VERSION ""

NS_ :

BS_:

BU_: HCM_FD IPMA_ADAS PSCM_FD ABS_ESC TCCM_FD TCM_DSL_FD PCM_HEV_FD PCM_FD ECM_Diesel GENERIC_GWMWakeup GWM_ECG _delete TSTR

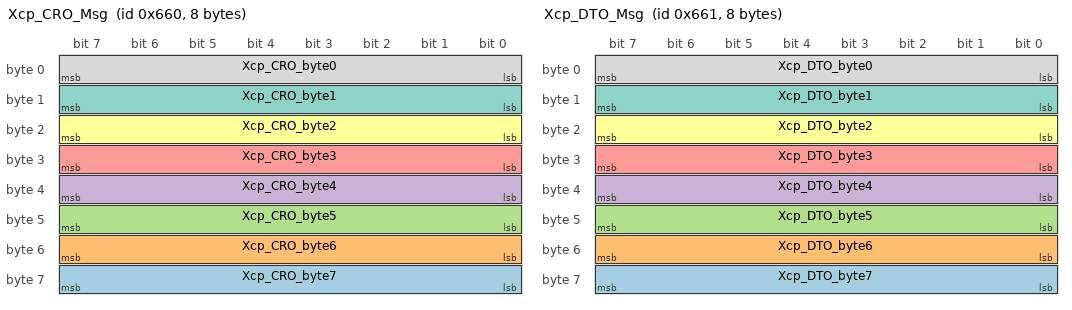
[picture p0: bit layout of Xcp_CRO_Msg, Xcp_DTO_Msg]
BO_ 1632 Xcp_CRO_Msg: 8 Vector__XXX
 SG_ Xcp_CRO_byte7 : 63|8@0- (1,0) [0|255] ""  PSCM_FD
 SG_ Xcp_CRO_byte6 : 55|8@0- (1,0) [0|255] ""  PSCM_FD
 SG_ Xcp_CRO_byte5 : 47|8@0- (1,0) [0|255] ""  PSCM_FD
 SG_ Xcp_CRO_byte4 : 39|8@0- (1,0) [0|255] ""  PSCM_FD
 SG_ Xcp_CRO_byte3 : 31|8@0- (1,0) [0|255] ""  PSCM_FD
 SG_ Xcp_CRO_byte2 : 23|8@0- (1,0) [0|255] ""  PSCM_FD
 SG_ Xcp_CRO_byte1 : 15|8@0- (1,0) [0|255] ""  PSCM_FD
 SG_ Xcp_CRO_byte0 : 7|8@0- (1,0) [0|255] ""  PSCM_FD

BO_ 1633 Xcp_DTO_Msg: 8 PSCM_FD
 SG_ Xcp_DTO_byte7 : 63|8@0- (1,0) [0|255] "" Vector__XXX
 SG_ Xcp_DTO_byte6 : 55|8@0- (1,0) [0|255] "" Vector__XXX
 SG_ Xcp_DTO_byte5 : 47|8@0- (1,0) [0|255] "" Vector__XXX
 SG_ Xcp_DTO_byte4 : 39|8@0- (1,0) [0|255] "" Vector__XXX
 SG_ Xcp_DTO_byte3 : 31|8@0- (1,0) [0|255] "" Vector__XXX
 SG_ Xcp_DTO_byte2 : 23|8@0- (1,0) [0|255] "" Vector__XXX
 SG_ Xcp_DTO_byte1 : 15|8@0- (1,0) [0|255] "" Vector__XXX
 SG_ Xcp_DTO_byte0 : 7|8@0- (1,0) [0|255] "" Vector__XXX

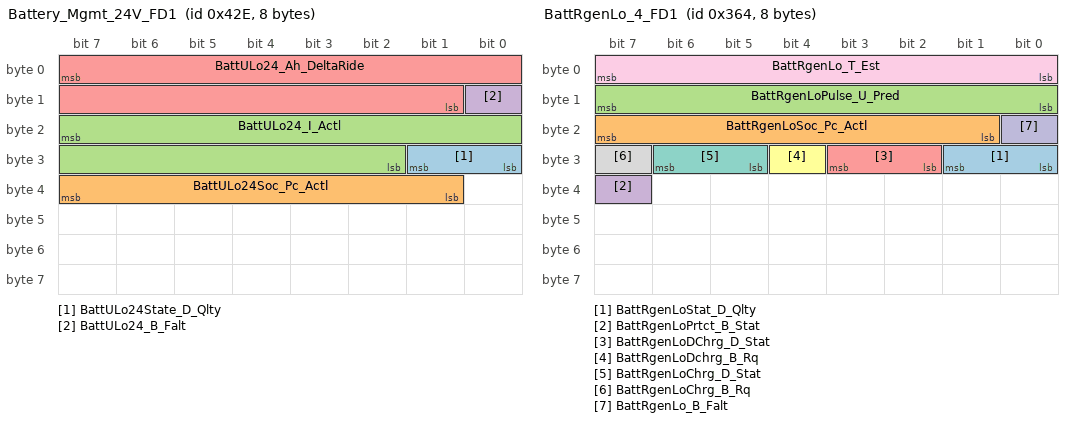
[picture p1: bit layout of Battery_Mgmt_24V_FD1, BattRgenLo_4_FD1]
BO_ 1070 Battery_Mgmt_24V_FD1: 8 GWM_ECG
 SG_ BattULo24State_D_Qlty : 25|2@0+ (1,0) [0|3] "SE"  PCM_FD
 SG_ BattULo24Soc_Pc_Actl : 39|7@0+ (1,0) [0|127] "percent"  PCM_FD
 SG_ BattULo24_I_Actl : 23|14@0+ (0.0625,-512) [-512|511.875] "ampere"  PCM_FD
 SG_ BattULo24_B_Falt : 8|1@0+ (1,0) [0|1] "SED"  PCM_FD
 SG_ BattULo24_Ah_DeltaRide : 7|15@0+ (0.0078125,-100) [-100|155.9921875] "amperehour"  PCM_FD

BO_ 868 BattRgenLo_4_FD1: 8 GWM_ECG
 SG_ BattRgenLoStat_D_Qlty : 25|2@0+ (1,0) [0|3] "SED" Vector__XXX
 SG_ BattRgenLoSoc_Pc_Actl : 23|7@0+ (1,0) [0|100] "percent" Vector__XXX
 SG_ BattRgenLoPulse_U_Pred : 15|8@0+ (0.0625,0) [0|15.9375] "volt" Vector__XXX
 SG_ BattRgenLoPrtct_B_Stat : 39|1@0+ (1,0) [0|1] "SED" Vector__XXX
 SG_ BattRgenLoDChrg_D_Stat : 27|2@0+ (1,0) [0|3] "SED" Vector__XXX
 SG_ BattRgenLoDchrg_B_Rq : 28|1@0+ (1,0) [0|1] "SED" Vector__XXX
 SG_ BattRgenLoChrg_D_Stat : 30|2@0+ (1,0) [0|3] "SED" Vector__XXX
 SG_ BattRgenLoChrg_B_Rq : 31|1@0+ (1,0) [0|1] "SED" Vector__XXX
 SG_ BattRgenLo_T_Est : 7|8@0+ (8,0) [0|2040] "second" Vector__XXX
 SG_ BattRgenLo_B_Falt : 16|1@0+ (1,0) [0|1] "SED" Vector__XXX

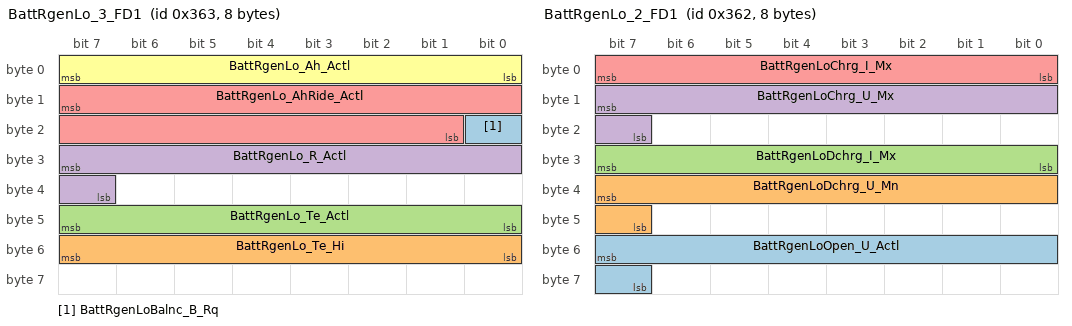
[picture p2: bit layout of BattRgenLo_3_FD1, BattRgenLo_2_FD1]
BO_ 867 BattRgenLo_3_FD1: 8 GWM_ECG
 SG_ BattRgenLoBalnc_B_Rq : 16|1@0+ (1,0) [0|1] "SED" Vector__XXX
 SG_ BattRgenLo_Te_Hi : 55|8@0+ (1,-20) [-20|235] "degC" Vector__XXX
 SG_ BattRgenLo_Te_Actl : 47|8@0+ (1,-60) [-60|194] "degC" Vector__XXX
 SG_ BattRgenLo_R_Actl : 31|9@0+ (0.0625,0) [0|31.9375] "milliohm" Vector__XXX
 SG_ BattRgenLo_AhRide_Actl : 15|15@0+ (0.0078125,-100) [-100|155.9921875] "amperehour" Vector__XXX
 SG_ BattRgenLo_Ah_Actl : 7|8@0+ (0.1,0) [0|25.5] "amperehour" Vector__XXX

BO_ 866 BattRgenLo_2_FD1: 8 GWM_ECG
 SG_ BattRgenLoOpen_U_Actl : 55|9@0+ (0.025,8.5) [8.5|21.275] "volt" Vector__XXX
 SG_ BattRgenLoDchrg_U_Mn : 39|9@0+ (0.025,4) [4|16.775] "volt" Vector__XXX
 SG_ BattRgenLoDchrg_I_Mx : 31|8@0+ (2,0) [0|510] "ampere" Vector__XXX
 SG_ BattRgenLoChrg_U_Mx : 15|9@0+ (0.025,10.6) [10.6|23.375] "volt" Vector__XXX
 SG_ BattRgenLoChrg_I_Mx : 7|8@0+ (2,0) [0|510] "ampere" Vector__XXX

BO_ 865 BattRgenLo_1_FD1: 8 GWM_ECG
 SG_ BattRgenLo_U_Actl : 23|11@0+ (0.015625,0) [0|31.96875] "volt" Vector__XXX
 SG_ BattRgenLo_I_Actl : 7|16@0+ (0.015625,-512) [-512|511.96875] "ampere" Vector__XXX

BO_ 878 DCACA_Data4: 8 PCM_HEV_FD
 SG_ DcacOn_B_Rq : 4|1@0+ (1,0) [0|1] "SED"  GWM_ECG
 SG_ DcacSys_B_Falt : 5|1@0+ (1,0) [0|1] "SED"  GWM_ECG
 SG_ DcacLedCtl_D_Rq : 7|2@0+ (1,0) [0|3] "SED"  GWM_ECG

BO_ 924 DCACA_Data3_FD1: 8 GWM_ECG
 SG_ DcacOut_Pw_Mx : 34|11@0+ (5,0) [0|10225] "watts"  PCM_HEV_FD,PCM_FD
 SG_ DcacOut2_Pw_Actl : 31|13@0+ (1,0) [0|8189] "watts"  PCM_HEV_FD,PCM_FD
 SG_ DcacOut1_Pw_Actl : 12|13@0+ (1,0) [0|8189] "watts"  PCM_HEV_FD,PCM_FD
 SG_ DcacIn_Pw_Mx : 7|11@0+ (5,0) [0|10225] "watts"  PCM_HEV_FD,PCM_FD

BO_ 923 DCACA_Data2_FD1: 8 GWM_ECG
 SG_ DcacIn_U_Actl : 19|12@0+ (0.1,0) [0|409.3] "volt"  PCM_HEV_FD,PCM_FD
 SG_ DcacIn_I_Actl : 15|11@0+ (5,0) [0|10225] "watts"  PCM_HEV_FD,PCM_FD
 SG_ Dcac_Te_Actl : 7|8@0+ (1,-60) [-60|193] "degC"  PCM_HEV_FD,PCM_FD

BO_ 922 DCACA_Data1_FD1: 8 GWM_ECG
 SG_ DcacRdy_D_Stat : 2|3@0+ (1,0) [0|7] "SED"  PCM_HEV_FD,PCM_FD
 SG_ DcacPlugPrsnt_B_Stat : 3|1@0+ (1,0) [0|1] "SED"  PCM_HEV_FD,PCM_FD
 SG_ DcacClntFlw_D_Rq : 5|2@0+ (1,0) [0|3] "SED" Vector__XXX
 SG_ CoolFanDcac_D_Rq : 7|2@0+ (1,0) [0|3] "SED" Vector__XXX

BO_ 2030 TesterPhysicalResSOBDMCFD1: 64 ECM_Diesel
 SG_ TesterPhysicalResSOBDMC : 7|64@0+ (1,0) [0|1.84467E+019] "unitless"  TSTR

BO_ 1137 Cluster_HEV_Data10_FD1: 8 PCM_HEV_FD
 SG_ RngPerChrgAvg_L_Dsply : 7|12@0+ (0.1,0) [0|409.3] "km"  GWM_ECG

BO_ 1090 MtrTrac_Data2_FD1: 8 PCM_HEV_FD
 SG_ VehElRnge_L_Dsply : 28|12@0+ (0.1,0) [0|409.3] "kilometer"  GWM_ECG

BO_ 872 Cluster_HEV_Data5_FD1: 8 PCM_HEV_FD
 SG_ PlgActvArb_B_Dsply : 51|1@0+ (1,0) [0|1] "SED"  GWM_ECG
 SG_ HybMdeStat_D_Dsply : 39|3@0+ (1,0) [0|7] "SED"  GWM_ECG

BO_ 870 Cluster_HEV_Data3_FD1: 8 PCM_HEV_FD
 SG_ RngPerChrgInst_L_Dsply : 45|12@0+ (0.1,0) [0|409.3] "km"  GWM_ECG

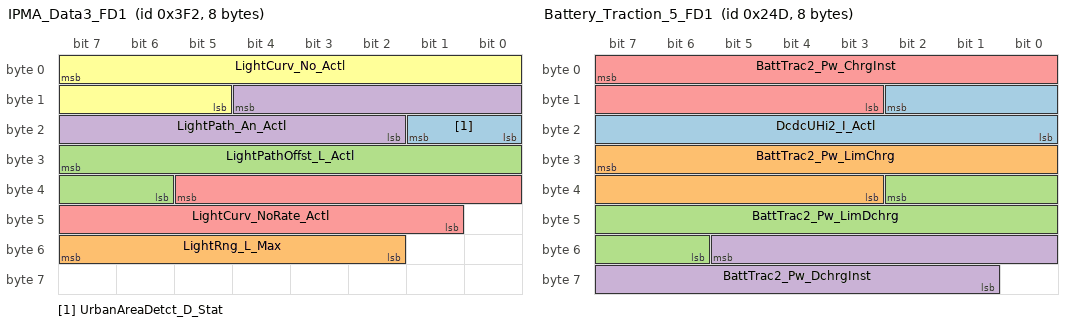
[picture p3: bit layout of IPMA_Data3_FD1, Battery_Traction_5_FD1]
BO_ 1010 IPMA_Data3_FD1: 8 IPMA_ADAS
 SG_ UrbanAreaDetct_D_Stat : 17|2@0+ (1,0) [0|3] "SED"  HCM_FD
 SG_ LightRng_L_Max : 55|6@0+ (2,0) [0|126] "meter"  HCM_FD
 SG_ LightPathOffst_L_Actl : 31|10@0+ (0.01,-5.12) [-5.12|5.11] "meter"  HCM_FD
 SG_ LightPath_An_Actl : 12|11@0+ (0.0005,-0.5) [-0.5|0.5235] "radians"  HCM_FD
 SG_ LightCurv_NoRate_Actl : 37|13@0+ (2.5E-007,-0.001024) [-0.001024|0.00102375] "1/meter"  HCM_FD
 SG_ LightCurv_No_Actl : 7|11@0+ (2E-005,-0.02) [-0.02|0.02094] "1/meter"  HCM_FD

BO_ 589 Battery_Traction_5_FD1: 8 GWM_ECG
 SG_ DcdcUHi2_I_Actl : 10|11@0+ (0.1,0) [0|204.6] "ampere" Vector__XXX
 SG_ BattTrac2_Pw_LimChrg : 31|13@0+ (50,0) [0|409550] "watts"  PCM_HEV_FD
 SG_ BattTrac2_Pw_LimDchrg : 34|13@0+ (50,0) [0|409550] "watts"  PCM_HEV_FD
 SG_ BattTrac2_Pw_DchrgInst : 53|13@0+ (50,0) [0|409550] "watts"  PCM_HEV_FD
 SG_ BattTrac2_Pw_ChrgInst : 7|13@0+ (50,0) [0|409550] "watts"  PCM_HEV_FD

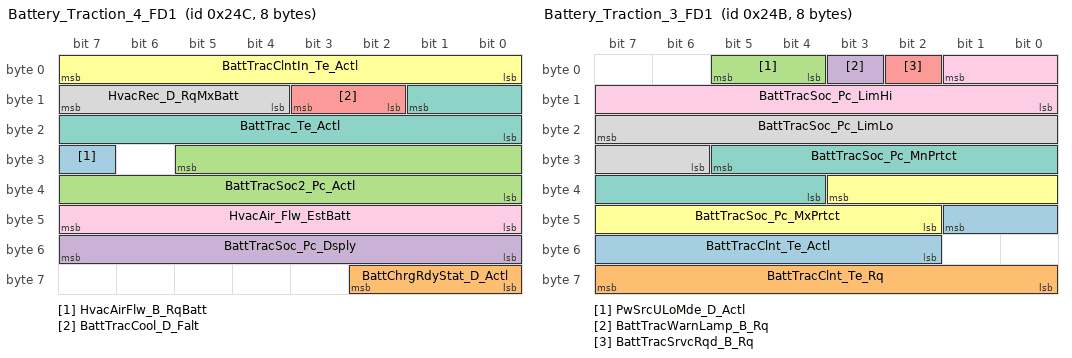
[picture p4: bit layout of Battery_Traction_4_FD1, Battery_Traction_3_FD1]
BO_ 588 Battery_Traction_4_FD1: 8 GWM_ECG
 SG_ HvacAirFlw_B_RqBatt : 31|1@0+ (1,0) [0|1] "SED" Vector__XXX
 SG_ BattChrgRdyStat_D_Actl : 58|3@0+ (1,0) [0|7] "SED" Vector__XXX
 SG_ BattTracSoc2_Pc_Actl : 29|14@0+ (0.01,0) [0|163.81] "%"  PCM_HEV_FD
 SG_ BattTracSoc_Pc_Dsply : 55|8@0+ (0.5,0) [0|126.5] "Percent" Vector__XXX
 SG_ BattTracCool_D_Falt : 11|2@0+ (1,0) [0|3] "SED" Vector__XXX
 SG_ BattTracClntIn_Te_Actl : 7|8@0+ (1,-50) [-50|204] "degC" Vector__XXX
 SG_ BattTrac_Te_Actl : 9|10@0+ (0.5,-50) [-50|460.5] "degC"  PCM_HEV_FD
 SG_ HvacRec_D_RqMxBatt : 15|4@0+ (1,0) [0|15] "SED" Vector__XXX
 SG_ HvacAir_Flw_EstBatt : 47|8@0+ (0.5,0) [0|127] "liter/second" Vector__XXX

BO_ 587 Battery_Traction_3_FD1: 8 GWM_ECG
 SG_ BattTracClnt_Te_Actl : 41|8@0+ (0.5,-60) [-60|67.5] "degC" Vector__XXX
 SG_ BattTracClnt_Te_Rq : 63|8@0+ (0.5,-60) [-60|67.5] "degC" Vector__XXX
 SG_ PwSrcULoMde_D_Actl : 5|2@0+ (1,0) [0|3] "SED" Vector__XXX
 SG_ BattTracWarnLamp_B_Rq : 3|1@0+ (1,0) [0|1] "SED" Vector__XXX
 SG_ BattTracSrvcRqd_B_Rq : 2|1@0+ (1,0) [0|1] "SED" Vector__XXX
 SG_ BattTracSoc_Pc_MxPrtct : 35|10@0+ (0.1,0) [0|100] "%"  PCM_HEV_FD
 SG_ BattTracSoc_Pc_MnPrtct : 29|10@0+ (0.1,0) [0|100] "%"  PCM_HEV_FD
 SG_ BattTracSoc_Pc_LimLo : 23|10@0+ (0.1,0) [0|100] "%"  PCM_HEV_FD
 SG_ BattTracSoc_Pc_LimHi : 1|10@0+ (0.1,0) [0|100] "%"  PCM_HEV_FD

BO_ 1116 TrailerAid_Data3_FD1: 8 GWM_ECG
 SG_ TrlrAidSetup_D2_Rq : 4|4@0+ (1,0) [0|15] "SED"  IPMA_ADAS,PSCM_FD
 SG_ TrlrAidEnbl_D2_Rq : 7|3@0+ (1,0) [0|7] "SED"  PSCM_FD,IPMA_ADAS

BO_ 1844 TesterPhysicalReqHCM_FD1: 64 TSTR
 SG_ TesterPhysicalReqHCM : 7|64@0+ (1,0) [0|1.84467E+019] "unitless"  HCM_FD

BO_ 954 Body_Info_10_FD1: 8 GWM_ECG
 SG_ GenericSwtch3_No_Actl : 15|3@0+ (1,0) [0|7] "unitless"  HCM_FD
 SG_ GenericSwtch2_No_Actl : 4|3@0+ (1,0) [0|7] "unitless"  HCM_FD
 SG_ GenericSwtch1_No_Actl : 7|3@0+ (1,0) [0|7] "unitless"  HCM_FD

BO_ 1852 TesterPhysicalResHCM_FD1: 64 HCM_FD
 SG_ TesterPhysicalResHCM : 7|64@0+ (1,0) [0|1.84467E+019] "unitless"  TSTR

BO_ 989 Personality_HCM_FD1_Data: 8 HCM_FD
 SG_ FeatNoHcm_No_Actl : 23|16@0+ (1,0) [0|65535] "Number"  GWM_ECG
 SG_ FeatConfigHcmActl : 7|16@0+ (1,0) [0|65535] "Undefined"  GWM_ECG

BO_ 1006 Personality_IPMB_Data_FD1: 8 IPMA_ADAS
 SG_ PersIndexIpmb_D_Actl : 39|3@0+ (1,0) [0|7] "SED"  GWM_ECG
 SG_ FeatNoIpmbActl : 23|16@0+ (1,0) [0|65535] "Number"  GWM_ECG
 SG_ FeatConfigIpmbActl : 7|16@0+ (1,0) [0|65535] "Undefined"  GWM_ECG

BO_ 992 Personality_Data_FD1: 8 GWM_ECG
 SG_ MsgCntrPersIndex_D_Rq : 39|3@0+ (1,0) [0|7] "SED"  IPMA_ADAS,HCM_FD
 SG_ MsgCntrFeatConfigRq : 23|16@0+ (1,0) [0|65535] "unitless"  HCM_FD,IPMA_ADAS
 SG_ MsgCntrFeatNoRq : 7|16@0+ (1,0) [0|65535] "Number"  IPMA_ADAS,HCM_FD
 SG_ MsgCntrDsplyOp_D_Rq : 36|3@0+ (1,0) [0|7] "SED"  HCM_FD,IPMA_ADAS

BO_ 820 Adaptive_Headlamp_Stat_FD1: 8 HCM_FD
 SG_ AhbStatGfhbFdbk_D_Actl : 53|2@0+ (1,0) [0|3] "SED"  IPMA_ADAS
 SG_ HeadLghtDrvSide_B_Stat : 33|1@0+ (1,0) [0|1] "SED"  IPMA_ADAS
 SG_ HeadLghtHiOn_B_StatHcm : 0|1@0+ (1,0) [0|1] "SED"  GWM_ECG
 SG_ Adaptive_Hdlmp_Fault : 7|1@0+ (1,0) [0|1] "SED"  GWM_ECG,IPMA_ADAS

BO_ 1630 TesterPhysicalReqPSCM_FD1: 64 TSTR
 SG_ TesterPhysicalReqPSCM : 7|64@0+ (1,0) [0|1.84467E+019] "unitless"  PSCM_FD

BO_ 1713 ABS_Rapid_Data_Resp_2_FD1: 8 ABS_ESC
 SG_ UUDTABSResponse2 : 7|64@0+ (1,0) [0|1.844674407371E+019] "unitless"  GWM_ECG,TSTR

BO_ 1712 ABS_Rapid_Data_Resp_1_FD1: 8 ABS_ESC
 SG_ UUDTABSResponse1 : 7|64@0+ (1,0) [0|1.844674407371E+019] "unitless"  GWM_ECG,TSTR

BO_ 2025 TesterPhysicalResTCM_FD1: 64 TCM_DSL_FD
 SG_ TesterPhysicalResTCM : 7|64@0+ (1,0) [0|1.84467E+019] "unitless"  TSTR

BO_ 2024 TesterPhysicalResPCM_FD1: 64 PCM_HEV_FD
 SG_ TesterPhysicalResPCM : 7|64@0+ (1,0) [0|1.84467E+019] "unitless"  TSTR

BO_ 2017 TesterPhysicalReqTCM_FD1: 64 TSTR
 SG_ TesterPhysicalReqTCM : 7|64@0+ (1,0) [0|1.84467E+019] "unitless"  TCM_DSL_FD

BO_ 2016 TesterPhysicalReqPCM_FD1: 64 TSTR
 SG_ TesterPhysicalReqPCM : 7|64@0+ (1,0) [0|1.84467E+019] "unitless"  ECM_Diesel,PCM_FD,PCM_HEV_FD

BO_ 1759 TesterFunctionalReq_FD1: 64 TSTR
 SG_ TesterFunctionalReq : 7|64@0+ (1,0) [0|1.84467E+019] ""  HCM_FD,IPMA_ADAS,ECM_Diesel,PCM_FD,PCM_HEV_FD,TCCM_FD,TCM_DSL_FD,GWM_ECG,PSCM_FD,ABS_ESC

BO_ 1897 TesterPhysicalResTCCM_FD1: 64 TCCM_FD
 SG_ TesterPhysicalResTCCM : 7|64@0+ (1,0) [0|1.84467E+019] "unitless"  TSTR

BO_ 1814 TesterPhysicalReqGWM_FD1: 64 TSTR
 SG_ TesterPhysicalReqGWM_H1 : 7|64@0+ (1,0) [0|1.84467E+019] "unitless"  GWM_ECG

BO_ 1701 TCM_Rapid_Data_Resp_2_FD1: 8 TCM_DSL_FD
 SG_ UUDTTCMResponse2 : 7|64@0+ (1,0) [0|1.844674407371E+019] "unitless"  GWM_ECG,TSTR

BO_ 1700 TCM_Rapid_Data_Resp_1_FD1: 8 TCM_DSL_FD
 SG_ UUDTTCMResponse1 : 7|64@0+ (1,0) [0|1.844674407371E+019] "unitless"  GWM_ECG,TSTR

BO_ 1697 PCM_Rapid_Data_Resp_2_FD1: 8 PCM_HEV_FD
 SG_ UUDTPCMResponse2 : 7|64@0+ (1,0) [0|1.844674407371E+019] "unitless"  TSTR

BO_ 1696 PCM_Rapid_Data_Resp_1_FD1: 8 PCM_HEV_FD
 SG_ UUDTPCMResponse1 : 7|64@0+ (1,0) [0|1.844674407371E+019] "unitless"  TSTR

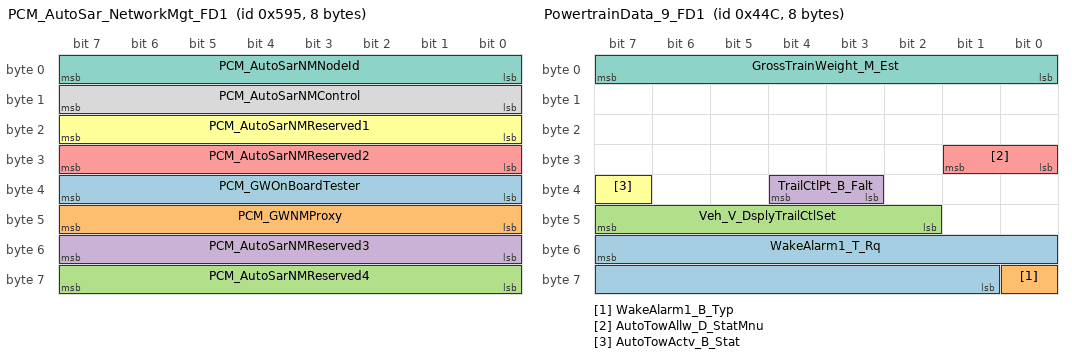
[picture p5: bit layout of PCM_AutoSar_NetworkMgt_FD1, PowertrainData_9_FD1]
BO_ 1429 PCM_AutoSar_NetworkMgt_FD1: 8 PCM_HEV_FD
 SG_ PCM_GWOnBoardTester : 39|8@0+ (1,0) [0|255] "unitless"  TCM_DSL_FD
 SG_ PCM_GWNMProxy : 47|8@0+ (1,0) [0|255] "unitless"  TCM_DSL_FD
 SG_ PCM_AutoSarNMReserved4 : 63|8@0+ (1,0) [0|255] "unitless"  TCM_DSL_FD
 SG_ PCM_AutoSarNMReserved3 : 55|8@0+ (1,0) [0|255] "unitless"  TCM_DSL_FD
 SG_ PCM_AutoSarNMReserved2 : 31|8@0+ (1,0) [0|255] "unitless"  TCM_DSL_FD
 SG_ PCM_AutoSarNMReserved1 : 23|8@0+ (1,0) [0|255] "unitless"  TCM_DSL_FD
 SG_ PCM_AutoSarNMNodeId : 7|8@0+ (1,0) [0|255] "unitless"  TCM_DSL_FD
 SG_ PCM_AutoSarNMControl : 15|8@0+ (1,0) [0|255] "unitless"  TCM_DSL_FD

BO_ 1100 PowertrainData_9_FD1: 8 PCM_HEV_FD
 SG_ WakeAlarm1_T_Rq : 55|15@0+ (1,0) [0|32767] "minute"  GWM_ECG
 SG_ WakeAlarm1_B_Typ : 56|1@0+ (1,0) [0|1] "SED"  GWM_ECG
 SG_ Veh_V_DsplyTrailCtlSet : 47|6@0+ (0.5,0) [0|31] "unitless"  GWM_ECG
 SG_ TrailCtlPt_B_Falt : 36|2@0+ (1,0) [0|3] "SED"  ABS_ESC,GWM_ECG
 SG_ AutoTowAllw_D_StatMnu : 25|2@0+ (1,0) [0|3] "SED"  GWM_ECG
 SG_ AutoTowActv_B_Stat : 39|1@0+ (1,0) [0|1] "SED"  IPMA_ADAS,GWM_ECG
 SG_ GrossTrainWeight_M_Est : 7|8@0+ (100,0) [0|25300] "kilogram"  IPMA_ADAS,TCCM_FD,TCM_DSL_FD,GWM_ECG

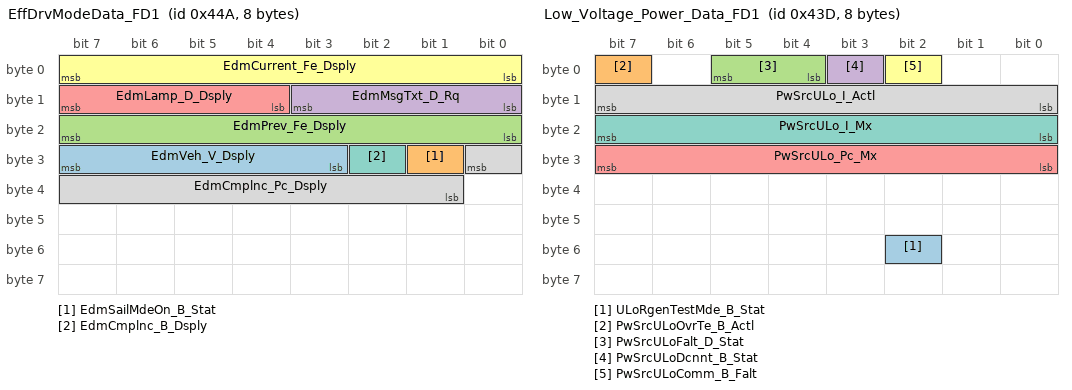
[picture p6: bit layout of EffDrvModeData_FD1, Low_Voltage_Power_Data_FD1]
BO_ 1098 EffDrvModeData_FD1: 8 ECM_Diesel
 SG_ EdmVeh_V_Dsply : 31|5@0+ (5,0) [0|155] "km/h"  GWM_ECG
 SG_ EdmSailMdeOn_B_Stat : 25|1@0+ (1,0) [0|1] "SED"  GWM_ECG
 SG_ EdmPrev_Fe_Dsply : 23|8@0+ (0.1,0) [0|25.5] "litre/100km"  GWM_ECG
 SG_ EdmMsgTxt_D_Rq : 11|4@0+ (1,0) [0|15] "SED"  GWM_ECG
 SG_ EdmLamp_D_Dsply : 15|4@0+ (1,0) [0|15] "SED"  GWM_ECG
 SG_ EdmCurrent_Fe_Dsply : 7|8@0+ (0.1,0) [0|25.5] "litre/100km"  GWM_ECG
 SG_ EdmCmplnc_B_Dsply : 26|1@0+ (1,0) [0|1] "SED"  GWM_ECG
 SG_ EdmCmplnc_Pc_Dsply : 24|8@0+ (0.392157,0) [0|100.000035] "percent"  GWM_ECG

BO_ 1086 PowertrainData_3_FD1: 8 PCM_HEV_FD
 SG_ EngMnfld_P_Actl : 47|13@0+ (0.1,-206.8) [-206.8|612.3] "kilopascal"  GWM_ECG
 SG_ FuelPumpPwr_B_Rq : 20|1@0+ (1,0) [0|1] "SED"  GWM_ECG
 SG_ BattULoChrg_U_Cmd : 15|8@0+ (0.025,10.6) [10.6|16.975] "volt"  GWM_ECG
 SG_ ElLoadCtl_D_Rq : 23|3@0+ (1,0) [0|7] "SED"  GWM_ECG

BO_ 1085 Low_Voltage_Power_Data_FD1: 8 PCM_FD
 SG_ ULoRgenTestMde_B_Stat : 50|1@0+ (1,0) [0|1] "SED"  GWM_ECG
 SG_ PwSrcULoOvrTe_B_Actl : 7|1@0+ (1,0) [0|1] "SED"  GWM_ECG
 SG_ PwSrcULoFalt_D_Stat : 5|2@0+ (1,0) [0|3] "SED"  GWM_ECG
 SG_ PwSrcULoDcnnt_B_Stat : 3|1@0+ (1,0) [0|1] "SED"  GWM_ECG
 SG_ PwSrcULo_Pc_Mx : 31|8@0+ (0.4,0) [0|101.6] "%"  GWM_ECG
 SG_ PwSrcULoComm_B_Falt : 2|1@0+ (1,0) [0|1] "SED"  GWM_ECG
 SG_ PwSrcULo_I_Mx : 23|8@0+ (1,0) [0|254] "ampere"  PCM_HEV_FD,GWM_ECG
 SG_ PwSrcULo_I_Actl : 15|8@0+ (1,0) [0|254] "ampere"  PCM_HEV_FD,GWM_ECG

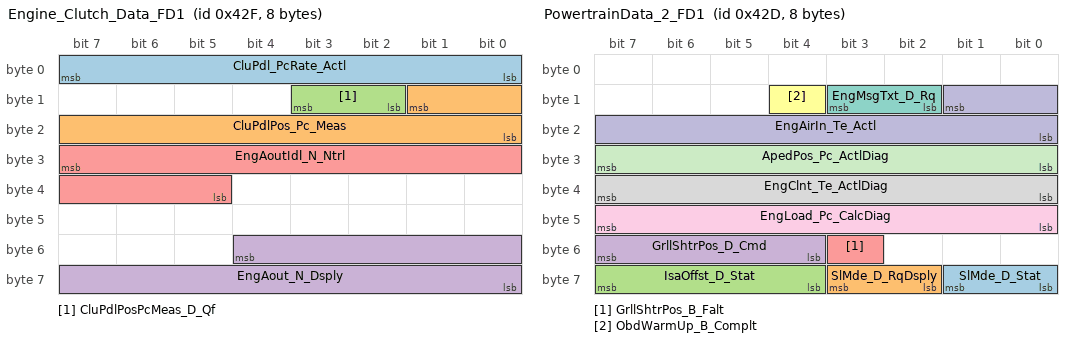
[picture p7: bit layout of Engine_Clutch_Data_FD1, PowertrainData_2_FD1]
BO_ 1071 Engine_Clutch_Data_FD1: 8 PCM_HEV_FD
 SG_ CluPdl_PcRate_Actl : 7|8@0+ (0.04,-5) [-5|5.2] "%/ms"  GWM_ECG
 SG_ CluPdlPos_Pc_Meas : 9|10@0+ (0.1,0) [0|102.3] "%"  GWM_ECG,HCM_FD
 SG_ CluPdlPosPcMeas_D_Qf : 11|2@0+ (1,0) [0|3] "SED"  GWM_ECG,HCM_FD
 SG_ EngAout_N_Dsply : 52|13@0+ (2,0) [0|16382] "rpm"  GWM_ECG
 SG_ EngAoutIdl_N_Ntrl : 31|11@0+ (2,0) [0|4094] "rpm"  ABS_ESC,GWM_ECG

BO_ 1069 PowertrainData_2_FD1: 8 PCM_HEV_FD
 SG_ SlMde_D_Stat : 57|2@0+ (1,0) [0|3] "SED"  GWM_ECG
 SG_ SlMde_D_RqDsply : 59|2@0+ (1,0) [0|3] "SED"  GWM_ECG
 SG_ IsaOffst_D_Stat : 63|4@0+ (1,0) [0|15] "SED"  GWM_ECG
 SG_ GrllShtrPos_D_Cmd : 55|4@0+ (1,0) [0|15] "SED"  GWM_ECG
 SG_ GrllShtrPos_B_Falt : 51|1@0+ (1,0) [0|1] "SED"  GWM_ECG
 SG_ ObdWarmUp_B_Complt : 12|1@0+ (1,0) [0|1] "SED"  GWM_ECG
 SG_ EngMsgTxt_D_Rq : 11|2@0+ (1,0) [0|3] "SED"  GWM_ECG
 SG_ EngClnt_Te_ActlDiag : 39|8@0+ (1,-40) [-40|215] "degC"  TCM_DSL_FD,GWM_ECG
 SG_ EngLoad_Pc_CalcDiag : 47|8@0+ (0.392157,0) [0|100.000035] "%"  TCM_DSL_FD,GWM_ECG
 SG_ EngAirIn_Te_Actl : 9|10@0+ (0.25,-128) [-128|127.25] "degC"  GWM_ECG,TCM_DSL_FD
 SG_ ApedPos_Pc_ActlDiag : 31|8@0+ (0.392157,0) [0|100.000035] "%"  TCM_DSL_FD,GWM_ECG

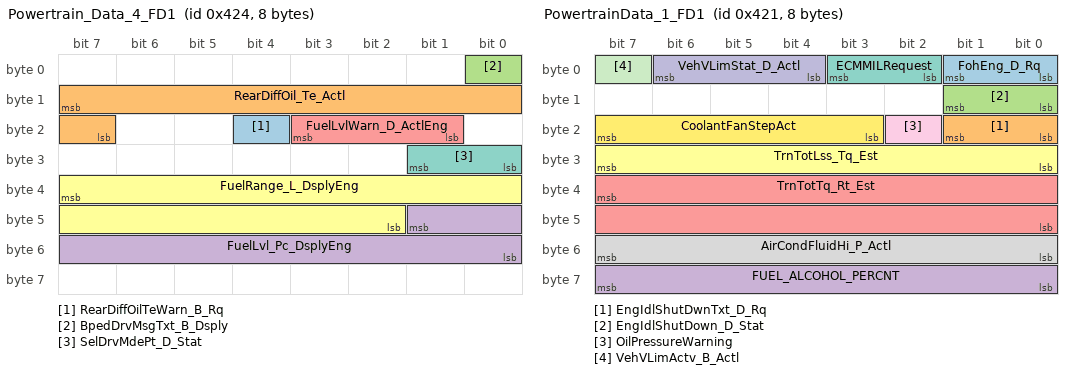
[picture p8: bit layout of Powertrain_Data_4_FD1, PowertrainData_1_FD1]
BO_ 1060 Powertrain_Data_4_FD1: 8 PCM_HEV_FD
 SG_ RearDiffOilTeWarn_B_Rq : 20|1@0+ (1,0) [0|1] "SED"  GWM_ECG
 SG_ RearDiffOil_Te_Actl : 15|9@0+ (1,-40) [-40|470] "degC"  GWM_ECG
 SG_ BpedDrvMsgTxt_B_Dsply : 0|1@0+ (1,0) [0|1] "SED"  GWM_ECG
 SG_ FuelLvl_Pc_DsplyEng : 41|10@0+ (0.108696,-5.217408) [-5.217408|105.9786] "percent"  GWM_ECG
 SG_ FuelLvlWarn_D_ActlEng : 19|3@0+ (1,0) [0|7] "SED"  GWM_ECG
 SG_ FuelRange_L_DsplyEng : 39|14@0+ (0.1,0) [0|1638.3] "kilometer"  GWM_ECG
 SG_ SelDrvMdePt_D_Stat : 25|2@0+ (1,0) [0|3] "SED"  ABS_ESC,GWM_ECG

BO_ 1057 PowertrainData_1_FD1: 8 PCM_HEV_FD
 SG_ FohEng_D_Rq : 1|2@0+ (1,0) [0|3] "SED"  GWM_ECG
 SG_ EngIdlShutDwnTxt_D_Rq : 17|2@0+ (1,0) [0|3] "SED"  GWM_ECG
 SG_ EngIdlShutDown_D_Stat : 9|2@0+ (1,0) [0|3] "SED"  GWM_ECG
 SG_ FUEL_ALCOHOL_PERCNT : 63|8@0+ (0.393700787,0) [0|99.999899898] "Percent"  GWM_ECG
 SG_ TrnTotTq_Rt_Est : 39|16@0+ (0.001,0) [0|65.533] "Unitless"  GWM_ECG
 SG_ TrnTotLss_Tq_Est : 31|8@0+ (0.5,0) [0|126.5] "Nm"  GWM_ECG
 SG_ ECMMILRequest : 3|2@0+ (1,0) [0|3] "SED"  GWM_ECG
 SG_ AirCondFluidHi_P_Actl : 55|8@0+ (0.125,0) [0|31.625] "bar"  GWM_ECG
 SG_ OilPressureWarning : 18|1@0+ (1,0) [0|1] "SED"  GWM_ECG
 SG_ VehVLimStat_D_Actl : 6|3@0+ (1,0) [0|7] "SED"  GWM_ECG,TCM_DSL_FD
 SG_ VehVLimActv_B_Actl : 7|1@0+ (1,0) [0|1] "SED"  GWM_ECG,TCM_DSL_FD
 SG_ CoolantFanStepAct : 23|5@0+ (1,0) [0|31] "Steps"  GWM_ECG

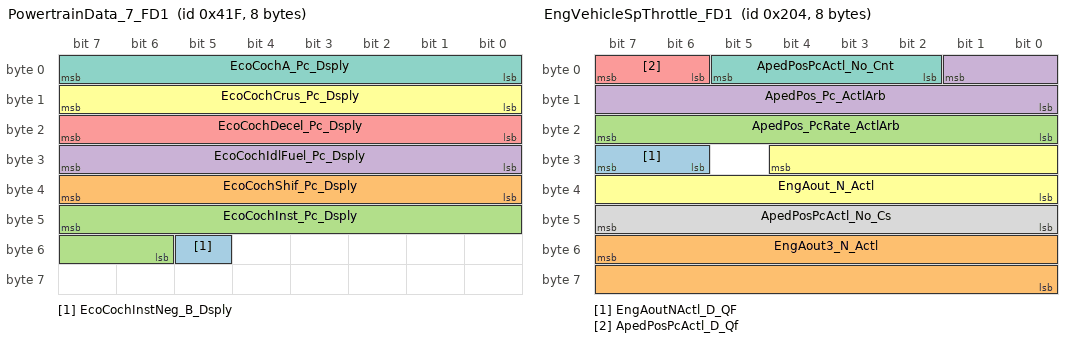
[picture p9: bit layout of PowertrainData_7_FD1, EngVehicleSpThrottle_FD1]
BO_ 1055 PowertrainData_7_FD1: 8 PCM_HEV_FD
 SG_ EcoCochInstNeg_B_Dsply : 53|1@0+ (1,0) [0|1] "SED"  GWM_ECG
 SG_ EcoCochShif_Pc_Dsply : 39|8@0+ (0.392157,0) [0|100.000035] "percent"  GWM_ECG
 SG_ EcoCochInst_Pc_Dsply : 47|10@0+ (0.1,0) [0|102.3] "percent"  GWM_ECG
 SG_ EcoCochIdlFuel_Pc_Dsply : 31|8@0+ (0.392157,0) [0|100.000035] "percent"  GWM_ECG
 SG_ EcoCochDecel_Pc_Dsply : 23|8@0+ (0.392157,0) [0|100.000035] "percent"  GWM_ECG
 SG_ EcoCochCrus_Pc_Dsply : 15|8@0+ (0.392157,0) [0|100.000035] "percent"  GWM_ECG
 SG_ EcoCochA_Pc_Dsply : 7|8@0+ (0.392157,0) [0|100.000035] "percent"  GWM_ECG

BO_ 562 PowertrainData_11_FD1: 8 ECM_Diesel
 SG_ GearNtrl_No_Cs : 15|8@0+ (1,0) [0|255] "unitless"  GWM_ECG
 SG_ GearNtrl_No_Cnt : 5|4@0+ (1,0) [0|15] "unitless"  IPMA_ADAS,GWM_ECG
 SG_ GearNtrl_D_Stat : 7|2@0+ (1,0) [0|3] "SED"  GWM_ECG

BO_ 523 Engine_Data_18_FD1: 8 ECM_Diesel
 SG_ UreaMxAdd_L2_Actl : 47|9@0+ (0.1,0) [0|51] "litre"  GWM_ECG
 SG_ WaterInFuel_B_Falt : 8|1@0+ (1,0) [0|1] "SED"  GWM_ECG
 SG_ UreaMnAdd_L2_Actl : 23|8@0+ (0.1,0) [0|25.4] "litre"  GWM_ECG
 SG_ VehUreaRnge3_L_DsplyMx : 31|16@0+ (1,0) [0|65535] "unitless"  GWM_ECG

BO_ 517 PowertrainData_6_FD1: 8 PCM_HEV_FD
 SG_ TrnAin_Pc_RqDrv : 9|10@0+ (0.1,0) [0|102.3] "percent"  TCCM_FD
 SG_ FapLc_B_Err : 10|1@0+ (1,0) [0|1] "SED"  IPMA_ADAS,GWM_ECG
 SG_ BrkTot_Tq_RqFapLc : 7|13@0+ (4,0) [0|32764] "Nm"  ABS_ESC,GWM_ECG

BO_ 516 EngVehicleSpThrottle_FD1: 8 PCM_HEV_FD
 SG_ EngAoutNActl_D_QF : 31|2@0+ (1,0) [0|3] "SED"  TCM_DSL_FD,GWM_ECG
 SG_ EngAout3_N_Actl : 55|16@0+ (0.25,0) [0|16383.5] "RPM"  GWM_ECG
 SG_ ApedPos_PcRate_ActlArb : 23|8@0+ (0.04,-5) [-5|5.12] "%/ms"  IPMA_ADAS,TCM_DSL_FD,GWM_ECG
 SG_ ApedPos_Pc_ActlArb : 1|10@0+ (0.1,0) [0|102.3] "%"  HCM_FD,IPMA_ADAS,TCCM_FD,ABS_ESC,PSCM_FD,TCM_DSL_FD,GWM_ECG
 SG_ ApedPosPcActl_D_Qf : 7|2@0+ (1,0) [0|3] "SED"  HCM_FD,IPMA_ADAS,ABS_ESC,PSCM_FD,TCM_DSL_FD,GWM_ECG
 SG_ EngAout_N_Actl : 28|13@0+ (2,0) [0|16382] "rpm"  HCM_FD,ABS_ESC,PSCM_FD,TCCM_FD,TCM_DSL_FD,GWM_ECG
 SG_ ApedPosPcActl_No_Cnt : 5|4@0+ (1,0) [0|15] "Unitless"  GWM_ECG
 SG_ ApedPosPcActl_No_Cs : 47|8@0+ (1,0) [0|255] "Unitless"  GWM_ECG

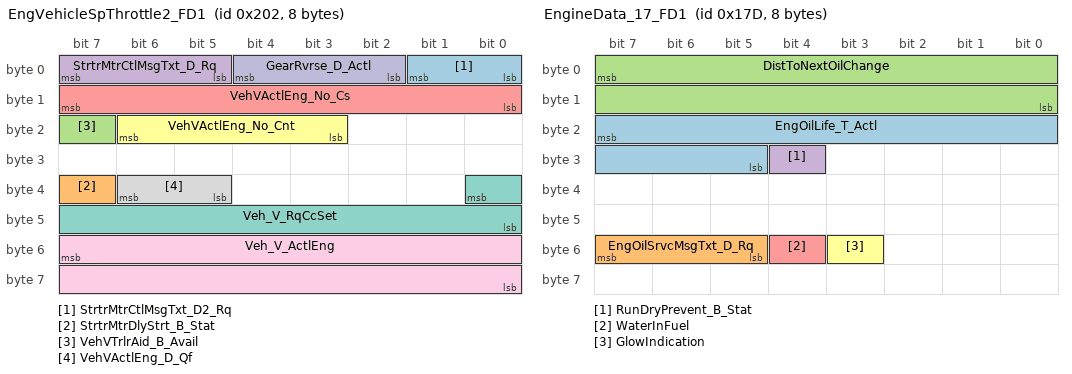
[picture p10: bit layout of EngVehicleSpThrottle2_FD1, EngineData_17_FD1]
BO_ 514 EngVehicleSpThrottle2_FD1: 8 PCM_HEV_FD
 SG_ StrtrMtrCtlMsgTxt_D2_Rq : 1|2@0+ (1,0) [0|3] "SED"  GWM_ECG
 SG_ StrtrMtrDlyStrt_B_Stat : 39|1@0+ (1,0) [0|1] "SED"  GWM_ECG
 SG_ VehVTrlrAid_B_Avail : 23|1@0+ (1,0) [0|1] "SED"  PSCM_FD,GWM_ECG
 SG_ StrtrMtrCtlMsgTxt_D_Rq : 7|3@0+ (1,0) [0|7] "SED"  GWM_ECG
 SG_ VehVActlEng_No_Cs : 15|8@0+ (1,0) [0|255] "Unitless"  PSCM_FD,GWM_ECG
 SG_ VehVActlEng_No_Cnt : 22|4@0+ (1,0) [0|15] "Unitless"  PSCM_FD,GWM_ECG
 SG_ Veh_V_RqCcSet : 32|9@0+ (0.5,0) [0|255.5] "kph"  ABS_ESC,IPMA_ADAS,TCM_DSL_FD,GWM_ECG
 SG_ VehVActlEng_D_Qf : 38|2@0+ (1,0) [0|3] "SED"  HCM_FD,IPMA_ADAS,ABS_ESC,PSCM_FD,TCM_DSL_FD,GWM_ECG
 SG_ Veh_V_ActlEng : 55|16@0+ (0.01,0) [0|655.35] "kph"  HCM_FD,IPMA_ADAS,ABS_ESC,PSCM_FD,TCM_DSL_FD,GWM_ECG
 SG_ GearRvrse_D_Actl : 4|3@0+ (1,0) [0|7] "SED"  IPMA_ADAS,ABS_ESC,PSCM_FD,GWM_ECG

BO_ 512 TorqueDataEngFlags_FD1: 8 PCM_HEV_FD
 SG_ PrplWhlTotTqRq_No_Cs : 63|8@0+ (1,0) [0|255] "Unitless"  ABS_ESC,GWM_ECG
 SG_ PrplWhlTotTqRq_No_Cnt : 51|4@0+ (1,0) [0|15] "Unitless"  ABS_ESC,GWM_ECG
 SG_ PrplWhlTot_Tq_Rq : 39|16@0+ (4,-131072) [-131072|131068] "Nm"  TCCM_FD,ABS_ESC,GWM_ECG
 SG_ PrplWhlTot_Tq_LimMn : 23|16@0+ (4,-131072) [-131072|131068] "Nm"  ABS_ESC,GWM_ECG
 SG_ PtDrvMde_D_Stat : 55|4@0+ (1,0) [0|15] "SED"  IPMA_ADAS,GWM_ECG

BO_ 381 EngineData_17_FD1: 8 ECM_Diesel
 SG_ EngOilLife_T_Actl : 23|11@0+ (1,0) [0|2047] "days"  GWM_ECG
 SG_ EngOilSrvcMsgTxt_D_Rq : 55|3@0+ (1,0) [0|7] "SED"  GWM_ECG
 SG_ DistToNextOilChange : 7|16@0+ (1,0) [0|65535] "unitless"  GWM_ECG
 SG_ RunDryPrevent_B_Stat : 28|1@0+ (1,0) [0|1] "SED"  GWM_ECG
 SG_ WaterInFuel : 52|1@0+ (1,0) [0|1] "SED"  GWM_ECG
 SG_ GlowIndication : 51|1@0+ (1,0) [0|1] "SED"  GWM_ECG

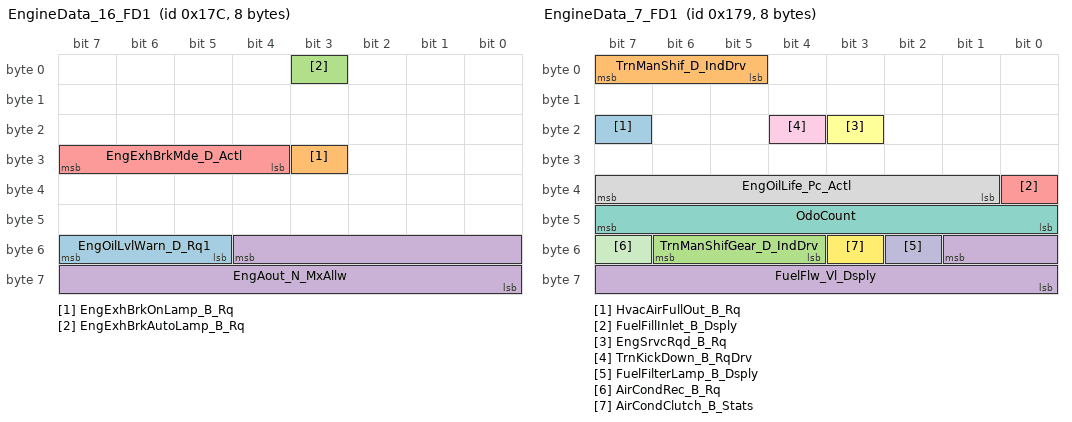
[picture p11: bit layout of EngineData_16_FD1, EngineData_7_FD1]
BO_ 380 EngineData_16_FD1: 8 PCM_FD
 SG_ EngOilLvlWarn_D_Rq1 : 55|3@0+ (1,0) [0|7] "SED"  GWM_ECG
 SG_ EngExhBrkOnLamp_B_Rq : 27|1@0+ (1,0) [0|1] "SED"  GWM_ECG
 SG_ EngExhBrkAutoLamp_B_Rq : 3|1@0+ (1,0) [0|1] "SED"  GWM_ECG
 SG_ EngAout_N_MxAllw : 52|13@0+ (2,0) [0|16382] "rpm"  GWM_ECG
 SG_ EngExhBrkMde_D_Actl : 31|4@0+ (1,0) [0|15] "SED"  TCM_DSL_FD,GWM_ECG

BO_ 377 EngineData_7_FD1: 8 PCM_HEV_FD
 SG_ HvacAirFullOut_B_Rq : 23|1@0+ (1,0) [0|1] "SED"  GWM_ECG
 SG_ TrnManShif_D_IndDrv : 7|3@0+ (1,0) [0|7] "Unitless"  GWM_ECG
 SG_ TrnManShifGear_D_IndDrv : 54|3@0+ (1,0) [0|7] "SED"  GWM_ECG
 SG_ FuelFlw_Vl_Dsply : 49|10@0+ (25,0) [0|25575] "Micro_Liter"  GWM_ECG
 SG_ FuelFillInlet_B_Dsply : 32|1@0+ (1,0) [0|1] "SED"  GWM_ECG
 SG_ EngSrvcRqd_B_Rq : 19|1@0+ (1,0) [0|1] "SED"  GWM_ECG
 SG_ OdoCount : 47|8@0+ (0.2,0) [0|50.8] "Meters"  GWM_ECG
 SG_ EngOilLife_Pc_Actl : 39|7@0+ (1,0) [0|100] "Percent"  GWM_ECG
 SG_ TrnKickDown_B_RqDrv : 20|1@0+ (1,0) [0|1] "SED"  GWM_ECG
 SG_ FuelFilterLamp_B_Dsply : 50|1@0+ (1,0) [0|1] "SED"  GWM_ECG
 SG_ AirCondRec_B_Rq : 55|1@0+ (1,0) [0|1] "SED"  GWM_ECG
 SG_ AirCondClutch_B_Stats : 51|1@0+ (1,0) [0|1] "SED"  GWM_ECG

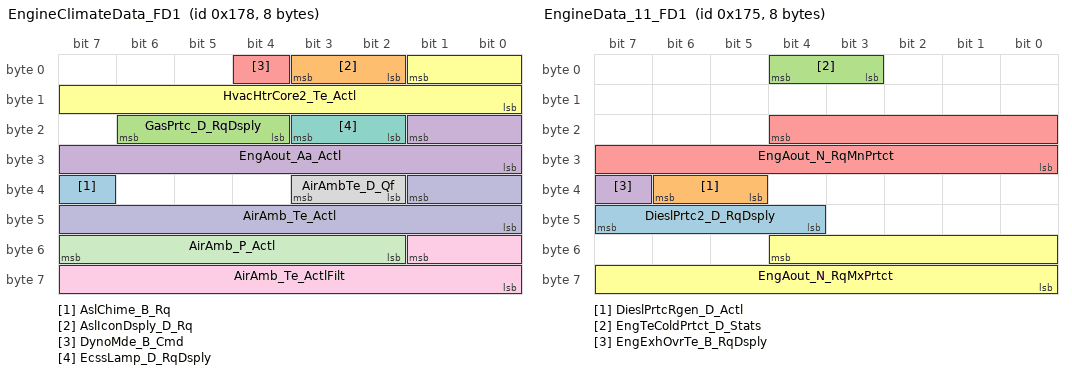
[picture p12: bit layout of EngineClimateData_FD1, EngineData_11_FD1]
BO_ 376 EngineClimateData_FD1: 8 PCM_HEV_FD
 SG_ AslChime_B_Rq : 39|1@0+ (1,0) [0|1] "SED"  GWM_ECG
 SG_ AslIconDsply_D_Rq : 3|2@0+ (1,0) [0|3] "SED"  IPMA_ADAS,GWM_ECG
 SG_ GasPrtc_D_RqDsply : 22|3@0+ (1,0) [0|7] "SED"  GWM_ECG
 SG_ EngAout_Aa_Actl : 17|10@0+ (0.05,-25.6) [-25.6|25.55] "rpm/ms"  ABS_ESC,GWM_ECG
 SG_ DynoMde_B_Cmd : 4|1@0+ (1,0) [0|1] "SED"  TCM_DSL_FD,ABS_ESC,GWM_ECG
 SG_ HvacHtrCore2_Te_Actl : 1|10@0+ (0.25,-50) [-50|205.5] "degC"  GWM_ECG
 SG_ EcssLamp_D_RqDsply : 19|2@0+ (1,0) [0|3] "SED"  GWM_ECG
 SG_ AirAmbTe_D_Qf : 35|2@0+ (1,0) [0|3] "SED"  IPMA_ADAS,ABS_ESC,TCCM_FD,GWM_ECG
 SG_ AirAmb_Te_ActlFilt : 49|10@0+ (0.25,-128) [-128|127.75] "deg C"  IPMA_ADAS,GWM_ECG
 SG_ AirAmb_Te_Actl : 33|10@0+ (0.25,-128) [-128|127.75] "degC"  HCM_FD,IPMA_ADAS,ABS_ESC,TCCM_FD,GWM_ECG
 SG_ AirAmb_P_Actl : 55|6@0+ (10,500) [500|1110] "mbar"  TCM_DSL_FD,GWM_ECG

BO_ 373 EngineData_11_FD1: 8 ECM_Diesel
 SG_ DieslPrtc2_D_RqDsply : 47|4@0+ (1,0) [0|15] "SED"  GWM_ECG
 SG_ DieslPrtcRgen_D_Actl : 38|2@0+ (1,0) [0|3] "SED"  TCM_DSL_FD,GWM_ECG
 SG_ EngTeColdPrtct_D_Stats : 4|2@0+ (1,0) [0|3] "SED"  GWM_ECG
 SG_ EngExhOvrTe_B_RqDsply : 39|1@0+ (1,0) [0|1] "SED"  GWM_ECG
 SG_ EngAout_N_RqMnPrtct : 20|13@0+ (2,0) [0|16382] "rpm"  GWM_ECG
 SG_ EngAout_N_RqMxPrtct : 52|13@0+ (2,0) [0|16382] "rpm"  GWM_ECG

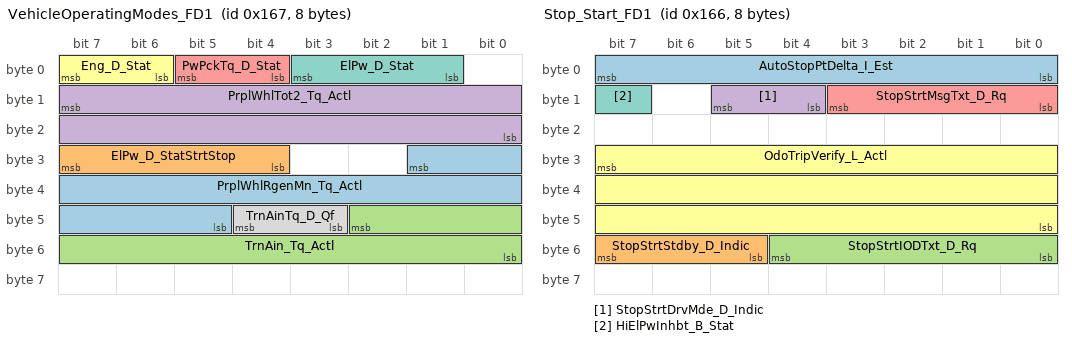
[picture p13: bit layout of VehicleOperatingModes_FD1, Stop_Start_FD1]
BO_ 359 VehicleOperatingModes_FD1: 8 PCM_HEV_FD
 SG_ PrplWhlRgenMn_Tq_Actl : 25|13@0+ (4,-16380) [-16380|16380] "Nm"  ABS_ESC,GWM_ECG
 SG_ ElPw_D_StatStrtStop : 31|4@0+ (1,0) [0|15] "SED"  PSCM_FD,GWM_ECG
 SG_ TrnAin_Tq_Actl : 42|11@0+ (1,-500) [-500|1547] "Nm"  ABS_ESC,GWM_ECG
 SG_ PrplWhlTot2_Tq_Actl : 15|16@0+ (4,-131072) [-131072|131060] "Nm"  ABS_ESC,PSCM_FD,TCCM_FD,GWM_ECG
 SG_ PwPckTq_D_Stat : 5|2@0+ (1,0) [0|3] "SED"  HCM_FD,IPMA_ADAS,ABS_ESC,PSCM_FD,TCCM_FD,TCM_DSL_FD,GWM_ECG
 SG_ Eng_D_Stat : 7|2@0+ (1,0) [0|3] "SED"  ABS_ESC,GWM_ECG
 SG_ ElPw_D_Stat : 3|3@0+ (1,0) [0|7] "SED"  HCM_FD,IPMA_ADAS,ABS_ESC,PSCM_FD,TCCM_FD,TCM_DSL_FD,GWM_ECG
 SG_ TrnAinTq_D_Qf : 44|2@0+ (1,0) [0|3] "SED"  ABS_ESC,GWM_ECG

BO_ 358 Stop_Start_FD1: 8 PCM_HEV_FD
 SG_ AutoStopPtDelta_I_Est : 7|8@0+ (1,-127) [-127|127] "Amps"  GWM_ECG
 SG_ StopStrtStdby_D_Indic : 55|3@0+ (1,0) [0|7] "SED"  GWM_ECG
 SG_ StopStrtIODTxt_D_Rq : 52|5@0+ (1,0) [0|31] "SED"  GWM_ECG
 SG_ StopStrtDrvMde_D_Indic : 13|2@0+ (1,0) [0|3] "SED"  GWM_ECG
 SG_ StopStrtMsgTxt_D_Rq : 11|4@0+ (1,0) [0|15] "SED"  GWM_ECG
 SG_ OdoTripVerify_L_Actl : 31|24@0+ (0.1,0) [0|1677721.4] "km"  GWM_ECG
 SG_ HiElPwInhbt_B_Stat : 15|1@0+ (1,0) [0|1] "SED"  GWM_ECG

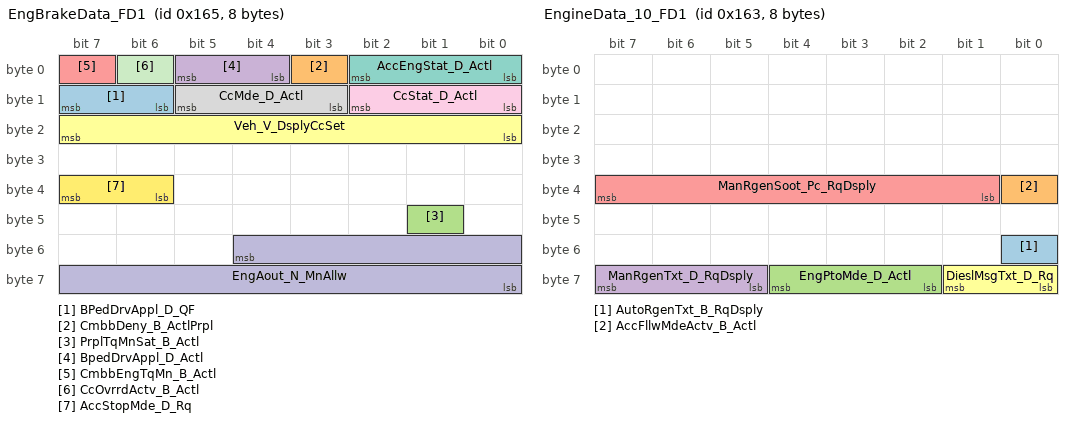
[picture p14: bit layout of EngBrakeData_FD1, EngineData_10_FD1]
BO_ 357 EngBrakeData_FD1: 8 PCM_HEV_FD
 SG_ BPedDrvAppl_D_QF : 15|2@0+ (1,0) [0|3] "SED"  IPMA_ADAS,ABS_ESC,PSCM_FD,TCM_DSL_FD,GWM_ECG
 SG_ CmbbDeny_B_ActlPrpl : 3|1@0+ (1,0) [0|1] "SED"  IPMA_ADAS,GWM_ECG
 SG_ PrplTqMnSat_B_Actl : 41|1@0+ (1,0) [0|1] "SED"  IPMA_ADAS,GWM_ECG
 SG_ BpedDrvAppl_D_Actl : 5|2@0+ (1,0) [0|3] "SED"  IPMA_ADAS,ABS_ESC,PSCM_FD,TCCM_FD,TCM_DSL_FD,GWM_ECG
 SG_ CmbbEngTqMn_B_Actl : 7|1@0+ (1,0) [0|1] "SED"  IPMA_ADAS,GWM_ECG
 SG_ Veh_V_DsplyCcSet : 23|8@0+ (1,0) [0|253] "Unitless"  GWM_ECG
 SG_ AccEngStat_D_Actl : 2|3@0+ (1,0) [0|7] "SED"  IPMA_ADAS,GWM_ECG
 SG_ CcMde_D_Actl : 13|3@0+ (1,0) [0|7] "SED"  TCM_DSL_FD,ABS_ESC,GWM_ECG
 SG_ CcStat_D_Actl : 10|3@0+ (1,0) [0|7] "SED"  IPMA_ADAS,ABS_ESC,TCCM_FD,TCM_DSL_FD,GWM_ECG
 SG_ EngAout_N_MnAllw : 52|13@0+ (2,0) [0|16382] "rpm"  GWM_ECG
 SG_ CcOvrrdActv_B_Actl : 6|1@0+ (1,0) [0|1] "SED"  IPMA_ADAS,ABS_ESC,TCCM_FD,TCM_DSL_FD,GWM_ECG
 SG_ AccStopMde_D_Rq : 39|2@0+ (1,0) [0|3] "SED"  IPMA_ADAS,ABS_ESC,GWM_ECG

BO_ 355 EngineData_10_FD1: 8 ECM_Diesel
 SG_ AutoRgenTxt_B_RqDsply : 48|1@0+ (1,0) [0|1] "SED"  GWM_ECG
 SG_ AccFllwMdeActv_B_Actl : 32|1@0+ (1,0) [0|1] "SED"  GWM_ECG
 SG_ EngPtoMde_D_Actl : 60|3@0+ (1,0) [0|7] "SED"  GWM_ECG
 SG_ ManRgenTxt_D_RqDsply : 63|3@0+ (1,0) [0|7] "SED"  GWM_ECG
 SG_ ManRgenSoot_Pc_RqDsply : 39|7@0+ (1,0) [0|126] "%"  GWM_ECG
 SG_ DieslMsgTxt_D_Rq : 57|2@0+ (1,0) [0|3] "SED"  GWM_ECG

BO_ 342 EngineData_6_FD1: 8 PCM_HEV_FD
 SG_ EngOvrhtMitgActv_D_Ind : 36|2@0+ (1,0) [0|3] "SED"  GWM_ECG
 SG_ EngClntTe_D_Qf : 33|2@0+ (1,0) [0|3] "SED"  TCM_DSL_FD,GWM_ECG
 SG_ EngGoutLss_Tq_Est : 31|8@0+ (1,0) [0|255] "Nm"  GWM_ECG
 SG_ EngOil_Te_Actl : 15|8@0+ (1,-60) [-60|193] "degC"  GWM_ECG
 SG_ EngClnt_Te_Actl : 7|8@0+ (1,-60) [-60|195] "degC"  TCM_DSL_FD,GWM_ECG

BO_ 71 Global_PATS_TargetInfo_FD1: 8 PCM_HEV_FD
 SG_ immoTarget1Status : 7|3@0+ (1,0) [0|7] "SED"  ABS_ESC,TCM_DSL_FD,GWM_ECG
 SG_ immoTarget1Data : 15|40@0+ (1,0) [0|1099511627775] "Encrypted"  ABS_ESC,GWM_ECG
 SG_ immoTarget1Cmd : 4|3@0+ (1,0) [0|7] "SED"  ABS_ESC,GWM_ECG

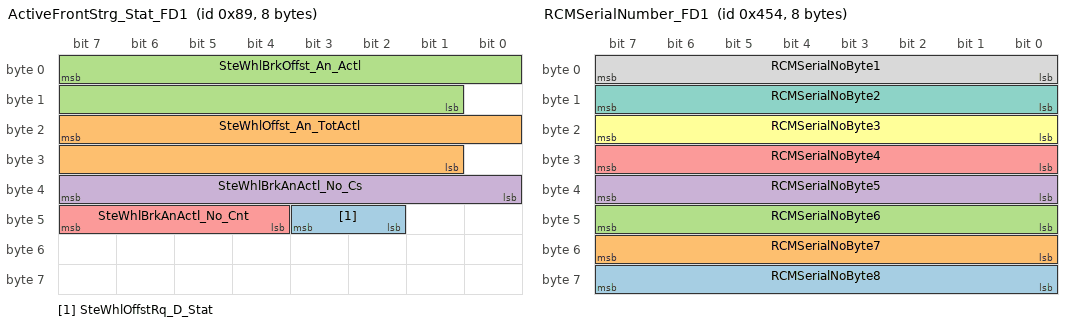
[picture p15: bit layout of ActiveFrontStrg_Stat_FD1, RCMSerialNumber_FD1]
BO_ 137 ActiveFrontStrg_Stat_FD1: 8 GWM_ECG
 SG_ SteWhlOffstRq_D_Stat : 43|2@0+ (1,0) [0|3] "SED"  ABS_ESC
 SG_ SteWhlOffst_An_TotActl : 23|15@0+ (0.1,-1600) [-1600|1676.5] "degrees"  ABS_ESC
 SG_ SteWhlBrkOffst_An_Actl : 7|15@0+ (0.1,-1600) [-1600|1676.5] "degrees"  ABS_ESC
 SG_ SteWhlBrkAnActl_No_Cs : 39|8@0+ (1,0) [0|255] "Unitless"  ABS_ESC
 SG_ SteWhlBrkAnActl_No_Cnt : 47|4@0+ (1,0) [0|15] "Unitless"  ABS_ESC

BO_ 129 Steering_Wheel_Data2_FD1: 8 GWM_ECG
 SG_ SelDrvMdeSwtch_D_Stat4 : 21|2@0+ (1,0) [0|3] "SED"  ABS_ESC
 SG_ SteWhlSwtchView_B_Stat : 23|1@0+ (1,0) [0|1] "SED" Vector__XXX
 SG_ SteWhlSwtchSet_B_Stat : 8|1@0+ (1,0) [0|1] "SED" Vector__XXX
 SG_ SteWhlSwtchPhon_B_Stat : 9|1@0+ (1,0) [0|1] "SED" Vector__XXX
 SG_ SteWhlSwtchNav_B_Stat : 10|1@0+ (1,0) [0|1] "SED" Vector__XXX
 SG_ SteWhlSwtchMed_B_Stat : 11|1@0+ (1,0) [0|1] "SED" Vector__XXX
 SG_ SteWhlSwtchIod_B_Stat : 12|1@0+ (1,0) [0|1] "SED" Vector__XXX
 SG_ SteWhlSwtchHud_B_Stat : 13|1@0+ (1,0) [0|1] "SED" Vector__XXX
 SG_ SteWhlSwtchBack_B_Stat : 14|1@0+ (1,0) [0|1] "SED" Vector__XXX
 SG_ SteWhlSwtchMenu_B_Stat : 22|1@0+ (1,0) [0|1] "SED" Vector__XXX
 SG_ SteEffortInc_B_RqDrv : 5|1@0+ (1,0) [0|1] "SED" Vector__XXX
 SG_ SelDrvMdeInc_B_RqDrv : 6|1@0+ (1,0) [0|1] "SED" Vector__XXX
 SG_ SelDrvMdeDec_B_RqDrv : 7|1@0+ (1,0) [0|1] "SED" Vector__XXX
 SG_ SuspDampInc_B_RqDrv : 15|1@0+ (1,0) [0|1] "SED" Vector__XXX
 SG_ SteWhlSwtchUp_B_Stat : 3|1@0+ (1,0) [0|1] "SED" Vector__XXX
 SG_ SteWhlSwtchRght_B_Stat : 2|1@0+ (1,0) [0|1] "SED" Vector__XXX
 SG_ SteWhlSwtchOk_B_Stat : 4|1@0+ (1,0) [0|1] "SED" Vector__XXX
 SG_ SteWhlSwtchLeft_B_Stat : 1|1@0+ (1,0) [0|1] "SED" Vector__XXX
 SG_ SteWhlSwtchDown_B_Stat : 0|1@0+ (1,0) [0|1] "SED" Vector__XXX
 SG_ SteWhlSwtchHome_B_Stat : 19|1@0+ (1,0) [0|1] "SED" Vector__XXX
 SG_ SteWhlSwtchInfo_B_Stat : 18|1@0+ (1,0) [0|1] "SED" Vector__XXX

BO_ 935 Side_Detect_R_Stat_FD1: 8 IPMA_ADAS
 SG_ LcwaDetctRight2_B_Stat : 40|1@0+ (1,0) [0|1] "SED" Vector__XXX
 SG_ RbaCtaRight_D_Stat : 55|3@0+ (1,0) [0|7] "SED" Vector__XXX
 SG_ CtaAlrtRight2_D_Stat : 30|3@0+ (1,0) [0|7] "SED" Vector__XXX
 SG_ BttRight_D_Stat : 45|3@0+ (1,0) [0|7] "SED" Vector__XXX
 SG_ BttRight_D_RqDrv : 47|2@0+ (1,0) [0|3] "SED" Vector__XXX
 SG_ CtaBrkRightMsgTxt_B_Rq : 42|1@0+ (1,0) [0|1] "SED" Vector__XXX
 SG_ CtaRightBrkEnbl_B_Rq : 31|1@0+ (1,0) [0|1] "SED"  ABS_ESC
 SG_ CtaRightBrkDecel_B_Rq : 7|1@0+ (1,0) [0|1] "SED"  ABS_ESC
 SG_ Side_Detect_R_Illum : 39|8@0+ (1,0) [0|255] "Percent" Vector__XXX
 SG_ CtaSnsRight_D_Stat : 25|2@0+ (1,0) [0|3] "SED" Vector__XXX
 SG_ CtaAlrtRight_D_Stat : 8|1@0+ (1,0) [0|1] "SED" Vector__XXX
 SG_ CtaRight_D_Stat : 18|3@0+ (1,0) [0|7] "SED" Vector__XXX
 SG_ SodRight_D_Stat : 15|3@0+ (1,0) [0|7] "SED" Vector__XXX
 SG_ SodSnsRight_D_Stat : 12|2@0+ (1,0) [0|3] "SED" Vector__XXX
 SG_ SodAlrtRight_D_Stat : 10|2@0+ (1,0) [0|3] "SED" Vector__XXX
 SG_ SodDetctRight_D_Stat : 23|3@0+ (1,0) [0|7] "SED" Vector__XXX
 SG_ SodWarnRight_Prd_Rq : 6|7@0+ (1,0) [0|127] "millisecond" Vector__XXX
 SG_ SodInnrRight_D_Stat : 20|2@0+ (1,0) [0|3] "SED" Vector__XXX
 SG_ CtaInnrRight_D_Stat : 27|2@0+ (1,0) [0|3] "SED" Vector__XXX
 SG_ LcwaDetctRight1_B_Stat : 41|1@0+ (1,0) [0|1] "SED" Vector__XXX
 SG_ LcwaRight_D_Stat : 52|3@0+ (1,0) [0|7] "SED"  GWM_ECG

BO_ 1108 RCMSerialNumber_FD1: 8 GWM_ECG
 SG_ RCMSerialNoByte8 : 63|8@0+ (1,0) [0|253] "Unitless"  ABS_ESC
 SG_ RCMSerialNoByte7 : 55|8@0+ (1,0) [0|253] "Unitless"  ABS_ESC
 SG_ RCMSerialNoByte6 : 47|8@0+ (1,0) [0|253] "Unitless"  ABS_ESC
 SG_ RCMSerialNoByte5 : 39|8@0+ (1,0) [0|253] "Unitless"  ABS_ESC
 SG_ RCMSerialNoByte4 : 31|8@0+ (1,0) [0|253] "Unitless"  ABS_ESC
 SG_ RCMSerialNoByte3 : 23|8@0+ (1,0) [0|253] "Unitless"  ABS_ESC
 SG_ RCMSerialNoByte2 : 15|8@0+ (1,0) [0|253] "Unitless"  ABS_ESC
 SG_ RCMSerialNoByte1 : 7|8@0+ (1,0) [0|253] "Unitless"  ABS_ESC

BO_ 1146 TrailerInfo_2_FD1: 8 GWM_ECG
 SG_ TrlrAidSwtch_D_RqDrv : 35|2@0+ (1,0) [0|3] "SED"  PSCM_FD
 SG_ TrlrAidCtl_U_RqDrv : 31|12@0+ (0.00125,0) [0|5.11625] "volt"  PSCM_FD
 SG_ TrlrAidAn_URate_Actl : 11|12@0+ (0.00125,-2.5) [-2.5|2.61625] "volt/sec" Vector__XXX
 SG_ TrlrAidAn_U_Actl : 7|12@0+ (0.00125,0) [0|5.11625] "volt" Vector__XXX

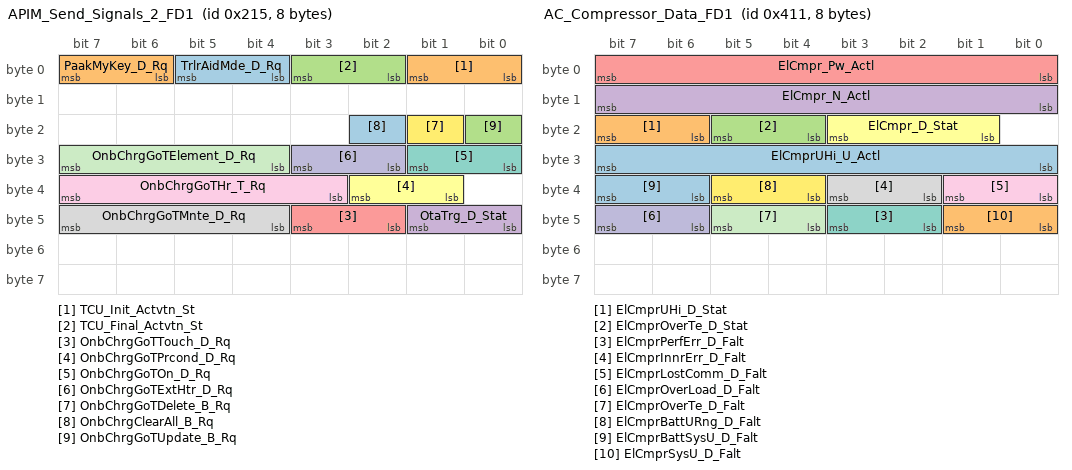
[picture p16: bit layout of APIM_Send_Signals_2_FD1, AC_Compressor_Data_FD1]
BO_ 533 APIM_Send_Signals_2_FD1: 8 GWM_ECG
 SG_ TrlrAidMde_D_Rq : 5|2@0+ (1,0) [0|3] "SED"  PSCM_FD
 SG_ TCU_Init_Actvtn_St : 1|2@0+ (1,0) [0|3] "SED" Vector__XXX
 SG_ TCU_Final_Actvtn_St : 3|2@0+ (1,0) [0|3] "SED" Vector__XXX
 SG_ OtaTrg_D_Stat : 41|2@0+ (1,0) [0|3] "SED" Vector__XXX
 SG_ OnbChrgGoTTouch_D_Rq : 43|2@0+ (1,0) [0|3] "SED" Vector__XXX
 SG_ OnbChrgGoTPrcond_D_Rq : 34|2@0+ (1,0) [0|3] "SED" Vector__XXX
 SG_ OnbChrgGoTOn_D_Rq : 25|2@0+ (1,0) [0|3] "SED" Vector__XXX
 SG_ OnbChrgGoTMnte_D_Rq : 47|4@0+ (1,0) [0|15] "minute" Vector__XXX
 SG_ OnbChrgGoTHr_T_Rq : 39|5@0+ (1,0) [0|29] "hour" Vector__XXX
 SG_ OnbChrgGoTExtHtr_D_Rq : 27|2@0+ (1,0) [0|3] "SED" Vector__XXX
 SG_ OnbChrgGoTElement_D_Rq : 31|4@0+ (1,0) [0|15] "Unitless" Vector__XXX
 SG_ OnbChrgGoTDelete_B_Rq : 17|1@0+ (1,0) [0|1] "SED" Vector__XXX
 SG_ OnbChrgClearAll_B_Rq : 18|1@0+ (1,0) [0|1] "SED" Vector__XXX
 SG_ PaakMyKey_D_Rq : 7|2@0+ (1,0) [0|3] "SED" Vector__XXX
 SG_ OnbChrgGoTUpdate_B_Rq : 16|1@0+ (1,0) [0|1] "SED" Vector__XXX

BO_ 1041 AC_Compressor_Data_FD1: 8 GWM_ECG
 SG_ ElCmprUHi_U_Actl : 31|8@0+ (2,0) [0|510] "volt" Vector__XXX
 SG_ ElCmprUHi_D_Stat : 23|2@0+ (1,0) [0|3] "SED" Vector__XXX
 SG_ ElCmprOverTe_D_Stat : 21|2@0+ (1,0) [0|3] "SED" Vector__XXX
 SG_ ElCmpr_N_Actl : 15|8@0+ (50,0) [0|12700] "RPM" Vector__XXX
 SG_ ElCmpr_Pw_Actl : 7|8@0+ (40,0) [0|10160] "watts"  PCM_HEV_FD
 SG_ ElCmpr_D_Stat : 19|3@0+ (1,0) [0|7] "SED" Vector__XXX
 SG_ ElCmprPerfErr_D_Falt : 43|2@0+ (1,0) [0|3] "SED" Vector__XXX
 SG_ ElCmprInnrErr_D_Falt : 35|2@0+ (1,0) [0|3] "SED" Vector__XXX
 SG_ ElCmprLostComm_D_Falt : 33|2@0+ (1,0) [0|3] "SED" Vector__XXX
 SG_ ElCmprOverLoad_D_Falt : 47|2@0+ (1,0) [0|3] "SED" Vector__XXX
 SG_ ElCmprOverTe_D_Falt : 45|2@0+ (1,0) [0|3] "SED" Vector__XXX
 SG_ ElCmprBattURng_D_Falt : 37|2@0+ (1,0) [0|3] "SED" Vector__XXX
 SG_ ElCmprBattSysU_D_Falt : 39|2@0+ (1,0) [0|3] "SED" Vector__XXX
 SG_ ElCmprSysU_D_Falt : 41|2@0+ (1,0) [0|3] "SED" Vector__XXX

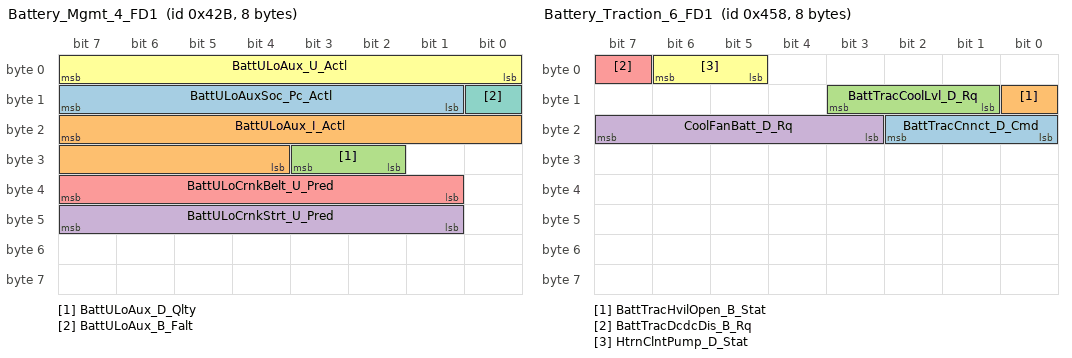
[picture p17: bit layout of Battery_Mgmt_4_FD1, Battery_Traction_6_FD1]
BO_ 1067 Battery_Mgmt_4_FD1: 8 GWM_ECG
 SG_ BattULoAuxSoc_Pc_Actl : 15|7@0+ (1,0) [0|127] "percent"  PCM_HEV_FD
 SG_ BattULoAux_I_Actl : 23|12@0+ (0.0625,-128) [-128|127.875] "ampere"  PCM_HEV_FD
 SG_ BattULoAux_D_Qlty : 27|2@0+ (1,0) [0|3] "SED"  PCM_HEV_FD
 SG_ BattULoCrnkStrt_U_Pred : 47|7@0+ (0.1,0) [0|12.7] "volt"  PCM_HEV_FD
 SG_ BattULoCrnkBelt_U_Pred : 39|7@0+ (0.1,0) [0|12.7] "volt"  PCM_HEV_FD
 SG_ BattULoAux_U_Actl : 7|8@0+ (0.0625,0) [0|15.875] "volt"  PCM_HEV_FD
 SG_ BattULoAux_B_Falt : 8|1@0+ (1,0) [0|1] "SED"  PCM_HEV_FD

BO_ 1040 AC_Compressor_Req_FD1: 8 GWM_ECG
 SG_ ElCmprEnbl_B_Rq : 23|1@0+ (1,0) [0|1] "SED"  PCM_HEV_FD
 SG_ ElCmpr_N_Rq : 15|8@0+ (50,0) [0|12750] "RPM" Vector__XXX

BO_ 1144 MHT_EV_Wakeup_FD1: 8 GWM_ECG
 SG_ BattChrgTrgtSoC_D_Rq : 35|3@0+ (1,0) [0|7] "Percent" Vector__XXX
 SG_ CabnEvapSovFront_B_Rq : 38|1@0+ (1,0) [0|1] "SED" Vector__XXX
 SG_ HeatCoreSovRear_B_Rq : 36|1@0+ (1,0) [0|1] "SED" Vector__XXX
 SG_ BattChlrSov_B_Rq : 39|1@0+ (1,0) [0|1] "SED" Vector__XXX
 SG_ CabnEvapSovRear_B_Rq : 37|1@0+ (1,0) [0|1] "SED" Vector__XXX
 SG_ BrkAppl_D_RqPt : 25|2@0+ (1,0) [0|3] "SED" Vector__XXX
 SG_ BattClntVlvOvrrd_D_Rq : 31|2@0+ (1,0) [0|3] "SED" Vector__XXX
 SG_ BattTracChillerOn_B_Rq : 27|1@0+ (1,0) [0|1] "SED" Vector__XXX
 SG_ BattTracChiller_D_Stat : 29|2@0+ (1,0) [0|3] "SED" Vector__XXX
 SG_ HtrnDcdcDis_B_Rq : 26|1@0+ (1,0) [0|1] "SED" Vector__XXX
 SG_ HtrnCnnctPwr_B_Stat : 16|1@0+ (1,0) [0|1] "SED" Vector__XXX
 SG_ PtcHtr_D_Stat : 18|2@0+ (1,0) [0|3] "SED"  PCM_HEV_FD
 SG_ WakeAlarm0_B_Typ : 21|1@0+ (1,0) [0|1] "SED" Vector__XXX
 SG_ WakeAlarm0_T_Rq : 7|15@0+ (1,0) [0|32767] "minute" Vector__XXX
 SG_ HtrnClntFlw_D_Rq : 20|2@0+ (1,0) [0|3] "SED" Vector__XXX
 SG_ BattTracDrvSustn_B_Rq : 8|1@0+ (1,0) [0|1] "SED" Vector__XXX
 SG_ CabinDrvSustn_B_Rq : 23|1@0+ (1,0) [0|1] "SED" Vector__XXX
 SG_ ChrgNowEvnt_B_Stat : 22|1@0+ (1,0) [0|1] "SED" Vector__XXX
 SG_ PreCondBatt_B_Actl : 32|1@0+ (1,0) [0|1] "SED"  PCM_HEV_FD

BO_ 1112 Battery_Traction_6_FD1: 8 GWM_ECG
 SG_ BattTracCnnct_D_Cmd : 18|3@0+ (1,0) [0|7] "SED"  PCM_HEV_FD
 SG_ BattTracHvilOpen_B_Stat : 8|1@0+ (1,0) [0|1] "SED"  PCM_HEV_FD
 SG_ BattTracCoolLvl_D_Rq : 11|3@0+ (1,0) [0|7] "SED" Vector__XXX
 SG_ CoolFanBatt_D_Rq : 23|5@0+ (1,0) [0|31] "unitless"  PCM_HEV_FD
 SG_ BattTracDcdcDis_B_Rq : 7|1@0+ (1,0) [0|1] "SED"  PCM_HEV_FD
 SG_ HtrnClntPump_D_Stat : 6|2@0+ (1,0) [0|3] "SED" Vector__XXX

BO_ 139 CruiseCtrl_Strg_Data_FD1: 8 GWM_ECG
 SG_ AccButtnGpTogglePress2 : 25|1@0+ (1,0) [0|1] "SED" Vector__XXX
 SG_ TjaButtnOnOffPress2 : 26|1@0+ (1,0) [0|1] "SED" Vector__XXX
 SG_ ActvFrontSteMsgTxt_D_Rq : 31|3@0+ (1,0) [0|7] "SED" Vector__XXX
 SG_ ActvFrontSteLck_D_Stat : 17|2@0+ (1,0) [0|3] "SED"  ECM_Diesel,PCM_FD,PCM_HEV_FD
 SG_ SelDrvMdeAdptSte_D_Stat : 28|2@0+ (1,0) [0|3] "SED"  ABS_ESC
 SG_ AslButtnOnOffPress2 : 4|1@0+ (1,0) [0|1] "SED" Vector__XXX
 SG_ AslButtnOnOffCnclPres2 : 5|1@0+ (1,0) [0|1] "SED" Vector__XXX
 SG_ CcButtnOnPress2 : 18|1@0+ (1,0) [0|1] "SED" Vector__XXX
 SG_ CcButtnOnOffPress2 : 19|1@0+ (1,0) [0|1] "SED" Vector__XXX
 SG_ CcButtnOnOffCnclPress2 : 20|1@0+ (1,0) [0|1] "SED" Vector__XXX
 SG_ CcButtnOffPress2 : 21|1@0+ (1,0) [0|1] "SED" Vector__XXX
 SG_ CcAsllButtnResPress2 : 22|1@0+ (1,0) [0|1] "SED" Vector__XXX
 SG_ CcAslButtnSetPress2 : 23|1@0+ (1,0) [0|1] "SED" Vector__XXX
 SG_ CcAslButtnSetIncPress2 : 8|1@0+ (1,0) [0|1] "SED" Vector__XXX
 SG_ CcAslButtnSetDecPress2 : 9|1@0+ (1,0) [0|1] "SED" Vector__XXX
 SG_ CcAslButtnResIncPress2 : 10|1@0+ (1,0) [0|1] "SED" Vector__XXX
 SG_ CcAslButtnResDecPress2 : 11|1@0+ (1,0) [0|1] "SED" Vector__XXX
 SG_ CcAslButtnOnPress2 : 12|1@0+ (1,0) [0|1] "SED" Vector__XXX
 SG_ CcAslButtnOnOffCncl2 : 13|1@0+ (1,0) [0|1] "SED" Vector__XXX
 SG_ CcAslButtnOffCnclPres2 : 14|1@0+ (1,0) [0|1] "SED" Vector__XXX
 SG_ CcAslButtnIndxIncPres2 : 15|1@0+ (1,0) [0|1] "SED" Vector__XXX
 SG_ CcAslButtnIndxDecPres2 : 0|1@0+ (1,0) [0|1] "SED" Vector__XXX
 SG_ CcAslButtnDeny_B_Actl2 : 1|1@0+ (1,0) [0|1] "SED" Vector__XXX
 SG_ CcAslButtnCnclResPres2 : 2|1@0+ (1,0) [0|1] "SED" Vector__XXX
 SG_ CcAslButtnCnclPress2 : 3|1@0+ (1,0) [0|1] "SED" Vector__XXX
 SG_ AccButtnGapIncPress2 : 6|1@0+ (1,0) [0|1] "SED" Vector__XXX
 SG_ AccButtnGapDecPress2 : 7|1@0+ (1,0) [0|1] "SED" Vector__XXX

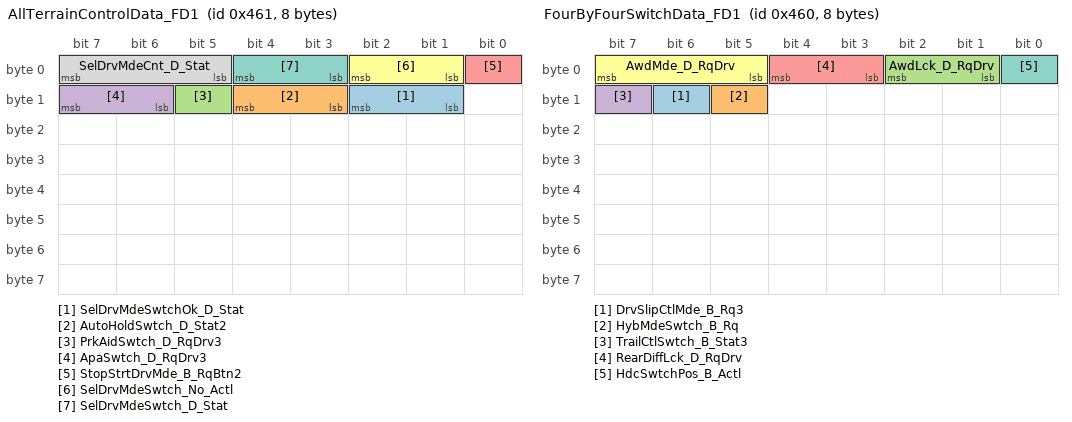
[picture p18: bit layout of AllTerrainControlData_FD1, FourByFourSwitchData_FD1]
BO_ 1121 AllTerrainControlData_FD1: 8 GWM_ECG
 SG_ SelDrvMdeSwtchOk_D_Stat : 10|2@0+ (1,0) [0|3] "SED" Vector__XXX
 SG_ AutoHoldSwtch_D_Stat2 : 12|2@0+ (1,0) [0|3] "SED"  ABS_ESC
 SG_ PrkAidSwtch_D_RqDrv3 : 13|1@0+ (1,0) [0|1] "SED" Vector__XXX
 SG_ ApaSwtch_D_RqDrv3 : 15|2@0+ (1,0) [0|3] "SED"  IPMA_ADAS
 SG_ StopStrtDrvMde_B_RqBtn2 : 0|1@0+ (1,0) [0|1] "SED" Vector__XXX
 SG_ SelDrvMdeSwtch_No_Actl : 2|2@0+ (1,0) [0|3] "unitless"  ABS_ESC
 SG_ SelDrvMdeSwtch_D_Stat : 4|2@0+ (1,0) [0|3] "SED"  ABS_ESC
 SG_ SelDrvMdeCnt_D_Stat : 7|3@0+ (1,0) [0|7] "Counts"  ABS_ESC

BO_ 1120 FourByFourSwitchData_FD1: 8 GWM_ECG
 SG_ DrvSlipCtlMde_B_Rq3 : 14|1@0+ (1,0) [0|1] "SED"  ABS_ESC
 SG_ HybMdeSwtch_B_Rq : 13|1@0+ (1,0) [0|1] "SED"  PCM_HEV_FD
 SG_ AwdLck_D_RqDrv : 2|2@0+ (1,0) [0|3] "SED" Vector__XXX
 SG_ TrailCtlSwtch_B_Stat3 : 15|1@0+ (1,0) [0|1] "SED" Vector__XXX
 SG_ RearDiffLck_D_RqDrv : 4|2@0+ (1,0) [0|3] "SED"  TCCM_FD
 SG_ AwdMde_D_RqDrv : 7|3@0+ (1,0) [0|7] "SED"  TCCM_FD
 SG_ HdcSwtchPos_B_Actl : 0|1@0+ (1,0) [0|1] "SED"  ABS_ESC

BO_ 1050 Climate_Control_Data_FD1: 8 GWM_ECG
 SG_ CamraRearBttn_D_Stat : 35|1@0+ (1,0) [0|1] "SED" Vector__XXX
 SG_ TrailCtlSwtch_B_Stat : 16|1@0+ (1,0) [0|1] "SED" Vector__XXX
 SG_ CamraFrntBttn_D_Stat : 8|1@0+ (1,0) [0|1] "SED"  IPMA_ADAS
 SG_ AutoHoldSwtch_D_Stat : 20|2@0+ (1,0) [0|3] "SED" Vector__XXX
 SG_ GlvBoxRleas_No_Actl : 23|3@0+ (1,0) [0|7] "unitless" Vector__XXX
 SG_ EcoInhbt_B_RqHvac : 17|1@0+ (1,0) [0|1] "SED" Vector__XXX
 SG_ LpdbPtc3_B_Rq : 36|1@0+ (1,0) [0|1] "SED" Vector__XXX
 SG_ LpdbPtc2_B_Rq : 37|1@0+ (1,0) [0|1] "SED" Vector__XXX
 SG_ LpdbPtc1_B_Rq : 38|1@0+ (1,0) [0|1] "SED" Vector__XXX
 SG_ LpdbHeatWiprPrk_B_Rq : 39|1@0+ (1,0) [0|1] "SED" Vector__XXX
 SG_ LpdbDfrstRearOn_B_Rq : 24|1@0+ (1,0) [0|1] "SED" Vector__XXX
 SG_ LpdbDfrstFrOn_B_Rq : 25|1@0+ (1,0) [0|1] "SED" Vector__XXX
 SG_ LpdbDfrstFlOn_B_Rq : 26|1@0+ (1,0) [0|1] "SED" Vector__XXX
 SG_ LpdbAuxBlwr_B_Rq : 27|1@0+ (1,0) [0|1] "SED" Vector__XXX
 SG_ PrkAidSwtch_No_Cnt : 31|4@0+ (1,0) [0|15] "Unitless" Vector__XXX
 SG_ PrkAidSwtch_D_RqDrv : 18|1@0+ (1,0) [0|1] "SED" Vector__XXX
 SG_ SteWhlHeat_D_Rq : 13|4@0+ (1,0) [0|15] "SED" Vector__XXX
 SG_ MirrorHeatOn_B_Rq : 14|1@0+ (1,0) [0|1] "SED" Vector__XXX
 SG_ Remote_Start_QuietMode : 15|1@0+ (1,0) [0|1] "SED" Vector__XXX
 SG_ DrvSlipCtlMde_B_Rq : 9|1@0+ (1,0) [0|1] "SED" Vector__XXX
 SG_ Outside_Air_Temp_Stat : 7|8@0+ (0.5,-40) [-40|86.5] "Degrees C"  ECM_Diesel,IPMA_ADAS,PCM_FD,PCM_HEV_FD,PSCM_FD

BO_ 942 ParkAid_Data_3_HS2_FD1: 8 IPMA_ADAS
 SG_ PrkAidRdiusRight_L_Dsply : 15|8@0+ (1,0) [0|255] "unitless"  GWM_ECG
 SG_ PrkAidRdiusLeft_L_Dsply : 7|8@0+ (1,0) [0|255] "unitless"  GWM_ECG
 SG_ PrkAidDrvDir_D_Stat : 23|3@0+ (1,0) [0|7] "SED"  GWM_ECG

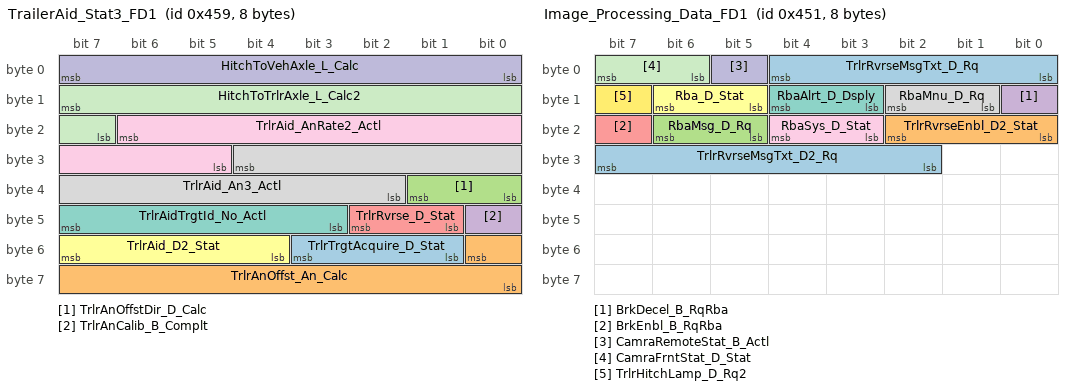
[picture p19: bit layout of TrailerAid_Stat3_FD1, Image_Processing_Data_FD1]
BO_ 1113 TrailerAid_Stat3_FD1: 8 IPMA_ADAS
 SG_ TrlrTrgtAcquire_D_Stat : 51|3@0+ (1,0) [0|7] "SED"  PSCM_FD,GWM_ECG
 SG_ TrlrAnOffst_An_Calc : 48|9@0+ (0.1,0) [0|51.1] "degrees"  GWM_ECG
 SG_ TrlrAnOffstDir_D_Calc : 33|2@0+ (1,0) [0|3] "SED"  GWM_ECG
 SG_ TrlrAnCalib_B_Complt : 40|1@0+ (1,0) [0|1] "SED"  GWM_ECG
 SG_ TrlrRvrse_D_Stat : 42|2@0+ (1,0) [0|3] "SED"  PSCM_FD
 SG_ TrlrAid_D2_Stat : 55|4@0+ (1,0) [0|15] "SED"  PSCM_FD
 SG_ TrlrAidTrgtId_No_Actl : 47|5@0+ (1,0) [0|31] "unitless"  PSCM_FD
 SG_ TrlrAid_An3_Actl : 28|11@0+ (0.125,-90) [-90|165.75] "degrees"  PSCM_FD,GWM_ECG
 SG_ TrlrAid_AnRate2_Actl : 22|10@0+ (0.125,-50) [-50|77.75] "degrees/second"  PSCM_FD,GWM_ECG
 SG_ HitchToVehAxle_L_Calc : 7|8@0+ (0.0127,-0.508) [-0.508|2.7178] "meter"  PSCM_FD,GWM_ECG
 SG_ HitchToTrlrAxle_L_Calc2 : 15|9@0+ (0.0254,0) [0|12.9794] "meter"  GWM_ECG

BO_ 1105 Image_Processing_Data_FD1: 8 IPMA_ADAS
 SG_ TrlrRvrseMsgTxt_D2_Rq : 31|6@0+ (1,0) [0|63] "SED"  PSCM_FD,GWM_ECG
 SG_ TrlrRvrseEnbl_D2_Stat : 18|3@0+ (1,0) [0|7] "SED"  PSCM_FD,GWM_ECG
 SG_ RbaMsg_D_Rq : 22|2@0+ (1,0) [0|3] "SED"  GWM_ECG
 SG_ BrkDecel_B_RqRba : 8|1@0+ (1,0) [0|1] "SED"  ABS_ESC
 SG_ BrkEnbl_B_RqRba : 23|1@0+ (1,0) [0|1] "SED"  ABS_ESC
 SG_ Rba_D_Stat : 14|2@0+ (1,0) [0|3] "SED"  GWM_ECG
 SG_ RbaAlrt_D_Dsply : 12|2@0+ (1,0) [0|3] "SED"  GWM_ECG
 SG_ RbaMnu_D_Rq : 10|2@0+ (1,0) [0|3] "SED"  GWM_ECG
 SG_ RbaSys_D_Stat : 20|2@0+ (1,0) [0|3] "SED"  ABS_ESC,GWM_ECG
 SG_ CamraRemoteStat_B_Actl : 5|1@0+ (1,0) [0|1] "SED" Vector__XXX
 SG_ CamraFrntStat_D_Stat : 7|2@0+ (1,0) [0|3] "SED"  GWM_ECG
 SG_ TrlrHitchLamp_D_Rq2 : 15|1@0+ (1,0) [0|1] "SED"  GWM_ECG
 SG_ TrlrRvrseMsgTxt_D_Rq : 4|5@0+ (1,0) [0|31] "SED"  GWM_ECG

BO_ 938 ParkAid_Aud_Warn_Stat_FD1: 8 IPMA_ADAS
 SG_ SidePrkSnsR2_D_Stat : 59|4@0+ (1,0) [0|15] "SED"  GWM_ECG
 SG_ SidePrkSnsR1_D_Stat : 63|4@0+ (1,0) [0|15] "SED"  GWM_ECG
 SG_ SidePrkSnsL2_D_Stat : 51|4@0+ (1,0) [0|15] "SED"  GWM_ECG
 SG_ ApaMde_D_Stat : 23|3@0+ (1,0) [0|7] "SED"  GWM_ECG
 SG_ ApaActvSd_D_Actl : 14|2@0+ (1,0) [0|3] "SED"  GWM_ECG
 SG_ PrkAidSwtch_B_Stat : 8|1@0+ (1,0) [0|1] "SED"  GWM_ECG
 SG_ ApaMde_D_Avail : 12|4@0+ (1,0) [0|15] "SED"  GWM_ECG
 SG_ PrkAidSnsFrSide_D_Stat : 43|4@0+ (1,0) [0|15] "SED"  GWM_ECG
 SG_ PrkAidSnsFrCrnr_D_Stat : 47|4@0+ (1,0) [0|15] "SED"  GWM_ECG
 SG_ PrkAidSnsFrCntr_D_Stat : 35|4@0+ (1,0) [0|15] "SED"  GWM_ECG
 SG_ PrkAidSnsFlSide_D_Stat : 39|4@0+ (1,0) [0|15] "SED"  GWM_ECG
 SG_ PrkAidSnsFlCrnr_D_Stat : 27|4@0+ (1,0) [0|15] "SED"  GWM_ECG
 SG_ PrkAidSnsFlCntr_D_Stat : 31|4@0+ (1,0) [0|15] "SED"  GWM_ECG
 SG_ PrkBrkEl_B_RqFap : 20|1@0+ (1,0) [0|1] "SED"  GWM_ECG,ABS_ESC
 SG_ RpaChime_D_Rq : 7|4@0+ (1,0) [0|15] "SED"  GWM_ECG
 SG_ FpaChime_D_Rq : 3|4@0+ (1,0) [0|15] "SED"  GWM_ECG
 SG_ PrkAidMsgTxt_D_Rq : 19|4@0+ (1,0) [0|15] "SED"  GWM_ECG
 SG_ SidePrkSnsL1_D_Stat : 55|4@0+ (1,0) [0|15] "SED"  GWM_ECG
 SG_ PrkAidAudioMute_B_Rq : 15|1@0+ (1,0) [0|1] "SED"  GWM_ECG

BO_ 939 ParkAid_Aud_Warn_Stat2_FD1: 8 IPMA_ADAS
 SG_ SidePrkSnsR4_D_Stat : 55|4@0+ (1,0) [0|15] "SED"  GWM_ECG
 SG_ SidePrkSnsR3_D_Stat : 47|4@0+ (1,0) [0|15] "SED"  GWM_ECG
 SG_ SidePrkSnsL4_D_Stat : 43|4@0+ (1,0) [0|15] "SED"  GWM_ECG
 SG_ SidePrkSnsL3_D_Stat : 37|4@0+ (1,0) [0|15] "SED"  GWM_ECG
 SG_ PrkAidChime_D_Stat : 4|2@0+ (1,0) [0|3] "SED"  GWM_ECG
 SG_ PrkAidSnsRlCntr_D_Stat : 15|4@0+ (1,0) [0|15] "SED"  GWM_ECG
 SG_ PrkAidSnsRrSide_D_Stat : 27|4@0+ (1,0) [0|15] "SED"  GWM_ECG
 SG_ PrkAidSnsRrCrnr_D_Stat : 31|4@0+ (1,0) [0|15] "SED"  GWM_ECG
 SG_ PrkAidSnsRrCntr_D_Stat : 19|4@0+ (1,0) [0|15] "SED"  GWM_ECG
 SG_ PrkAidSnsRlSide_D_Stat : 23|4@0+ (1,0) [0|15] "SED"  GWM_ECG
 SG_ PrkAidSnsRlCrnr_D_Stat : 11|4@0+ (1,0) [0|15] "SED"  GWM_ECG
 SG_ PrkAidRear_D_Stat : 39|2@0+ (1,0) [0|3] "SED"  GWM_ECG
 SG_ PrkAidFront_D_Stat : 2|2@0+ (1,0) [0|3] "SED"  GWM_ECG
 SG_ PrkAid_D_Falt : 7|3@0+ (1,0) [0|7] "SED"  GWM_ECG
 SG_ ApaLongCtrlEnbl_D_Rq : 0|1@0+ (1,0) [0|1] "SED"  ABS_ESC,ECM_Diesel,PCM_FD,PCM_HEV_FD,TCM_DSL_FD,GWM_ECG
 SG_ ApaBrk_A_Rq : 63|8@0+ (0.05,-12.75) [-12.75|0] "m/sec^2"  ABS_ESC,ECM_Diesel,PCM_FD,PCM_HEV_FD,GWM_ECG
 SG_ PrkAidLamp_D_Rq : 33|2@0+ (1,0) [0|3] "SED"  GWM_ECG

BO_ 937 ParkAid_Data_2_FD1: 8 IPMA_ADAS
 SG_ Veh_V_RqFap : 31|8@0+ (0.1,0) [0|25.5] "km/h"  ECM_Diesel,PCM_FD,PCM_HEV_FD
 SG_ TrnRngDRqFap_No_Cs : 23|8@0+ (1,0) [0|255] "unitless"  PCM_FD,PCM_HEV_FD,TCM_DSL_FD
 SG_ TrnRngDRqFap_No_Cnt : 15|4@0+ (1,0) [0|15] "unitless"  PCM_FD,PCM_HEV_FD,TCM_DSL_FD
 SG_ TrnRng_D_RqFap : 11|3@0+ (1,0) [0|7] "SED"  ECM_Diesel,PCM_FD,PCM_HEV_FD,TCM_DSL_FD,GWM_ECG
 SG_ FapLcDistToObj_L_Actl : 7|8@0+ (0.01,0) [0|2.53] "meter"  ECM_Diesel,PCM_FD,PCM_HEV_FD

BO_TX_BU_ 878 : PCM_FD,PCM_HEV_FD;
BO_TX_BU_ 2024 : ECM_Diesel,PCM_FD,PCM_HEV_FD;
BO_TX_BU_ 1697 : PCM_FD,PCM_HEV_FD;
BO_TX_BU_ 1696 : ECM_Diesel,PCM_FD,PCM_HEV_FD;
BO_TX_BU_ 1429 : ECM_Diesel,PCM_FD,PCM_HEV_FD;
BO_TX_BU_ 1100 : ECM_Diesel,PCM_FD,PCM_HEV_FD;
BO_TX_BU_ 1086 : ECM_Diesel,PCM_FD,PCM_HEV_FD;
BO_TX_BU_ 1085 : ECM_Diesel,PCM_FD;
BO_TX_BU_ 1071 : ECM_Diesel,PCM_FD,PCM_HEV_FD;
BO_TX_BU_ 1069 : ECM_Diesel,PCM_FD,PCM_HEV_FD;
BO_TX_BU_ 1060 : ECM_Diesel,PCM_FD,PCM_HEV_FD;
BO_TX_BU_ 1057 : ECM_Diesel,PCM_FD,PCM_HEV_FD;
BO_TX_BU_ 1055 : PCM_FD,ECM_Diesel,PCM_HEV_FD;
BO_TX_BU_ 517 : ECM_Diesel,PCM_FD,PCM_HEV_FD;
BO_TX_BU_ 516 : ECM_Diesel,PCM_FD,PCM_HEV_FD;
BO_TX_BU_ 514 : ECM_Diesel,PCM_FD,PCM_HEV_FD;
BO_TX_BU_ 512 : ECM_Diesel,PCM_FD,PCM_HEV_FD;
BO_TX_BU_ 380 : ECM_Diesel,PCM_FD;
BO_TX_BU_ 377 : ECM_Diesel,PCM_FD,PCM_HEV_FD;
BO_TX_BU_ 376 : ECM_Diesel,PCM_FD,PCM_HEV_FD;
BO_TX_BU_ 359 : ECM_Diesel,PCM_FD,PCM_HEV_FD;
BO_TX_BU_ 358 : ECM_Diesel,PCM_FD,PCM_HEV_FD;
BO_TX_BU_ 357 : ECM_Diesel,PCM_FD,PCM_HEV_FD;
BO_TX_BU_ 342 : ECM_Diesel,PCM_FD,PCM_HEV_FD;
BO_TX_BU_ 71 : ECM_Diesel,PCM_FD,PCM_HEV_FD;

CM_ "New CAN FD network";
CM_ BU_ HCM_FD "Headlamp Ctrl. Mod.A (HS_CAN), Adaptive Headlamps";
CM_ BU_ IPMA_ADAS "Assist Driving Alert System";
CM_ BU_ PSCM_FD "Passenger Front Climate Control Seat Module";
CM_ BU_ ABS_ESC "Anti-lock Brake / Traction Control Module";
CM_ BU_ TCCM_FD "Transfer Case Control Module, 4x4 Control Module";
CM_ BU_ TCM_DSL_FD "Transmission Control Module";
CM_ BU_ PCM_FD "Powertrain Control Module";
CM_ BU_ ECM_Diesel "Diesel";
CM_ BU_ GWM_ECG "Gateway Module CGEA1.3(Star Architecture)";
CM_ BU_ TSTR "Diagnostic Tester";
CM_ BO_ 1632 "drecker 10/23/09 Need SAPP in sync w/Strg Torque for proper PAM interpretation, else fault msg's displayed FP@20ms IPC needs EPAS_Failure for msg to driver.  Not map w/Lane Assist FP@30s FP), save bandwidth if feature not on vehicle ";
CM_ BO_ 1633 "drecker 10/23/09 Need SAPP in sync w/Strg Torque for proper PAM interpretation, else fault msg's displayed FP@20ms IPC needs EPAS_Failure for msg to driver.  Not map w/Lane Assist FP@30s FP), save bandwidth if feature not on vehicle ";
CM_ SG_ 954 GenericSwtch2_No_Actl "U625 Police Wig Wag feature";
CM_ BO_ 1759 "OBDII Request ($7DF) messages are for FNOS 1.0.1 only.
Diagnostic Functional Addressing ($7DF) and Dual Rate Periodic messages are for FNOS I3 only.";
CM_ SG_ 1086 ElLoadCtl_D_Rq "Signal not transmitted on HEV variants.";
CM_ SG_ 1085 ULoRgenTestMde_B_Stat "Signal not transmitted on HEV variants.";
CM_ SG_ 1085 PwSrcULoComm_B_Falt "Signal not transmitted on HEV variants.";
CM_ SG_ 1071 CluPdl_PcRate_Actl "Signal not transmitted on HEV variants.";
CM_ SG_ 1071 CluPdlPos_Pc_Meas "Signal not transmitted on HEV variants.";
CM_ SG_ 1071 CluPdlPosPcMeas_D_Qf "Signal not transmitted on HEV variants.";
CM_ SG_ 1071 EngAoutIdl_N_Ntrl "Signal not transmitted on HEV variants and diesel.";
CM_ SG_ 1069 SlMde_D_Stat "IPC and HUD_ADV Receve from HS3 FGW 0x42D, not HS3 0x38A, MSG DCR 506.";
CM_ SG_ 1069 SlMde_D_RqDsply "IPC and HUD_ADV Receve from HS3 FGW 0x42D, not HS3 0x38A, MSG DCR 506.";
CM_ SG_ 1069 ObdWarmUp_B_Complt "Signal not transmitted on gas and diesel variants.";
CM_ SG_ 1069 EngMsgTxt_D_Rq "Signal not transmitted on diesel variants.";
CM_ SG_ 1069 EngClnt_Te_ActlDiag "Signal not transmitted on gas variants.";
CM_ SG_ 1069 EngLoad_Pc_CalcDiag "Signal not transmitted on gas variants.";
CM_ SG_ 1069 ApedPos_Pc_ActlDiag "Signal not transmitted on gas variants.";
CM_ SG_ 1057 FohEng_D_Rq "Signal not transmitted on vehicles that do not have the fuel operated heater feature.";
CM_ SG_ 1057 EngIdlShutDown_D_Stat "Signal not transmitted on diesel variants.";
CM_ SG_ 1057 FUEL_ALCOHOL_PERCNT "signal not transmitted on diesel and HEV variants.";
CM_ SG_ 1057 TrnTotTq_Rt_Est "Signal not transmitted on gas and HEV variants.";
CM_ SG_ 1057 TrnTotLss_Tq_Est "Signal not transmitted on gas and HEV variants.";
CM_ SG_ 1057 VehVLimStat_D_Actl "Signal not transmitted on gas and HEV variants.";
CM_ SG_ 1057 VehVLimActv_B_Actl "Signal not transmitted on gas and HEV variants.";
CM_ SG_ 562 GearNtrl_No_Cs "Powersplit HEVs with HF45, HPCM will Tx  this message.  For all other programs it will be Tx by PCM or TCM. ";
CM_ SG_ 562 GearNtrl_No_Cnt "Powersplit HEVs with HF45, HPCM will Tx  this message.  For all other programs it will be Tx by PCM or TCM. ";
CM_ SG_ 516 EngAout3_N_Actl "Signal not transmitted on gas and diesel variants.";
CM_ SG_ 516 ApedPos_Pc_ActlArb "ABSGenSigTimeoutTime=1000";
CM_ SG_ 516 ApedPosPcActl_No_Cnt "Signal not transmitted on gas and diesel variants.";
CM_ SG_ 516 ApedPosPcActl_No_Cs "Signal not transmitted on gas and diesel variants.";
CM_ SG_ 514 GearRvrse_D_Actl "Do not implement GearRvrse_D_Actl  until eTracker 8804151 is approved, 11/24/09";
CM_ SG_ 512 PrplWhlTotTqRq_No_Cs "Signal not transmitted on gas variants.";
CM_ SG_ 512 PrplWhlTotTqRq_No_Cnt "Signal not transmitted on gas variants.";
CM_ SG_ 377 FuelFlw_Vl_Dsply "Signal not transmitted on diesel variants.";
CM_ SG_ 377 FuelFillInlet_B_Dsply "Signal not transmitted on diesel variants.";
CM_ SG_ 377 OdoCount "Signal not transmitted on diesel variants.";
CM_ SG_ 377 EngOilLife_Pc_Actl "Signal not transmitted on diesel variants.";
CM_ SG_ 377 TrnKickDown_B_RqDrv "Signal not transmitted on diesel variants.";
CM_ SG_ 377 AirCondRec_B_Rq "Signal not transmitted on diesel variants.";
CM_ SG_ 377 AirCondClutch_B_Stats "Signal not transmitted on diesel variants.";
CM_ SG_ 376 EngAout_Aa_Actl "Signal not transmitted on HEV variants.";
CM_ SG_ 359 TrnAin_Tq_Actl "Signal not transmitted on HEV variances.";
CM_ SG_ 359 TrnAinTq_D_Qf "Signal not transmitted on HEV variances.";
CM_ SG_ 358 AutoStopPtDelta_I_Est "Signal not transmitted on vehicles that do not have autostop/stop-start feature.";
CM_ SG_ 358 HiElPwInhbt_B_Stat "Signal not transmitted on HEV programs";
CM_ SG_ 357 BpedDrvAppl_D_Actl "CCMGenSigTimeoutTime=1000";
CM_ SG_ 357 CcStat_D_Actl "ABSGenSigTimeoutTime=1000";
CM_ SG_ 357 AccStopMde_D_Rq "ABSGenSigTimeoutTime=1000";
CM_ SG_ 342 EngOvrhtMitgActv_D_Ind "Signal not transmitted on diesel.";
CM_ SG_ 342 EngGoutLss_Tq_Est "Signal not transmitted on gas and diesel variants.";
CM_ BO_ 71 "Provide target function info. to control function of PATS";
CM_ SG_ 935 Side_Detect_R_Illum "DDMGenSigTimeoutTime=2000";
CM_ SG_ 935 SodRight_D_Stat "IPCGenSigTimeoutTime=1600";
CM_ SG_ 935 SodSnsRight_D_Stat "IPCGenSigTimeoutTime=1600";
CM_ SG_ 935 SodAlrtRight_D_Stat "DDMGenSigTimeoutTime=2000";
CM_ SG_ 935 CtaInnrRight_D_Stat "IPCGenSigTimeoutTime=1600";
CM_ SG_ 1050 Outside_Air_Temp_Stat "Filtered value, i.e. same as disply for customer";
CM_ SG_ 942 PrkAidRdiusRight_L_Dsply "MSGDCR 679, set all signals to OnChange";
CM_ SG_ 942 PrkAidRdiusLeft_L_Dsply "MSGDCR 679, set all signals to OnChange";
CM_ SG_ 942 PrkAidDrvDir_D_Stat "MSGDCR 679, set all signals to OnChange";
BA_DEF_ BO_  "VFrameFormat" ENUM  "StandardCAN","ExtendedCAN","reserved","reserved","reserved","reserved","reserved","reserved","reserved","reserved","reserved","reserved","reserved","reserved","StandardCAN_FD","ExtendedCAN_FD";
BA_DEF_  "BusType" STRING ;
BA_DEF_ SG_  "GenSigSendType" ENUM  "Cyclic","OnWrite","vector_leerstring","OnChange","vector_leerstring","IfActive","vector_leerstring","NoSigSendType";
BA_DEF_ SG_  "GenSigInactiveValue" INT 0 100000;
BA_DEF_ SG_  "WakeupSignal" ENUM  "No","Yes";
BA_DEF_ SG_  "CrossOver_InfoCAN" ENUM  "No","Yes";
BA_DEF_ SG_  "UsedOnPgmDBC" ENUM  "No","Yes";
BA_DEF_ SG_  "GenSigStartValue" INT 0 1000000000;
BA_DEF_ SG_  "ContentDependant" ENUM  "No","Yes";
BA_DEF_ SG_  "MetaData" ENUM  "No","Yes";
BA_DEF_ SG_  "U_P702_MY2021_Rx" ENUM  "No","Yes";
BA_DEF_ SG_  "U_CX727_MY2021_Tx" ENUM  "No","Yes";
BA_DEF_ SG_  "U_P702_MY2021_Tx" ENUM  "No","Yes";
BA_DEF_ BO_  "GenMsgILSupport" ENUM  "No","Yes";
BA_DEF_ BO_  "DiagResponse" ENUM  "No","Yes";
BA_DEF_ BO_  "DiagRequest" ENUM  "No","Yes";
BA_DEF_ BO_  "DiagState" ENUM  "No","Yes";
BA_DEF_ BO_  "TpApplType" STRING ;
BA_DEF_ BO_  "NmAsrMessage" ENUM  "No","Yes";
BA_DEF_ BO_  "MessageGateway" ENUM  "No","Yes";
BA_DEF_ BO_  "AuthFreshnessCounterSyncAttempt" INT 0 2;
BA_DEF_ BO_  "GenMsgSendType" ENUM  "FixedPeriodic","Event","EnabledPeriodic","NotUsed","NotUsed","EventPeriodic","NotUsed","NotUsed","NoMsgSendType";
BA_DEF_ BO_  "GenMsgCycleTime" INT 0 100000;
BA_DEF_ BO_  "GenMsgDelayTime" INT 0 1000;
BA_DEF_ BO_  "GenMsgNrOfRepetition" INT 0 100;
BA_DEF_ BO_  "GenMsgStartDelayTime" INT 0 10000;
BA_DEF_ BO_  "EventRateOfChange" INT 10 10000;
BA_DEF_ BO_  "FrameGatewayId" HEX 0 1407;
BA_DEF_ BO_  "NetworkInitialization" ENUM  "No","Yes";
BA_DEF_ BO_  "FrameGatewayNetwork" STRING ;
BA_DEF_ BU_  "GatewayECU" ENUM  "No","Yes";
BA_DEF_ BU_  "PackageID" STRING ;
BA_DEF_ BU_  "NosPackage" ENUM  "None","I3_1","I3_2","1.0.1","RP","EuCD","Volcano","I3_3","FNOS_Autosar";
BA_DEF_ BU_  "ILUsed" ENUM  "No","Yes";
BA_DEF_ BU_  "NmStationAddress" INT 0 255;
BA_DEF_ BU_  "EOL_SB_Flash" ENUM  "GGDS","GDS","NONE","vector_leerstring";
BA_DEF_ BU_  "DiagNode" ENUM  "GGDS","GDS","NONE";
BA_DEF_ BU_  "PowerType" ENUM  "Switched","Latched","Sleep","vector_leerstring","vector_leerstring";
BA_DEF_ BU_  "NmAsrNode" ENUM  "No","Yes";
BA_DEF_ BU_  "NmAsrNodeIdentifier" HEX 128 255;
BA_DEF_ BU_  "NodeStartUpTime" INT 0 10000;
BA_DEF_ BU_  "NodeWakeUpTime" INT 0 10000;
BA_DEF_ BU_  "Terminator" ENUM  "No","Yes";
BA_DEF_  "NmMessageCount" INT 0 128;
BA_DEF_  "NmBaseAddress" HEX 1280 1280;
BA_DEF_  "VersionYear" INT 2000 3000;
BA_DEF_  "VersionMonth" INT 1 12;
BA_DEF_  "Manufacturer" STRING ;
BA_DEF_  "VersionDay" INT 1 31;
BA_DEF_  "DBName" STRING ;
BA_DEF_  "NmAsrBaseAddress" HEX 1408 1408;
BA_DEF_  "NmAsrMessageCount" INT 128 128;
BA_DEF_  "NetworkSpeed" ENUM  "500kBits/s","125kBit/s";
BA_DEF_  "NmType" STRING ;
BA_DEF_  "CMDB_Version" STRING ;
BA_DEF_  "StarNetworkGwType" ENUM  "0=NotDefined","1=HS1","2=HS2","3=HS3","4=HS4","5=HS5","6=MS1","7=HS6","8=HS7","9=MS2","10=FD1";
BA_DEF_  "VersionNumber" INT 0 10000;
BA_DEF_DEF_  "VFrameFormat" "ExtendedCAN_FD";
BA_DEF_DEF_  "BusType" "";
BA_DEF_DEF_  "GenSigSendType" "NoSigSendType";
BA_DEF_DEF_  "GenSigInactiveValue" 0;
BA_DEF_DEF_  "WakeupSignal" "No";
BA_DEF_DEF_  "CrossOver_InfoCAN" "No";
BA_DEF_DEF_  "UsedOnPgmDBC" "Yes";
BA_DEF_DEF_  "GenSigStartValue" 0;
BA_DEF_DEF_  "ContentDependant" "No";
BA_DEF_DEF_  "MetaData" "No";
BA_DEF_DEF_  "U_P702_MY2021_Rx" "No";
BA_DEF_DEF_  "U_CX727_MY2021_Tx" "No";
BA_DEF_DEF_  "U_P702_MY2021_Tx" "No";
BA_DEF_DEF_  "GenMsgILSupport" "Yes";
BA_DEF_DEF_  "DiagResponse" "No";
BA_DEF_DEF_  "DiagRequest" "No";
BA_DEF_DEF_  "DiagState" "No";
BA_DEF_DEF_  "TpApplType" "";
BA_DEF_DEF_  "NmAsrMessage" "No";
BA_DEF_DEF_  "MessageGateway" "No";
BA_DEF_DEF_  "AuthFreshnessCounterSyncAttempt" 2;
BA_DEF_DEF_  "GenMsgSendType" "NoMsgSendType";
BA_DEF_DEF_  "GenMsgCycleTime" 0;
BA_DEF_DEF_  "GenMsgDelayTime" 20;
BA_DEF_DEF_  "GenMsgNrOfRepetition" 1;
BA_DEF_DEF_  "GenMsgStartDelayTime" 0;
BA_DEF_DEF_  "EventRateOfChange" 10000;
BA_DEF_DEF_  "FrameGatewayId" 0;
BA_DEF_DEF_  "NetworkInitialization" "Yes";
BA_DEF_DEF_  "FrameGatewayNetwork" "NONE";
BA_DEF_DEF_  "GatewayECU" "No";
BA_DEF_DEF_  "PackageID" "08.05.00.00.71.xx.xx.rr.00.00";
BA_DEF_DEF_  "NosPackage" "I3_3";
BA_DEF_DEF_  "ILUsed" "Yes";
BA_DEF_DEF_  "NmStationAddress" 0;
BA_DEF_DEF_  "EOL_SB_Flash" "GGDS";
BA_DEF_DEF_  "DiagNode" "GGDS";
BA_DEF_DEF_  "PowerType" "Switched";
BA_DEF_DEF_  "NmAsrNode" "No";
BA_DEF_DEF_  "NmAsrNodeIdentifier" 128;
BA_DEF_DEF_  "NodeStartUpTime" 250;
BA_DEF_DEF_  "NodeWakeUpTime" 10;
BA_DEF_DEF_  "Terminator" "No";
BA_DEF_DEF_  "NmMessageCount" 128;
BA_DEF_DEF_  "NmBaseAddress" 1280;
BA_DEF_DEF_  "VersionYear" 2011;
BA_DEF_DEF_  "VersionMonth" 1;
BA_DEF_DEF_  "Manufacturer" "Ford";
BA_DEF_DEF_  "VersionDay" 1;
BA_DEF_DEF_  "DBName" "";
BA_DEF_DEF_  "NmAsrBaseAddress" 1408;
BA_DEF_DEF_  "NmAsrMessageCount" 128;
BA_DEF_DEF_  "NetworkSpeed" "500kBits/s";
BA_DEF_DEF_  "NmType" "Ford-OSEK";
BA_DEF_DEF_  "CMDB_Version" "v11.01";
BA_DEF_DEF_  "StarNetworkGwType" "0=NotDefined";
BA_DEF_DEF_  "VersionNumber" 1;
BA_ "BusType" "CAN FD";
BA_ "VersionNumber" 5;
BA_ "CMDB_Version" "B_v17.07";
BA_ "VersionDay" 30;
BA_ "VersionMonth" 11;
BA_ "VersionYear" 2017;
BA_ "DBName" "FD1_CAN";
BA_ "NmStationAddress" BU_ HCM_FD 55;
BA_ "NodeStartUpTime" BU_ IPMA_ADAS 300;
BA_ "NmStationAddress" BU_ IPMA_ADAS 28;
BA_ "Terminator" BU_ PSCM_FD 1;
BA_ "NmAsrNodeIdentifier" BU_ PSCM_FD 181;
BA_ "PowerType" BU_ PSCM_FD 1;
BA_ "NmStationAddress" BU_ PSCM_FD 53;
BA_ "NodeWakeUpTime" BU_ ABS_ESC 300;
BA_ "NodeStartUpTime" BU_ ABS_ESC 1000;
BA_ "NmAsrNodeIdentifier" BU_ ABS_ESC 150;
BA_ "NmAsrNode" BU_ ABS_ESC 1;
BA_ "PowerType" BU_ ABS_ESC 2;
BA_ "NmStationAddress" BU_ ABS_ESC 22;
BA_ "NodeWakeUpTime" BU_ TCCM_FD 25;
BA_ "NodeStartUpTime" BU_ TCCM_FD 1000;
BA_ "NmAsrNodeIdentifier" BU_ TCCM_FD 161;
BA_ "NmAsrNode" BU_ TCCM_FD 1;
BA_ "NmStationAddress" BU_ TCCM_FD 33;
BA_ "NodeWakeUpTime" BU_ TCM_DSL_FD 150;
BA_ "NodeStartUpTime" BU_ TCM_DSL_FD 1000;
BA_ "NmAsrNodeIdentifier" BU_ TCM_DSL_FD 160;
BA_ "NmAsrNode" BU_ TCM_DSL_FD 1;
BA_ "PowerType" BU_ TCM_DSL_FD 2;
BA_ "NmStationAddress" BU_ TCM_DSL_FD 32;
BA_ "NosPackage" BU_ TCM_DSL_FD 4;
BA_ "Terminator" BU_ PCM_HEV_FD 1;
BA_ "NodeStartUpTime" BU_ PCM_HEV_FD 350;
BA_ "NmAsrNodeIdentifier" BU_ PCM_HEV_FD 149;
BA_ "NmAsrNode" BU_ PCM_HEV_FD 1;
BA_ "PowerType" BU_ PCM_HEV_FD 1;
BA_ "NmStationAddress" BU_ PCM_HEV_FD 21;
BA_ "Terminator" BU_ PCM_FD 1;
BA_ "NodeStartUpTime" BU_ PCM_FD 350;
BA_ "NmAsrNodeIdentifier" BU_ PCM_FD 149;
BA_ "NmAsrNode" BU_ PCM_FD 1;
BA_ "PowerType" BU_ PCM_FD 1;
BA_ "NmStationAddress" BU_ PCM_FD 21;
BA_ "Terminator" BU_ ECM_Diesel 1;
BA_ "NmAsrNodeIdentifier" BU_ ECM_Diesel 149;
BA_ "NmAsrNode" BU_ ECM_Diesel 1;
BA_ "PowerType" BU_ ECM_Diesel 1;
BA_ "NmStationAddress" BU_ ECM_Diesel 21;
BA_ "Terminator" BU_ GWM_ECG 1;
BA_ "NodeStartUpTime" BU_ GWM_ECG 100;
BA_ "NmAsrNodeIdentifier" BU_ GWM_ECG 158;
BA_ "NmAsrNode" BU_ GWM_ECG 1;
BA_ "PowerType" BU_ GWM_ECG 2;
BA_ "NmStationAddress" BU_ GWM_ECG 30;
BA_ "NosPackage" BU_ GWM_ECG 4;
BA_ "GatewayECU" BU_ GWM_ECG 1;
BA_ "VFrameFormat" BO_ 1632 0;
BA_ "GenMsgILSupport" BO_ 1632 0;
BA_ "GenMsgSendType" BO_ 1632 1;
BA_ "NetworkInitialization" BO_ 1632 0;
BA_ "VFrameFormat" BO_ 1633 0;
BA_ "GenMsgSendType" BO_ 1633 1;
BA_ "GenMsgILSupport" BO_ 1633 0;
BA_ "NetworkInitialization" BO_ 1633 0;
BA_ "FrameGatewayId" BO_ 1070 1070;
BA_ "FrameGatewayNetwork" BO_ 1070 "HS1_CAN";
BA_ "VFrameFormat" BO_ 1070 14;
BA_ "FrameGatewayId" BO_ 868 868;
BA_ "FrameGatewayNetwork" BO_ 868 "HS1_CAN";
BA_ "VFrameFormat" BO_ 868 14;
BA_ "FrameGatewayId" BO_ 867 867;
BA_ "FrameGatewayNetwork" BO_ 867 "HS1_CAN";
BA_ "VFrameFormat" BO_ 867 14;
BA_ "FrameGatewayId" BO_ 866 866;
BA_ "FrameGatewayNetwork" BO_ 866 "HS1_CAN";
BA_ "VFrameFormat" BO_ 866 14;
BA_ "FrameGatewayId" BO_ 865 865;
BA_ "FrameGatewayNetwork" BO_ 865 "HS1_CAN";
BA_ "VFrameFormat" BO_ 865 14;
BA_ "GenMsgCycleTime" BO_ 878 1000;
BA_ "GenMsgSendType" BO_ 878 5;
BA_ "VFrameFormat" BO_ 878 14;
BA_ "FrameGatewayNetwork" BO_ 924 "HS1_CAN";
BA_ "FrameGatewayId" BO_ 924 924;
BA_ "VFrameFormat" BO_ 924 14;
BA_ "FrameGatewayNetwork" BO_ 923 "HS1_CAN";
BA_ "FrameGatewayId" BO_ 923 923;
BA_ "VFrameFormat" BO_ 923 14;
BA_ "FrameGatewayNetwork" BO_ 922 "HS1_CAN";
BA_ "FrameGatewayId" BO_ 922 922;
BA_ "VFrameFormat" BO_ 922 14;
BA_ "GenMsgDelayTime" BO_ 2030 0;
BA_ "GenMsgSendType" BO_ 2030 1;
BA_ "DiagResponse" BO_ 2030 1;
BA_ "GenMsgILSupport" BO_ 2030 0;
BA_ "VFrameFormat" BO_ 2030 14;
BA_ "GenMsgCycleTime" BO_ 1137 1000;
BA_ "GenMsgSendType" BO_ 1137 0;
BA_ "VFrameFormat" BO_ 1137 14;
BA_ "GenMsgCycleTime" BO_ 1090 1000;
BA_ "GenMsgSendType" BO_ 1090 0;
BA_ "VFrameFormat" BO_ 1090 14;
BA_ "GenMsgCycleTime" BO_ 872 100;
BA_ "GenMsgSendType" BO_ 872 0;
BA_ "VFrameFormat" BO_ 872 14;
BA_ "GenMsgCycleTime" BO_ 870 100;
BA_ "GenMsgSendType" BO_ 870 0;
BA_ "VFrameFormat" BO_ 870 14;
BA_ "GenMsgCycleTime" BO_ 1010 50;
BA_ "GenMsgSendType" BO_ 1010 0;
BA_ "VFrameFormat" BO_ 1010 14;
BA_ "FrameGatewayNetwork" BO_ 589 "HS1_CAN";
BA_ "FrameGatewayId" BO_ 589 589;
BA_ "VFrameFormat" BO_ 589 14;
BA_ "FrameGatewayNetwork" BO_ 588 "HS1_CAN";
BA_ "FrameGatewayId" BO_ 588 588;
BA_ "VFrameFormat" BO_ 588 14;
BA_ "FrameGatewayNetwork" BO_ 587 "HS1_CAN";
BA_ "FrameGatewayId" BO_ 587 587;
BA_ "VFrameFormat" BO_ 587 14;
BA_ "FrameGatewayNetwork" BO_ 1116 "HS3_CAN";
BA_ "FrameGatewayId" BO_ 1116 1116;
BA_ "VFrameFormat" BO_ 1116 14;
BA_ "GenMsgDelayTime" BO_ 1844 0;
BA_ "GenMsgSendType" BO_ 1844 1;
BA_ "DiagRequest" BO_ 1844 1;
BA_ "GenMsgILSupport" BO_ 1844 0;
BA_ "VFrameFormat" BO_ 1844 14;
BA_ "FrameGatewayNetwork" BO_ 954 "HS1_CAN";
BA_ "FrameGatewayId" BO_ 954 954;
BA_ "VFrameFormat" BO_ 954 14;
BA_ "GenMsgDelayTime" BO_ 1852 0;
BA_ "GenMsgSendType" BO_ 1852 1;
BA_ "DiagResponse" BO_ 1852 1;
BA_ "GenMsgILSupport" BO_ 1852 0;
BA_ "VFrameFormat" BO_ 1852 14;
BA_ "GenMsgCycleTime" BO_ 989 1000;
BA_ "GenMsgSendType" BO_ 989 5;
BA_ "VFrameFormat" BO_ 989 14;
BA_ "GenMsgCycleTime" BO_ 1006 1000;
BA_ "GenMsgSendType" BO_ 1006 5;
BA_ "VFrameFormat" BO_ 1006 14;
BA_ "FrameGatewayNetwork" BO_ 992 "HS3_CAN";
BA_ "FrameGatewayId" BO_ 992 992;
BA_ "VFrameFormat" BO_ 992 14;
BA_ "GenMsgCycleTime" BO_ 820 1000;
BA_ "GenMsgSendType" BO_ 820 5;
BA_ "VFrameFormat" BO_ 820 14;
BA_ "GenMsgDelayTime" BO_ 1630 0;
BA_ "GenMsgSendType" BO_ 1630 1;
BA_ "DiagRequest" BO_ 1630 1;
BA_ "GenMsgILSupport" BO_ 1630 0;
BA_ "VFrameFormat" BO_ 1630 14;
BA_ "GenMsgSendType" BO_ 1713 1;
BA_ "TpApplType" BO_ 1713 "DiagUUDTResponse";
BA_ "GenMsgILSupport" BO_ 1713 0;
BA_ "VFrameFormat" BO_ 1713 14;
BA_ "GenMsgSendType" BO_ 1712 1;
BA_ "TpApplType" BO_ 1712 "DiagUUDTResponse";
BA_ "GenMsgILSupport" BO_ 1712 0;
BA_ "VFrameFormat" BO_ 1712 14;
BA_ "GenMsgDelayTime" BO_ 2025 0;
BA_ "GenMsgSendType" BO_ 2025 1;
BA_ "DiagResponse" BO_ 2025 1;
BA_ "GenMsgILSupport" BO_ 2025 0;
BA_ "VFrameFormat" BO_ 2025 14;
BA_ "GenMsgDelayTime" BO_ 2024 0;
BA_ "GenMsgSendType" BO_ 2024 1;
BA_ "DiagResponse" BO_ 2024 1;
BA_ "GenMsgILSupport" BO_ 2024 0;
BA_ "VFrameFormat" BO_ 2024 14;
BA_ "GenMsgDelayTime" BO_ 2017 0;
BA_ "GenMsgSendType" BO_ 2017 1;
BA_ "DiagRequest" BO_ 2017 1;
BA_ "GenMsgILSupport" BO_ 2017 0;
BA_ "VFrameFormat" BO_ 2017 14;
BA_ "GenMsgDelayTime" BO_ 2016 0;
BA_ "GenMsgSendType" BO_ 2016 1;
BA_ "DiagRequest" BO_ 2016 1;
BA_ "GenMsgILSupport" BO_ 2016 0;
BA_ "VFrameFormat" BO_ 2016 14;
BA_ "GenMsgDelayTime" BO_ 1759 0;
BA_ "GenMsgSendType" BO_ 1759 1;
BA_ "DiagState" BO_ 1759 1;
BA_ "GenMsgILSupport" BO_ 1759 0;
BA_ "VFrameFormat" BO_ 1759 14;
BA_ "GenMsgDelayTime" BO_ 1897 0;
BA_ "GenMsgSendType" BO_ 1897 1;
BA_ "DiagResponse" BO_ 1897 1;
BA_ "GenMsgILSupport" BO_ 1897 0;
BA_ "VFrameFormat" BO_ 1897 14;
BA_ "GenMsgDelayTime" BO_ 1814 0;
BA_ "GenMsgSendType" BO_ 1814 1;
BA_ "DiagRequest" BO_ 1814 1;
BA_ "GenMsgILSupport" BO_ 1814 0;
BA_ "VFrameFormat" BO_ 1814 14;
BA_ "GenMsgSendType" BO_ 1701 1;
BA_ "TpApplType" BO_ 1701 "DiagUUDTResponse";
BA_ "GenMsgILSupport" BO_ 1701 0;
BA_ "VFrameFormat" BO_ 1701 14;
BA_ "GenMsgSendType" BO_ 1700 1;
BA_ "TpApplType" BO_ 1700 "DiagUUDTResponse";
BA_ "GenMsgILSupport" BO_ 1700 0;
BA_ "VFrameFormat" BO_ 1700 14;
BA_ "GenMsgSendType" BO_ 1697 1;
BA_ "TpApplType" BO_ 1697 "DiagUUDTResponse";
BA_ "GenMsgILSupport" BO_ 1697 0;
BA_ "VFrameFormat" BO_ 1697 14;
BA_ "GenMsgSendType" BO_ 1696 1;
BA_ "TpApplType" BO_ 1696 "DiagUUDTResponse";
BA_ "GenMsgILSupport" BO_ 1696 0;
BA_ "VFrameFormat" BO_ 1696 14;
BA_ "GenMsgCycleTime" BO_ 1429 1000;
BA_ "GenMsgSendType" BO_ 1429 0;
BA_ "NmAsrMessage" BO_ 1429 1;
BA_ "GenMsgILSupport" BO_ 1429 0;
BA_ "VFrameFormat" BO_ 1429 14;
BA_ "GenMsgCycleTime" BO_ 1100 1000;
BA_ "GenMsgSendType" BO_ 1100 5;
BA_ "VFrameFormat" BO_ 1100 14;
BA_ "GenMsgCycleTime" BO_ 1098 500;
BA_ "GenMsgSendType" BO_ 1098 5;
BA_ "VFrameFormat" BO_ 1098 14;
BA_ "GenMsgCycleTime" BO_ 1086 50;
BA_ "GenMsgSendType" BO_ 1086 0;
BA_ "VFrameFormat" BO_ 1086 14;
BA_ "GenMsgSendType" BO_ 1085 0;
BA_ "GenMsgCycleTime" BO_ 1085 50;
BA_ "VFrameFormat" BO_ 1085 14;
BA_ "GenMsgCycleTime" BO_ 1071 30;
BA_ "GenMsgSendType" BO_ 1071 0;
BA_ "VFrameFormat" BO_ 1071 14;
BA_ "GenMsgCycleTime" BO_ 1069 100;
BA_ "GenMsgSendType" BO_ 1069 0;
BA_ "VFrameFormat" BO_ 1069 14;
BA_ "GenMsgCycleTime" BO_ 1060 100;
BA_ "GenMsgSendType" BO_ 1060 0;
BA_ "VFrameFormat" BO_ 1060 14;
BA_ "GenMsgCycleTime" BO_ 1057 100;
BA_ "GenMsgSendType" BO_ 1057 0;
BA_ "VFrameFormat" BO_ 1057 14;
BA_ "GenMsgCycleTime" BO_ 1055 100;
BA_ "GenMsgSendType" BO_ 1055 0;
BA_ "VFrameFormat" BO_ 1055 14;
BA_ "GenMsgCycleTime" BO_ 562 100;
BA_ "GenMsgSendType" BO_ 562 0;
BA_ "VFrameFormat" BO_ 562 14;
BA_ "GenMsgCycleTime" BO_ 523 1000;
BA_ "GenMsgSendType" BO_ 523 0;
BA_ "VFrameFormat" BO_ 523 14;
BA_ "GenMsgDelayTime" BO_ 517 10;
BA_ "GenMsgCycleTime" BO_ 517 20;
BA_ "GenMsgSendType" BO_ 517 0;
BA_ "VFrameFormat" BO_ 517 14;
BA_ "GenMsgDelayTime" BO_ 516 0;
BA_ "GenMsgCycleTime" BO_ 516 10;
BA_ "GenMsgSendType" BO_ 516 0;
BA_ "VFrameFormat" BO_ 516 14;
BA_ "GenMsgDelayTime" BO_ 514 10;
BA_ "GenMsgCycleTime" BO_ 514 20;
BA_ "GenMsgSendType" BO_ 514 0;
BA_ "VFrameFormat" BO_ 514 14;
BA_ "GenMsgDelayTime" BO_ 512 10;
BA_ "GenMsgCycleTime" BO_ 512 20;
BA_ "GenMsgSendType" BO_ 512 0;
BA_ "VFrameFormat" BO_ 512 14;
BA_ "GenMsgCycleTime" BO_ 381 100;
BA_ "GenMsgSendType" BO_ 381 0;
BA_ "VFrameFormat" BO_ 381 14;
BA_ "GenMsgCycleTime" BO_ 380 100;
BA_ "GenMsgSendType" BO_ 380 0;
BA_ "VFrameFormat" BO_ 380 14;
BA_ "GenMsgCycleTime" BO_ 377 100;
BA_ "GenMsgSendType" BO_ 377 0;
BA_ "VFrameFormat" BO_ 377 14;
BA_ "GenMsgCycleTime" BO_ 376 100;
BA_ "GenMsgSendType" BO_ 376 0;
BA_ "VFrameFormat" BO_ 376 14;
BA_ "GenMsgDelayTime" BO_ 373 10;
BA_ "GenMsgCycleTime" BO_ 373 20;
BA_ "GenMsgSendType" BO_ 373 0;
BA_ "VFrameFormat" BO_ 373 14;
BA_ "GenMsgDelayTime" BO_ 359 0;
BA_ "GenMsgCycleTime" BO_ 359 10;
BA_ "GenMsgSendType" BO_ 359 0;
BA_ "VFrameFormat" BO_ 359 14;
BA_ "GenMsgCycleTime" BO_ 358 100;
BA_ "GenMsgSendType" BO_ 358 0;
BA_ "VFrameFormat" BO_ 358 14;
BA_ "GenMsgDelayTime" BO_ 357 10;
BA_ "GenMsgCycleTime" BO_ 357 20;
BA_ "GenMsgSendType" BO_ 357 0;
BA_ "VFrameFormat" BO_ 357 14;
BA_ "GenMsgCycleTime" BO_ 355 100;
BA_ "GenMsgSendType" BO_ 355 0;
BA_ "VFrameFormat" BO_ 355 14;
BA_ "GenMsgCycleTime" BO_ 342 100;
BA_ "GenMsgSendType" BO_ 342 0;
BA_ "VFrameFormat" BO_ 342 14;
BA_ "GenMsgCycleTime" BO_ 71 20;
BA_ "GenMsgSendType" BO_ 71 0;
BA_ "GenMsgDelayTime" BO_ 71 10;
BA_ "VFrameFormat" BO_ 71 14;
BA_ "FrameGatewayNetwork" BO_ 137 "HS2_CAN";
BA_ "FrameGatewayId" BO_ 137 137;
BA_ "VFrameFormat" BO_ 137 14;
BA_ "FrameGatewayNetwork" BO_ 129 "HS2_CAN";
BA_ "FrameGatewayId" BO_ 129 129;
BA_ "VFrameFormat" BO_ 129 14;
BA_ "GenMsgCycleTime" BO_ 935 200;
BA_ "GenMsgSendType" BO_ 935 5;
BA_ "VFrameFormat" BO_ 935 14;
BA_ "FrameGatewayNetwork" BO_ 1108 "HS2_CAN";
BA_ "FrameGatewayId" BO_ 1108 1108;
BA_ "VFrameFormat" BO_ 1108 14;
BA_ "FrameGatewayNetwork" BO_ 1146 "MS1_CAN";
BA_ "FrameGatewayId" BO_ 1146 1098;
BA_ "VFrameFormat" BO_ 1146 14;
BA_ "FrameGatewayNetwork" BO_ 533 "HS3_CAN";
BA_ "FrameGatewayId" BO_ 533 533;
BA_ "VFrameFormat" BO_ 533 14;
BA_ "FrameGatewayNetwork" BO_ 1041 "HS1_CAN";
BA_ "FrameGatewayId" BO_ 1041 1041;
BA_ "VFrameFormat" BO_ 1041 14;
BA_ "FrameGatewayNetwork" BO_ 1067 "HS1_CAN";
BA_ "FrameGatewayId" BO_ 1067 1067;
BA_ "VFrameFormat" BO_ 1067 14;
BA_ "FrameGatewayNetwork" BO_ 1040 "HS1_CAN";
BA_ "FrameGatewayId" BO_ 1040 1040;
BA_ "VFrameFormat" BO_ 1040 14;
BA_ "FrameGatewayNetwork" BO_ 1144 "HS1_CAN";
BA_ "FrameGatewayId" BO_ 1144 1144;
BA_ "VFrameFormat" BO_ 1144 14;
BA_ "FrameGatewayNetwork" BO_ 1112 "HS1_CAN";
BA_ "FrameGatewayId" BO_ 1112 1112;
BA_ "VFrameFormat" BO_ 1112 14;
BA_ "FrameGatewayNetwork" BO_ 139 "HS2_CAN";
BA_ "FrameGatewayId" BO_ 139 139;
BA_ "VFrameFormat" BO_ 139 14;
BA_ "FrameGatewayNetwork" BO_ 1121 "HS2_CAN";
BA_ "FrameGatewayId" BO_ 1121 1121;
BA_ "VFrameFormat" BO_ 1121 14;
BA_ "FrameGatewayNetwork" BO_ 1120 "HS2_CAN";
BA_ "FrameGatewayId" BO_ 1120 1120;
BA_ "VFrameFormat" BO_ 1120 14;
BA_ "FrameGatewayNetwork" BO_ 1050 "MS1_CAN";
BA_ "FrameGatewayId" BO_ 1050 1050;
BA_ "VFrameFormat" BO_ 1050 14;
BA_ "GenMsgCycleTime" BO_ 942 1000;
BA_ "GenMsgSendType" BO_ 942 5;
BA_ "VFrameFormat" BO_ 942 14;
BA_ "GenMsgCycleTime" BO_ 1113 50;
BA_ "GenMsgSendType" BO_ 1113 0;
BA_ "VFrameFormat" BO_ 1113 14;
BA_ "GenMsgCycleTime" BO_ 1105 1000;
BA_ "GenMsgSendType" BO_ 1105 5;
BA_ "VFrameFormat" BO_ 1105 14;
BA_ "GenMsgCycleTime" BO_ 938 200;
BA_ "GenMsgSendType" BO_ 938 5;
BA_ "VFrameFormat" BO_ 938 14;
BA_ "GenMsgCycleTime" BO_ 939 200;
BA_ "GenMsgSendType" BO_ 939 5;
BA_ "VFrameFormat" BO_ 939 14;
BA_ "GenMsgDelayTime" BO_ 937 10;
BA_ "GenMsgCycleTime" BO_ 937 20;
BA_ "GenMsgSendType" BO_ 937 0;
BA_ "VFrameFormat" BO_ 937 14;
BA_ "GenSigSendType" SG_ 878 DcacOn_B_Rq 3;
BA_ "GenSigSendType" SG_ 878 DcacSys_B_Falt 3;
BA_ "GenSigSendType" SG_ 878 DcacLedCtl_D_Rq 3;
BA_ "GenSigStartValue" SG_ 1137 RngPerChrgAvg_L_Dsply 4094;
BA_ "GenSigStartValue" SG_ 1090 VehElRnge_L_Dsply 4095;
BA_ "CrossOver_InfoCAN" SG_ 1090 VehElRnge_L_Dsply 1;
BA_ "CrossOver_InfoCAN" SG_ 872 PlgActvArb_B_Dsply 1;
BA_ "GenSigStartValue" SG_ 870 RngPerChrgInst_L_Dsply 4094;
BA_ "U_P702_MY2021_Rx" SG_ 1010 UrbanAreaDetct_D_Stat 1;
BA_ "U_P702_MY2021_Rx" SG_ 1010 LightRng_L_Max 1;
BA_ "U_P702_MY2021_Rx" SG_ 1010 LightPathOffst_L_Actl 1;
BA_ "GenSigStartValue" SG_ 1010 LightPathOffst_L_Actl 512;
BA_ "U_P702_MY2021_Rx" SG_ 1010 LightPath_An_Actl 1;
BA_ "GenSigStartValue" SG_ 1010 LightPath_An_Actl 1000;
BA_ "U_P702_MY2021_Rx" SG_ 1010 LightCurv_NoRate_Actl 1;
BA_ "GenSigStartValue" SG_ 1010 LightCurv_NoRate_Actl 4096;
BA_ "U_P702_MY2021_Rx" SG_ 1010 LightCurv_No_Actl 1;
BA_ "GenSigStartValue" SG_ 1010 LightCurv_No_Actl 1000;
BA_ "WakeupSignal" SG_ 588 HvacAirFlw_B_RqBatt 1;
BA_ "GenSigStartValue" SG_ 588 BattTracSoc2_Pc_Actl 16382;
BA_ "GenSigStartValue" SG_ 588 BattTracSoc_Pc_Dsply 254;
BA_ "CrossOver_InfoCAN" SG_ 588 BattTracSoc_Pc_Dsply 1;
BA_ "GenSigStartValue" SG_ 588 BattTracClntIn_Te_Actl 75;
BA_ "GenSigStartValue" SG_ 588 BattTrac_Te_Actl 150;
BA_ "GenSigStartValue" SG_ 588 HvacRec_D_RqMxBatt 10;
BA_ "GenSigStartValue" SG_ 587 BattTracClnt_Te_Actl 164;
BA_ "GenSigStartValue" SG_ 587 BattTracClnt_Te_Rq 190;
BA_ "CrossOver_InfoCAN" SG_ 587 BattTracWarnLamp_B_Rq 1;
BA_ "CrossOver_InfoCAN" SG_ 587 BattTracSrvcRqd_B_Rq 1;
BA_ "GenSigStartValue" SG_ 587 BattTracSoc_Pc_MxPrtct 700;
BA_ "GenSigStartValue" SG_ 587 BattTracSoc_Pc_MnPrtct 300;
BA_ "GenSigStartValue" SG_ 587 BattTracSoc_Pc_LimLo 400;
BA_ "GenSigStartValue" SG_ 587 BattTracSoc_Pc_LimHi 600;
BA_ "U_P702_MY2021_Rx" SG_ 1116 TrlrAidSetup_D2_Rq 1;
BA_ "U_P702_MY2021_Rx" SG_ 1116 TrlrAidEnbl_D2_Rq 1;
BA_ "U_P702_MY2021_Rx" SG_ 1844 TesterPhysicalReqHCM 1;
BA_ "GenSigSendType" SG_ 1844 TesterPhysicalReqHCM 3;
BA_ "U_P702_MY2021_Rx" SG_ 954 GenericSwtch3_No_Actl 1;
BA_ "U_P702_MY2021_Rx" SG_ 954 GenericSwtch2_No_Actl 1;
BA_ "ContentDependant" SG_ 954 GenericSwtch2_No_Actl 1;
BA_ "U_P702_MY2021_Rx" SG_ 954 GenericSwtch1_No_Actl 1;
BA_ "U_P702_MY2021_Tx" SG_ 1852 TesterPhysicalResHCM 1;
BA_ "GenSigSendType" SG_ 1852 TesterPhysicalResHCM 3;
BA_ "U_P702_MY2021_Tx" SG_ 989 FeatNoHcm_No_Actl 1;
BA_ "CrossOver_InfoCAN" SG_ 989 FeatNoHcm_No_Actl 1;
BA_ "GenSigSendType" SG_ 989 FeatNoHcm_No_Actl 3;
BA_ "U_P702_MY2021_Tx" SG_ 989 FeatConfigHcmActl 1;
BA_ "CrossOver_InfoCAN" SG_ 989 FeatConfigHcmActl 1;
BA_ "GenSigSendType" SG_ 989 FeatConfigHcmActl 3;
BA_ "GenSigStartValue" SG_ 1006 PersIndexIpmb_D_Actl 4;
BA_ "CrossOver_InfoCAN" SG_ 1006 PersIndexIpmb_D_Actl 1;
BA_ "GenSigSendType" SG_ 1006 PersIndexIpmb_D_Actl 3;
BA_ "CrossOver_InfoCAN" SG_ 1006 FeatNoIpmbActl 1;
BA_ "GenSigSendType" SG_ 1006 FeatNoIpmbActl 3;
BA_ "CrossOver_InfoCAN" SG_ 1006 FeatConfigIpmbActl 1;
BA_ "GenSigSendType" SG_ 1006 FeatConfigIpmbActl 3;
BA_ "U_P702_MY2021_Rx" SG_ 992 MsgCntrPersIndex_D_Rq 1;
BA_ "GenSigStartValue" SG_ 992 MsgCntrPersIndex_D_Rq 4;
BA_ "CrossOver_InfoCAN" SG_ 992 MsgCntrPersIndex_D_Rq 1;
BA_ "U_P702_MY2021_Rx" SG_ 992 MsgCntrFeatConfigRq 1;
BA_ "CrossOver_InfoCAN" SG_ 992 MsgCntrFeatConfigRq 1;
BA_ "U_P702_MY2021_Rx" SG_ 992 MsgCntrFeatNoRq 1;
BA_ "CrossOver_InfoCAN" SG_ 992 MsgCntrFeatNoRq 1;
BA_ "U_P702_MY2021_Rx" SG_ 992 MsgCntrDsplyOp_D_Rq 1;
BA_ "CrossOver_InfoCAN" SG_ 992 MsgCntrDsplyOp_D_Rq 1;
BA_ "U_P702_MY2021_Tx" SG_ 820 AhbStatGfhbFdbk_D_Actl 1;
BA_ "GenSigSendType" SG_ 820 AhbStatGfhbFdbk_D_Actl 3;
BA_ "U_P702_MY2021_Tx" SG_ 820 HeadLghtDrvSide_B_Stat 1;
BA_ "GenSigSendType" SG_ 820 HeadLghtDrvSide_B_Stat 3;
BA_ "U_P702_MY2021_Tx" SG_ 820 HeadLghtHiOn_B_StatHcm 1;
BA_ "CrossOver_InfoCAN" SG_ 820 HeadLghtHiOn_B_StatHcm 1;
BA_ "GenSigSendType" SG_ 820 HeadLghtHiOn_B_StatHcm 3;
BA_ "U_P702_MY2021_Tx" SG_ 820 Adaptive_Hdlmp_Fault 1;
BA_ "CrossOver_InfoCAN" SG_ 820 Adaptive_Hdlmp_Fault 1;
BA_ "GenSigSendType" SG_ 820 Adaptive_Hdlmp_Fault 3;
BA_ "U_P702_MY2021_Rx" SG_ 1630 TesterPhysicalReqPSCM 1;
BA_ "GenSigSendType" SG_ 1630 TesterPhysicalReqPSCM 3;
BA_ "U_P702_MY2021_Tx" SG_ 1713 UUDTABSResponse2 1;
BA_ "U_P702_MY2021_Tx" SG_ 1712 UUDTABSResponse1 1;
BA_ "U_P702_MY2021_Tx" SG_ 2025 TesterPhysicalResTCM 1;
BA_ "U_P702_MY2021_Tx" SG_ 2024 TesterPhysicalResPCM 1;
BA_ "U_P702_MY2021_Rx" SG_ 2017 TesterPhysicalReqTCM 1;
BA_ "GenSigSendType" SG_ 2017 TesterPhysicalReqTCM 3;
BA_ "U_P702_MY2021_Rx" SG_ 2016 TesterPhysicalReqPCM 1;
BA_ "GenSigSendType" SG_ 2016 TesterPhysicalReqPCM 3;
BA_ "U_P702_MY2021_Rx" SG_ 1759 TesterFunctionalReq 1;
BA_ "CrossOver_InfoCAN" SG_ 1759 TesterFunctionalReq 1;
BA_ "GenSigSendType" SG_ 1759 TesterFunctionalReq 3;
BA_ "U_P702_MY2021_Tx" SG_ 1897 TesterPhysicalResTCCM 1;
BA_ "GenSigSendType" SG_ 1897 TesterPhysicalResTCCM 3;
BA_ "GenSigSendType" SG_ 1814 TesterPhysicalReqGWM_H1 3;
BA_ "U_P702_MY2021_Tx" SG_ 1701 UUDTTCMResponse2 1;
BA_ "U_P702_MY2021_Tx" SG_ 1700 UUDTTCMResponse1 1;
BA_ "U_P702_MY2021_Tx" SG_ 1697 UUDTPCMResponse2 1;
BA_ "U_P702_MY2021_Tx" SG_ 1696 UUDTPCMResponse1 1;
BA_ "U_P702_MY2021_Tx" SG_ 1429 PCM_GWOnBoardTester 1;
BA_ "U_P702_MY2021_Rx" SG_ 1429 PCM_GWOnBoardTester 1;
BA_ "ContentDependant" SG_ 1429 PCM_GWOnBoardTester 1;
BA_ "GenSigStartValue" SG_ 1429 PCM_GWOnBoardTester 255;
BA_ "U_P702_MY2021_Tx" SG_ 1429 PCM_GWNMProxy 1;
BA_ "U_P702_MY2021_Rx" SG_ 1429 PCM_GWNMProxy 1;
BA_ "ContentDependant" SG_ 1429 PCM_GWNMProxy 1;
BA_ "GenSigStartValue" SG_ 1429 PCM_GWNMProxy 255;
BA_ "U_P702_MY2021_Tx" SG_ 1429 PCM_AutoSarNMReserved4 1;
BA_ "U_P702_MY2021_Rx" SG_ 1429 PCM_AutoSarNMReserved4 1;
BA_ "ContentDependant" SG_ 1429 PCM_AutoSarNMReserved4 1;
BA_ "GenSigStartValue" SG_ 1429 PCM_AutoSarNMReserved4 255;
BA_ "U_P702_MY2021_Tx" SG_ 1429 PCM_AutoSarNMReserved3 1;
BA_ "U_P702_MY2021_Rx" SG_ 1429 PCM_AutoSarNMReserved3 1;
BA_ "ContentDependant" SG_ 1429 PCM_AutoSarNMReserved3 1;
BA_ "GenSigStartValue" SG_ 1429 PCM_AutoSarNMReserved3 255;
BA_ "U_P702_MY2021_Tx" SG_ 1429 PCM_AutoSarNMReserved2 1;
BA_ "U_P702_MY2021_Rx" SG_ 1429 PCM_AutoSarNMReserved2 1;
BA_ "ContentDependant" SG_ 1429 PCM_AutoSarNMReserved2 1;
BA_ "GenSigStartValue" SG_ 1429 PCM_AutoSarNMReserved2 255;
BA_ "U_P702_MY2021_Tx" SG_ 1429 PCM_AutoSarNMReserved1 1;
BA_ "U_P702_MY2021_Rx" SG_ 1429 PCM_AutoSarNMReserved1 1;
BA_ "ContentDependant" SG_ 1429 PCM_AutoSarNMReserved1 1;
BA_ "GenSigStartValue" SG_ 1429 PCM_AutoSarNMReserved1 255;
BA_ "U_P702_MY2021_Tx" SG_ 1429 PCM_AutoSarNMNodeId 1;
BA_ "U_P702_MY2021_Rx" SG_ 1429 PCM_AutoSarNMNodeId 1;
BA_ "ContentDependant" SG_ 1429 PCM_AutoSarNMNodeId 1;
BA_ "GenSigStartValue" SG_ 1429 PCM_AutoSarNMNodeId 149;
BA_ "U_P702_MY2021_Tx" SG_ 1429 PCM_AutoSarNMControl 1;
BA_ "U_P702_MY2021_Rx" SG_ 1429 PCM_AutoSarNMControl 1;
BA_ "ContentDependant" SG_ 1429 PCM_AutoSarNMControl 1;
BA_ "U_P702_MY2021_Tx" SG_ 1100 WakeAlarm1_T_Rq 1;
BA_ "GenSigStartValue" SG_ 1100 WakeAlarm1_T_Rq 32767;
BA_ "U_P702_MY2021_Tx" SG_ 1100 WakeAlarm1_B_Typ 1;
BA_ "WakeupSignal" SG_ 1100 WakeAlarm1_B_Typ 1;
BA_ "GenSigSendType" SG_ 1100 WakeAlarm1_B_Typ 3;
BA_ "U_P702_MY2021_Tx" SG_ 1100 Veh_V_DsplyTrailCtlSet 1;
BA_ "U_P702_MY2021_Tx" SG_ 1100 TrailCtlPt_B_Falt 1;
BA_ "GenSigSendType" SG_ 1100 TrailCtlPt_B_Falt 3;
BA_ "U_P702_MY2021_Tx" SG_ 1100 AutoTowAllw_D_StatMnu 1;
BA_ "GenSigSendType" SG_ 1100 AutoTowAllw_D_StatMnu 3;
BA_ "U_P702_MY2021_Tx" SG_ 1100 AutoTowActv_B_Stat 1;
BA_ "GenSigSendType" SG_ 1100 AutoTowActv_B_Stat 3;
BA_ "U_P702_MY2021_Tx" SG_ 1100 GrossTrainWeight_M_Est 1;
BA_ "U_P702_MY2021_Rx" SG_ 1100 GrossTrainWeight_M_Est 1;
BA_ "GenSigStartValue" SG_ 1100 GrossTrainWeight_M_Est 254;
BA_ "U_P702_MY2021_Tx" SG_ 1098 EdmVeh_V_Dsply 1;
BA_ "U_P702_MY2021_Tx" SG_ 1098 EdmSailMdeOn_B_Stat 1;
BA_ "GenSigSendType" SG_ 1098 EdmSailMdeOn_B_Stat 3;
BA_ "U_P702_MY2021_Tx" SG_ 1098 EdmPrev_Fe_Dsply 1;
BA_ "U_P702_MY2021_Tx" SG_ 1098 EdmMsgTxt_D_Rq 1;
BA_ "GenSigSendType" SG_ 1098 EdmMsgTxt_D_Rq 3;
BA_ "U_P702_MY2021_Tx" SG_ 1098 EdmLamp_D_Dsply 1;
BA_ "GenSigSendType" SG_ 1098 EdmLamp_D_Dsply 3;
BA_ "U_P702_MY2021_Tx" SG_ 1098 EdmCurrent_Fe_Dsply 1;
BA_ "U_P702_MY2021_Tx" SG_ 1098 EdmCmplnc_B_Dsply 1;
BA_ "GenSigSendType" SG_ 1098 EdmCmplnc_B_Dsply 3;
BA_ "U_P702_MY2021_Tx" SG_ 1098 EdmCmplnc_Pc_Dsply 1;
BA_ "U_P702_MY2021_Tx" SG_ 1086 EngMnfld_P_Actl 1;
BA_ "GenSigStartValue" SG_ 1086 EngMnfld_P_Actl 2068;
BA_ "U_P702_MY2021_Tx" SG_ 1086 FuelPumpPwr_B_Rq 1;
BA_ "U_P702_MY2021_Tx" SG_ 1086 BattULoChrg_U_Cmd 1;
BA_ "U_P702_MY2021_Tx" SG_ 1086 ElLoadCtl_D_Rq 1;
BA_ "ContentDependant" SG_ 1086 ElLoadCtl_D_Rq 1;
BA_ "U_P702_MY2021_Tx" SG_ 1085 ULoRgenTestMde_B_Stat 1;
BA_ "ContentDependant" SG_ 1085 ULoRgenTestMde_B_Stat 1;
BA_ "U_P702_MY2021_Tx" SG_ 1085 PwSrcULoOvrTe_B_Actl 1;
BA_ "U_P702_MY2021_Tx" SG_ 1085 PwSrcULoFalt_D_Stat 1;
BA_ "U_P702_MY2021_Tx" SG_ 1085 PwSrcULoDcnnt_B_Stat 1;
BA_ "U_P702_MY2021_Tx" SG_ 1085 PwSrcULo_Pc_Mx 1;
BA_ "U_P702_MY2021_Tx" SG_ 1085 PwSrcULoComm_B_Falt 1;
BA_ "ContentDependant" SG_ 1085 PwSrcULoComm_B_Falt 1;
BA_ "U_P702_MY2021_Tx" SG_ 1085 PwSrcULo_I_Mx 1;
BA_ "U_P702_MY2021_Rx" SG_ 1085 PwSrcULo_I_Mx 1;
BA_ "U_P702_MY2021_Tx" SG_ 1085 PwSrcULo_I_Actl 1;
BA_ "U_P702_MY2021_Rx" SG_ 1085 PwSrcULo_I_Actl 1;
BA_ "U_P702_MY2021_Tx" SG_ 1071 CluPdl_PcRate_Actl 1;
BA_ "ContentDependant" SG_ 1071 CluPdl_PcRate_Actl 1;
BA_ "CrossOver_InfoCAN" SG_ 1071 CluPdl_PcRate_Actl 1;
BA_ "U_P702_MY2021_Tx" SG_ 1071 CluPdlPos_Pc_Meas 1;
BA_ "U_P702_MY2021_Rx" SG_ 1071 CluPdlPos_Pc_Meas 1;
BA_ "ContentDependant" SG_ 1071 CluPdlPos_Pc_Meas 1;
BA_ "CrossOver_InfoCAN" SG_ 1071 CluPdlPos_Pc_Meas 1;
BA_ "U_P702_MY2021_Tx" SG_ 1071 CluPdlPosPcMeas_D_Qf 1;
BA_ "U_P702_MY2021_Rx" SG_ 1071 CluPdlPosPcMeas_D_Qf 1;
BA_ "MetaData" SG_ 1071 CluPdlPosPcMeas_D_Qf 1;
BA_ "ContentDependant" SG_ 1071 CluPdlPosPcMeas_D_Qf 1;
BA_ "GenSigStartValue" SG_ 1071 CluPdlPosPcMeas_D_Qf 1;
BA_ "CrossOver_InfoCAN" SG_ 1071 CluPdlPosPcMeas_D_Qf 1;
BA_ "U_P702_MY2021_Tx" SG_ 1071 EngAout_N_Dsply 1;
BA_ "U_P702_MY2021_Tx" SG_ 1071 EngAoutIdl_N_Ntrl 1;
BA_ "U_P702_MY2021_Rx" SG_ 1071 EngAoutIdl_N_Ntrl 1;
BA_ "ContentDependant" SG_ 1071 EngAoutIdl_N_Ntrl 1;
BA_ "CrossOver_InfoCAN" SG_ 1071 EngAoutIdl_N_Ntrl 1;
BA_ "U_P702_MY2021_Tx" SG_ 1069 SlMde_D_Stat 1;
BA_ "U_P702_MY2021_Tx" SG_ 1069 SlMde_D_RqDsply 1;
BA_ "U_P702_MY2021_Tx" SG_ 1069 IsaOffst_D_Stat 1;
BA_ "U_P702_MY2021_Tx" SG_ 1069 GrllShtrPos_D_Cmd 1;
BA_ "CrossOver_InfoCAN" SG_ 1069 GrllShtrPos_D_Cmd 1;
BA_ "U_P702_MY2021_Tx" SG_ 1069 GrllShtrPos_B_Falt 1;
BA_ "CrossOver_InfoCAN" SG_ 1069 GrllShtrPos_B_Falt 1;
BA_ "U_P702_MY2021_Tx" SG_ 1069 ObdWarmUp_B_Complt 1;
BA_ "ContentDependant" SG_ 1069 ObdWarmUp_B_Complt 1;
BA_ "CrossOver_InfoCAN" SG_ 1069 ObdWarmUp_B_Complt 1;
BA_ "U_P702_MY2021_Tx" SG_ 1069 EngMsgTxt_D_Rq 1;
BA_ "ContentDependant" SG_ 1069 EngMsgTxt_D_Rq 1;
BA_ "CrossOver_InfoCAN" SG_ 1069 EngMsgTxt_D_Rq 1;
BA_ "U_P702_MY2021_Tx" SG_ 1069 EngClnt_Te_ActlDiag 1;
BA_ "U_P702_MY2021_Rx" SG_ 1069 EngClnt_Te_ActlDiag 1;
BA_ "ContentDependant" SG_ 1069 EngClnt_Te_ActlDiag 1;
BA_ "CrossOver_InfoCAN" SG_ 1069 EngClnt_Te_ActlDiag 1;
BA_ "U_P702_MY2021_Tx" SG_ 1069 EngLoad_Pc_CalcDiag 1;
BA_ "U_P702_MY2021_Rx" SG_ 1069 EngLoad_Pc_CalcDiag 1;
BA_ "ContentDependant" SG_ 1069 EngLoad_Pc_CalcDiag 1;
BA_ "CrossOver_InfoCAN" SG_ 1069 EngLoad_Pc_CalcDiag 1;
BA_ "U_P702_MY2021_Tx" SG_ 1069 EngAirIn_Te_Actl 1;
BA_ "U_P702_MY2021_Rx" SG_ 1069 EngAirIn_Te_Actl 1;
BA_ "CrossOver_InfoCAN" SG_ 1069 EngAirIn_Te_Actl 1;
BA_ "U_P702_MY2021_Tx" SG_ 1069 ApedPos_Pc_ActlDiag 1;
BA_ "U_P702_MY2021_Rx" SG_ 1069 ApedPos_Pc_ActlDiag 1;
BA_ "ContentDependant" SG_ 1069 ApedPos_Pc_ActlDiag 1;
BA_ "CrossOver_InfoCAN" SG_ 1069 ApedPos_Pc_ActlDiag 1;
BA_ "U_P702_MY2021_Tx" SG_ 1060 RearDiffOilTeWarn_B_Rq 1;
BA_ "U_P702_MY2021_Tx" SG_ 1060 RearDiffOil_Te_Actl 1;
BA_ "GenSigStartValue" SG_ 1060 RearDiffOil_Te_Actl 77;
BA_ "U_P702_MY2021_Tx" SG_ 1060 BpedDrvMsgTxt_B_Dsply 1;
BA_ "U_P702_MY2021_Tx" SG_ 1060 FuelLvl_Pc_DsplyEng 1;
BA_ "GenSigStartValue" SG_ 1060 FuelLvl_Pc_DsplyEng 48;
BA_ "U_P702_MY2021_Tx" SG_ 1060 FuelLvlWarn_D_ActlEng 1;
BA_ "U_P702_MY2021_Tx" SG_ 1060 FuelRange_L_DsplyEng 1;
BA_ "U_P702_MY2021_Tx" SG_ 1060 SelDrvMdePt_D_Stat 1;
BA_ "U_P702_MY2021_Tx" SG_ 1057 FohEng_D_Rq 1;
BA_ "ContentDependant" SG_ 1057 FohEng_D_Rq 1;
BA_ "GenSigStartValue" SG_ 1057 FohEng_D_Rq 2;
BA_ "CrossOver_InfoCAN" SG_ 1057 FohEng_D_Rq 1;
BA_ "U_P702_MY2021_Tx" SG_ 1057 EngIdlShutDwnTxt_D_Rq 1;
BA_ "U_P702_MY2021_Tx" SG_ 1057 EngIdlShutDown_D_Stat 1;
BA_ "ContentDependant" SG_ 1057 EngIdlShutDown_D_Stat 1;
BA_ "CrossOver_InfoCAN" SG_ 1057 EngIdlShutDown_D_Stat 1;
BA_ "U_P702_MY2021_Tx" SG_ 1057 FUEL_ALCOHOL_PERCNT 1;
BA_ "ContentDependant" SG_ 1057 FUEL_ALCOHOL_PERCNT 1;
BA_ "GenSigStartValue" SG_ 1057 FUEL_ALCOHOL_PERCNT 255;
BA_ "CrossOver_InfoCAN" SG_ 1057 FUEL_ALCOHOL_PERCNT 1;
BA_ "U_P702_MY2021_Tx" SG_ 1057 TrnTotTq_Rt_Est 1;
BA_ "ContentDependant" SG_ 1057 TrnTotTq_Rt_Est 1;
BA_ "CrossOver_InfoCAN" SG_ 1057 TrnTotTq_Rt_Est 1;
BA_ "U_P702_MY2021_Tx" SG_ 1057 TrnTotLss_Tq_Est 1;
BA_ "ContentDependant" SG_ 1057 TrnTotLss_Tq_Est 1;
BA_ "CrossOver_InfoCAN" SG_ 1057 TrnTotLss_Tq_Est 1;
BA_ "U_P702_MY2021_Tx" SG_ 1057 ECMMILRequest 1;
BA_ "CrossOver_InfoCAN" SG_ 1057 ECMMILRequest 1;
BA_ "U_P702_MY2021_Tx" SG_ 1057 AirCondFluidHi_P_Actl 1;
BA_ "CrossOver_InfoCAN" SG_ 1057 AirCondFluidHi_P_Actl 1;
BA_ "U_P702_MY2021_Tx" SG_ 1057 OilPressureWarning 1;
BA_ "CrossOver_InfoCAN" SG_ 1057 OilPressureWarning 1;
BA_ "U_P702_MY2021_Tx" SG_ 1057 VehVLimStat_D_Actl 1;
BA_ "U_P702_MY2021_Rx" SG_ 1057 VehVLimStat_D_Actl 1;
BA_ "ContentDependant" SG_ 1057 VehVLimStat_D_Actl 1;
BA_ "CrossOver_InfoCAN" SG_ 1057 VehVLimStat_D_Actl 1;
BA_ "U_P702_MY2021_Tx" SG_ 1057 VehVLimActv_B_Actl 1;
BA_ "U_P702_MY2021_Rx" SG_ 1057 VehVLimActv_B_Actl 1;
BA_ "ContentDependant" SG_ 1057 VehVLimActv_B_Actl 1;
BA_ "CrossOver_InfoCAN" SG_ 1057 VehVLimActv_B_Actl 1;
BA_ "U_P702_MY2021_Tx" SG_ 1057 CoolantFanStepAct 1;
BA_ "CrossOver_InfoCAN" SG_ 1057 CoolantFanStepAct 1;
BA_ "U_P702_MY2021_Tx" SG_ 1055 EcoCochInstNeg_B_Dsply 1;
BA_ "CrossOver_InfoCAN" SG_ 1055 EcoCochInstNeg_B_Dsply 1;
BA_ "U_P702_MY2021_Tx" SG_ 1055 EcoCochShif_Pc_Dsply 1;
BA_ "GenSigStartValue" SG_ 1055 EcoCochShif_Pc_Dsply 255;
BA_ "U_P702_MY2021_Tx" SG_ 1055 EcoCochInst_Pc_Dsply 1;
BA_ "GenSigStartValue" SG_ 1055 EcoCochInst_Pc_Dsply 1000;
BA_ "U_P702_MY2021_Tx" SG_ 1055 EcoCochIdlFuel_Pc_Dsply 1;
BA_ "GenSigStartValue" SG_ 1055 EcoCochIdlFuel_Pc_Dsply 255;
BA_ "U_P702_MY2021_Tx" SG_ 1055 EcoCochDecel_Pc_Dsply 1;
BA_ "GenSigStartValue" SG_ 1055 EcoCochDecel_Pc_Dsply 255;
BA_ "U_P702_MY2021_Tx" SG_ 1055 EcoCochCrus_Pc_Dsply 1;
BA_ "GenSigStartValue" SG_ 1055 EcoCochCrus_Pc_Dsply 255;
BA_ "U_P702_MY2021_Tx" SG_ 1055 EcoCochA_Pc_Dsply 1;
BA_ "GenSigStartValue" SG_ 1055 EcoCochA_Pc_Dsply 255;
BA_ "U_P702_MY2021_Tx" SG_ 562 GearNtrl_No_Cs 1;
BA_ "MetaData" SG_ 562 GearNtrl_No_Cs 1;
BA_ "ContentDependant" SG_ 562 GearNtrl_No_Cs 1;
BA_ "U_P702_MY2021_Tx" SG_ 562 GearNtrl_No_Cnt 1;
BA_ "MetaData" SG_ 562 GearNtrl_No_Cnt 1;
BA_ "ContentDependant" SG_ 562 GearNtrl_No_Cnt 1;
BA_ "U_P702_MY2021_Tx" SG_ 562 GearNtrl_D_Stat 1;
BA_ "GenSigStartValue" SG_ 562 GearNtrl_D_Stat 2;
BA_ "GenSigSendType" SG_ 562 GearNtrl_D_Stat 3;
BA_ "GenSigStartValue" SG_ 523 UreaMxAdd_L2_Actl 510;
BA_ "U_P702_MY2021_Tx" SG_ 523 WaterInFuel_B_Falt 1;
BA_ "CrossOver_InfoCAN" SG_ 523 WaterInFuel_B_Falt 1;
BA_ "U_P702_MY2021_Tx" SG_ 523 UreaMnAdd_L2_Actl 1;
BA_ "U_P702_MY2021_Tx" SG_ 523 VehUreaRnge3_L_DsplyMx 1;
BA_ "U_P702_MY2021_Tx" SG_ 517 FapLc_B_Err 1;
BA_ "U_P702_MY2021_Tx" SG_ 517 BrkTot_Tq_RqFapLc 1;
BA_ "U_P702_MY2021_Rx" SG_ 517 BrkTot_Tq_RqFapLc 1;
BA_ "U_P702_MY2021_Tx" SG_ 516 EngAoutNActl_D_QF 1;
BA_ "U_P702_MY2021_Rx" SG_ 516 EngAoutNActl_D_QF 1;
BA_ "MetaData" SG_ 516 EngAoutNActl_D_QF 1;
BA_ "GenSigStartValue" SG_ 516 EngAoutNActl_D_QF 1;
BA_ "CrossOver_InfoCAN" SG_ 516 EngAoutNActl_D_QF 1;
BA_ "U_P702_MY2021_Tx" SG_ 516 EngAout3_N_Actl 1;
BA_ "ContentDependant" SG_ 516 EngAout3_N_Actl 1;
BA_ "CrossOver_InfoCAN" SG_ 516 EngAout3_N_Actl 1;
BA_ "U_P702_MY2021_Tx" SG_ 516 ApedPos_PcRate_ActlArb 1;
BA_ "U_P702_MY2021_Rx" SG_ 516 ApedPos_PcRate_ActlArb 1;
BA_ "CrossOver_InfoCAN" SG_ 516 ApedPos_PcRate_ActlArb 1;
BA_ "U_P702_MY2021_Tx" SG_ 516 ApedPos_Pc_ActlArb 1;
BA_ "U_P702_MY2021_Rx" SG_ 516 ApedPos_Pc_ActlArb 1;
BA_ "CrossOver_InfoCAN" SG_ 516 ApedPos_Pc_ActlArb 1;
BA_ "U_P702_MY2021_Tx" SG_ 516 ApedPosPcActl_D_Qf 1;
BA_ "U_P702_MY2021_Rx" SG_ 516 ApedPosPcActl_D_Qf 1;
BA_ "MetaData" SG_ 516 ApedPosPcActl_D_Qf 1;
BA_ "GenSigStartValue" SG_ 516 ApedPosPcActl_D_Qf 1;
BA_ "CrossOver_InfoCAN" SG_ 516 ApedPosPcActl_D_Qf 1;
BA_ "U_P702_MY2021_Tx" SG_ 516 EngAout_N_Actl 1;
BA_ "U_P702_MY2021_Rx" SG_ 516 EngAout_N_Actl 1;
BA_ "CrossOver_InfoCAN" SG_ 516 EngAout_N_Actl 1;
BA_ "U_P702_MY2021_Tx" SG_ 516 ApedPosPcActl_No_Cnt 1;
BA_ "MetaData" SG_ 516 ApedPosPcActl_No_Cnt 1;
BA_ "ContentDependant" SG_ 516 ApedPosPcActl_No_Cnt 1;
BA_ "CrossOver_InfoCAN" SG_ 516 ApedPosPcActl_No_Cnt 1;
BA_ "U_P702_MY2021_Tx" SG_ 516 ApedPosPcActl_No_Cs 1;
BA_ "MetaData" SG_ 516 ApedPosPcActl_No_Cs 1;
BA_ "ContentDependant" SG_ 516 ApedPosPcActl_No_Cs 1;
BA_ "CrossOver_InfoCAN" SG_ 516 ApedPosPcActl_No_Cs 1;
BA_ "U_P702_MY2021_Tx" SG_ 514 StrtrMtrCtlMsgTxt_D2_Rq 1;
BA_ "U_P702_MY2021_Tx" SG_ 514 StrtrMtrDlyStrt_B_Stat 1;
BA_ "U_P702_MY2021_Tx" SG_ 514 VehVTrlrAid_B_Avail 1;
BA_ "U_P702_MY2021_Rx" SG_ 514 VehVTrlrAid_B_Avail 1;
BA_ "U_P702_MY2021_Tx" SG_ 514 StrtrMtrCtlMsgTxt_D_Rq 1;
BA_ "CrossOver_InfoCAN" SG_ 514 StrtrMtrCtlMsgTxt_D_Rq 1;
BA_ "U_P702_MY2021_Tx" SG_ 514 VehVActlEng_No_Cs 1;
BA_ "U_P702_MY2021_Rx" SG_ 514 VehVActlEng_No_Cs 1;
BA_ "MetaData" SG_ 514 VehVActlEng_No_Cs 1;
BA_ "CrossOver_InfoCAN" SG_ 514 VehVActlEng_No_Cs 1;
BA_ "U_P702_MY2021_Tx" SG_ 514 VehVActlEng_No_Cnt 1;
BA_ "U_P702_MY2021_Rx" SG_ 514 VehVActlEng_No_Cnt 1;
BA_ "MetaData" SG_ 514 VehVActlEng_No_Cnt 1;
BA_ "CrossOver_InfoCAN" SG_ 514 VehVActlEng_No_Cnt 1;
BA_ "U_P702_MY2021_Tx" SG_ 514 Veh_V_RqCcSet 1;
BA_ "U_P702_MY2021_Rx" SG_ 514 Veh_V_RqCcSet 1;
BA_ "CrossOver_InfoCAN" SG_ 514 Veh_V_RqCcSet 1;
BA_ "U_P702_MY2021_Tx" SG_ 514 VehVActlEng_D_Qf 1;
BA_ "U_P702_MY2021_Rx" SG_ 514 VehVActlEng_D_Qf 1;
BA_ "MetaData" SG_ 514 VehVActlEng_D_Qf 1;
BA_ "CrossOver_InfoCAN" SG_ 514 VehVActlEng_D_Qf 1;
BA_ "U_P702_MY2021_Tx" SG_ 514 Veh_V_ActlEng 1;
BA_ "U_P702_MY2021_Rx" SG_ 514 Veh_V_ActlEng 1;
BA_ "CrossOver_InfoCAN" SG_ 514 Veh_V_ActlEng 1;
BA_ "U_P702_MY2021_Tx" SG_ 514 GearRvrse_D_Actl 1;
BA_ "U_P702_MY2021_Rx" SG_ 514 GearRvrse_D_Actl 1;
BA_ "GenSigStartValue" SG_ 514 GearRvrse_D_Actl 7;
BA_ "CrossOver_InfoCAN" SG_ 514 GearRvrse_D_Actl 1;
BA_ "U_P702_MY2021_Tx" SG_ 512 PrplWhlTotTqRq_No_Cs 1;
BA_ "U_P702_MY2021_Rx" SG_ 512 PrplWhlTotTqRq_No_Cs 1;
BA_ "MetaData" SG_ 512 PrplWhlTotTqRq_No_Cs 1;
BA_ "ContentDependant" SG_ 512 PrplWhlTotTqRq_No_Cs 1;
BA_ "U_P702_MY2021_Tx" SG_ 512 PrplWhlTotTqRq_No_Cnt 1;
BA_ "U_P702_MY2021_Rx" SG_ 512 PrplWhlTotTqRq_No_Cnt 1;
BA_ "MetaData" SG_ 512 PrplWhlTotTqRq_No_Cnt 1;
BA_ "ContentDependant" SG_ 512 PrplWhlTotTqRq_No_Cnt 1;
BA_ "U_P702_MY2021_Tx" SG_ 512 PrplWhlTot_Tq_Rq 1;
BA_ "U_P702_MY2021_Rx" SG_ 512 PrplWhlTot_Tq_Rq 1;
BA_ "U_P702_MY2021_Tx" SG_ 512 PrplWhlTot_Tq_LimMn 1;
BA_ "U_P702_MY2021_Rx" SG_ 512 PrplWhlTot_Tq_LimMn 1;
BA_ "U_P702_MY2021_Tx" SG_ 512 PtDrvMde_D_Stat 1;
BA_ "U_P702_MY2021_Tx" SG_ 381 EngOilLife_T_Actl 1;
BA_ "U_P702_MY2021_Tx" SG_ 381 EngOilSrvcMsgTxt_D_Rq 1;
BA_ "U_P702_MY2021_Tx" SG_ 381 DistToNextOilChange 1;
BA_ "U_P702_MY2021_Tx" SG_ 381 RunDryPrevent_B_Stat 1;
BA_ "U_P702_MY2021_Tx" SG_ 381 WaterInFuel 1;
BA_ "CrossOver_InfoCAN" SG_ 381 WaterInFuel 1;
BA_ "U_P702_MY2021_Tx" SG_ 381 GlowIndication 1;
BA_ "CrossOver_InfoCAN" SG_ 381 GlowIndication 1;
BA_ "U_P702_MY2021_Tx" SG_ 380 EngOilLvlWarn_D_Rq1 1;
BA_ "CrossOver_InfoCAN" SG_ 380 EngOilLvlWarn_D_Rq1 1;
BA_ "WakeupSignal" SG_ 380 EngOilLvlWarn_D_Rq1 1;
BA_ "U_P702_MY2021_Tx" SG_ 380 EngExhBrkOnLamp_B_Rq 1;
BA_ "CrossOver_InfoCAN" SG_ 380 EngExhBrkOnLamp_B_Rq 1;
BA_ "U_P702_MY2021_Tx" SG_ 380 EngExhBrkAutoLamp_B_Rq 1;
BA_ "CrossOver_InfoCAN" SG_ 380 EngExhBrkAutoLamp_B_Rq 1;
BA_ "U_P702_MY2021_Tx" SG_ 380 EngAout_N_MxAllw 1;
BA_ "CrossOver_InfoCAN" SG_ 380 EngAout_N_MxAllw 1;
BA_ "U_P702_MY2021_Tx" SG_ 380 EngExhBrkMde_D_Actl 1;
BA_ "U_P702_MY2021_Rx" SG_ 380 EngExhBrkMde_D_Actl 1;
BA_ "CrossOver_InfoCAN" SG_ 380 EngExhBrkMde_D_Actl 1;
BA_ "U_P702_MY2021_Tx" SG_ 377 HvacAirFullOut_B_Rq 1;
BA_ "U_P702_MY2021_Tx" SG_ 377 TrnManShif_D_IndDrv 1;
BA_ "CrossOver_InfoCAN" SG_ 377 TrnManShif_D_IndDrv 1;
BA_ "U_P702_MY2021_Tx" SG_ 377 TrnManShifGear_D_IndDrv 1;
BA_ "CrossOver_InfoCAN" SG_ 377 TrnManShifGear_D_IndDrv 1;
BA_ "U_P702_MY2021_Tx" SG_ 377 FuelFlw_Vl_Dsply 1;
BA_ "ContentDependant" SG_ 377 FuelFlw_Vl_Dsply 1;
BA_ "CrossOver_InfoCAN" SG_ 377 FuelFlw_Vl_Dsply 1;
BA_ "U_P702_MY2021_Tx" SG_ 377 FuelFillInlet_B_Dsply 1;
BA_ "ContentDependant" SG_ 377 FuelFillInlet_B_Dsply 1;
BA_ "CrossOver_InfoCAN" SG_ 377 FuelFillInlet_B_Dsply 1;
BA_ "U_P702_MY2021_Tx" SG_ 377 EngSrvcRqd_B_Rq 1;
BA_ "CrossOver_InfoCAN" SG_ 377 EngSrvcRqd_B_Rq 1;
BA_ "U_P702_MY2021_Tx" SG_ 377 OdoCount 1;
BA_ "ContentDependant" SG_ 377 OdoCount 1;
BA_ "CrossOver_InfoCAN" SG_ 377 OdoCount 1;
BA_ "U_P702_MY2021_Tx" SG_ 377 EngOilLife_Pc_Actl 1;
BA_ "ContentDependant" SG_ 377 EngOilLife_Pc_Actl 1;
BA_ "CrossOver_InfoCAN" SG_ 377 EngOilLife_Pc_Actl 1;
BA_ "U_P702_MY2021_Tx" SG_ 377 TrnKickDown_B_RqDrv 1;
BA_ "ContentDependant" SG_ 377 TrnKickDown_B_RqDrv 1;
BA_ "CrossOver_InfoCAN" SG_ 377 TrnKickDown_B_RqDrv 1;
BA_ "U_P702_MY2021_Tx" SG_ 377 FuelFilterLamp_B_Dsply 1;
BA_ "CrossOver_InfoCAN" SG_ 377 FuelFilterLamp_B_Dsply 1;
BA_ "U_P702_MY2021_Tx" SG_ 377 AirCondRec_B_Rq 1;
BA_ "ContentDependant" SG_ 377 AirCondRec_B_Rq 1;
BA_ "CrossOver_InfoCAN" SG_ 377 AirCondRec_B_Rq 1;
BA_ "U_P702_MY2021_Tx" SG_ 377 AirCondClutch_B_Stats 1;
BA_ "ContentDependant" SG_ 377 AirCondClutch_B_Stats 1;
BA_ "CrossOver_InfoCAN" SG_ 377 AirCondClutch_B_Stats 1;
BA_ "U_P702_MY2021_Tx" SG_ 376 AslChime_B_Rq 1;
BA_ "U_P702_MY2021_Tx" SG_ 376 AslIconDsply_D_Rq 1;
BA_ "U_P702_MY2021_Tx" SG_ 376 GasPrtc_D_RqDsply 1;
BA_ "U_P702_MY2021_Tx" SG_ 376 EngAout_Aa_Actl 1;
BA_ "U_P702_MY2021_Rx" SG_ 376 EngAout_Aa_Actl 1;
BA_ "ContentDependant" SG_ 376 EngAout_Aa_Actl 1;
BA_ "CrossOver_InfoCAN" SG_ 376 EngAout_Aa_Actl 1;
BA_ "U_P702_MY2021_Tx" SG_ 376 DynoMde_B_Cmd 1;
BA_ "U_P702_MY2021_Rx" SG_ 376 DynoMde_B_Cmd 1;
BA_ "U_P702_MY2021_Tx" SG_ 376 HvacHtrCore2_Te_Actl 1;
BA_ "GenSigStartValue" SG_ 376 HvacHtrCore2_Te_Actl 200;
BA_ "U_P702_MY2021_Tx" SG_ 376 EcssLamp_D_RqDsply 1;
BA_ "U_P702_MY2021_Tx" SG_ 376 AirAmbTe_D_Qf 1;
BA_ "U_P702_MY2021_Rx" SG_ 376 AirAmbTe_D_Qf 1;
BA_ "MetaData" SG_ 376 AirAmbTe_D_Qf 1;
BA_ "GenSigStartValue" SG_ 376 AirAmbTe_D_Qf 1;
BA_ "CrossOver_InfoCAN" SG_ 376 AirAmbTe_D_Qf 1;
BA_ "U_P702_MY2021_Tx" SG_ 376 AirAmb_Te_ActlFilt 1;
BA_ "GenSigStartValue" SG_ 376 AirAmb_Te_ActlFilt 512;
BA_ "CrossOver_InfoCAN" SG_ 376 AirAmb_Te_ActlFilt 1;
BA_ "U_P702_MY2021_Tx" SG_ 376 AirAmb_Te_Actl 1;
BA_ "U_P702_MY2021_Rx" SG_ 376 AirAmb_Te_Actl 1;
BA_ "GenSigStartValue" SG_ 376 AirAmb_Te_Actl 512;
BA_ "CrossOver_InfoCAN" SG_ 376 AirAmb_Te_Actl 1;
BA_ "U_P702_MY2021_Tx" SG_ 376 AirAmb_P_Actl 1;
BA_ "U_P702_MY2021_Rx" SG_ 376 AirAmb_P_Actl 1;
BA_ "CrossOver_InfoCAN" SG_ 376 AirAmb_P_Actl 1;
BA_ "U_P702_MY2021_Tx" SG_ 373 DieslPrtc2_D_RqDsply 1;
BA_ "U_P702_MY2021_Tx" SG_ 373 DieslPrtcRgen_D_Actl 1;
BA_ "U_P702_MY2021_Rx" SG_ 373 DieslPrtcRgen_D_Actl 1;
BA_ "CrossOver_InfoCAN" SG_ 373 DieslPrtcRgen_D_Actl 1;
BA_ "U_P702_MY2021_Tx" SG_ 373 EngTeColdPrtct_D_Stats 1;
BA_ "CrossOver_InfoCAN" SG_ 373 EngTeColdPrtct_D_Stats 1;
BA_ "U_P702_MY2021_Tx" SG_ 373 EngExhOvrTe_B_RqDsply 1;
BA_ "CrossOver_InfoCAN" SG_ 373 EngExhOvrTe_B_RqDsply 1;
BA_ "U_P702_MY2021_Tx" SG_ 373 EngAout_N_RqMnPrtct 1;
BA_ "CrossOver_InfoCAN" SG_ 373 EngAout_N_RqMnPrtct 1;
BA_ "U_P702_MY2021_Tx" SG_ 373 EngAout_N_RqMxPrtct 1;
BA_ "CrossOver_InfoCAN" SG_ 373 EngAout_N_RqMxPrtct 1;
BA_ "U_P702_MY2021_Tx" SG_ 359 PrplWhlRgenMn_Tq_Actl 1;
BA_ "U_P702_MY2021_Rx" SG_ 359 PrplWhlRgenMn_Tq_Actl 1;
BA_ "GenSigStartValue" SG_ 359 PrplWhlRgenMn_Tq_Actl 4095;
BA_ "U_P702_MY2021_Tx" SG_ 359 ElPw_D_StatStrtStop 1;
BA_ "U_P702_MY2021_Rx" SG_ 359 ElPw_D_StatStrtStop 1;
BA_ "CrossOver_InfoCAN" SG_ 359 ElPw_D_StatStrtStop 1;
BA_ "U_P702_MY2021_Tx" SG_ 359 TrnAin_Tq_Actl 1;
BA_ "U_P702_MY2021_Rx" SG_ 359 TrnAin_Tq_Actl 1;
BA_ "ContentDependant" SG_ 359 TrnAin_Tq_Actl 1;
BA_ "CrossOver_InfoCAN" SG_ 359 TrnAin_Tq_Actl 1;
BA_ "U_P702_MY2021_Tx" SG_ 359 PrplWhlTot2_Tq_Actl 1;
BA_ "U_P702_MY2021_Rx" SG_ 359 PrplWhlTot2_Tq_Actl 1;
BA_ "CrossOver_InfoCAN" SG_ 359 PrplWhlTot2_Tq_Actl 1;
BA_ "U_P702_MY2021_Tx" SG_ 359 PwPckTq_D_Stat 1;
BA_ "U_P702_MY2021_Rx" SG_ 359 PwPckTq_D_Stat 1;
BA_ "CrossOver_InfoCAN" SG_ 359 PwPckTq_D_Stat 1;
BA_ "U_P702_MY2021_Tx" SG_ 359 Eng_D_Stat 1;
BA_ "U_P702_MY2021_Rx" SG_ 359 Eng_D_Stat 1;
BA_ "CrossOver_InfoCAN" SG_ 359 Eng_D_Stat 1;
BA_ "U_P702_MY2021_Tx" SG_ 359 ElPw_D_Stat 1;
BA_ "U_P702_MY2021_Rx" SG_ 359 ElPw_D_Stat 1;
BA_ "CrossOver_InfoCAN" SG_ 359 ElPw_D_Stat 1;
BA_ "U_P702_MY2021_Tx" SG_ 359 TrnAinTq_D_Qf 1;
BA_ "U_P702_MY2021_Rx" SG_ 359 TrnAinTq_D_Qf 1;
BA_ "MetaData" SG_ 359 TrnAinTq_D_Qf 1;
BA_ "ContentDependant" SG_ 359 TrnAinTq_D_Qf 1;
BA_ "CrossOver_InfoCAN" SG_ 359 TrnAinTq_D_Qf 1;
BA_ "U_P702_MY2021_Tx" SG_ 358 AutoStopPtDelta_I_Est 1;
BA_ "ContentDependant" SG_ 358 AutoStopPtDelta_I_Est 1;
BA_ "GenSigStartValue" SG_ 358 AutoStopPtDelta_I_Est 127;
BA_ "CrossOver_InfoCAN" SG_ 358 AutoStopPtDelta_I_Est 1;
BA_ "U_P702_MY2021_Tx" SG_ 358 StopStrtStdby_D_Indic 1;
BA_ "CrossOver_InfoCAN" SG_ 358 StopStrtStdby_D_Indic 1;
BA_ "U_P702_MY2021_Tx" SG_ 358 StopStrtIODTxt_D_Rq 1;
BA_ "CrossOver_InfoCAN" SG_ 358 StopStrtIODTxt_D_Rq 1;
BA_ "U_P702_MY2021_Tx" SG_ 358 StopStrtDrvMde_D_Indic 1;
BA_ "CrossOver_InfoCAN" SG_ 358 StopStrtDrvMde_D_Indic 1;
BA_ "U_P702_MY2021_Tx" SG_ 358 StopStrtMsgTxt_D_Rq 1;
BA_ "CrossOver_InfoCAN" SG_ 358 StopStrtMsgTxt_D_Rq 1;
BA_ "U_P702_MY2021_Tx" SG_ 358 OdoTripVerify_L_Actl 1;
BA_ "CrossOver_InfoCAN" SG_ 358 OdoTripVerify_L_Actl 1;
BA_ "U_P702_MY2021_Tx" SG_ 358 HiElPwInhbt_B_Stat 1;
BA_ "ContentDependant" SG_ 358 HiElPwInhbt_B_Stat 1;
BA_ "CrossOver_InfoCAN" SG_ 358 HiElPwInhbt_B_Stat 1;
BA_ "U_P702_MY2021_Tx" SG_ 357 BPedDrvAppl_D_QF 1;
BA_ "U_P702_MY2021_Rx" SG_ 357 BPedDrvAppl_D_QF 1;
BA_ "MetaData" SG_ 357 BPedDrvAppl_D_QF 1;
BA_ "GenSigStartValue" SG_ 357 BPedDrvAppl_D_QF 1;
BA_ "U_P702_MY2021_Tx" SG_ 357 CmbbDeny_B_ActlPrpl 1;
BA_ "U_P702_MY2021_Tx" SG_ 357 PrplTqMnSat_B_Actl 1;
BA_ "U_P702_MY2021_Tx" SG_ 357 BpedDrvAppl_D_Actl 1;
BA_ "U_P702_MY2021_Rx" SG_ 357 BpedDrvAppl_D_Actl 1;
BA_ "GenSigStartValue" SG_ 357 BpedDrvAppl_D_Actl 1;
BA_ "CrossOver_InfoCAN" SG_ 357 BpedDrvAppl_D_Actl 1;
BA_ "U_P702_MY2021_Tx" SG_ 357 CmbbEngTqMn_B_Actl 1;
BA_ "U_P702_MY2021_Tx" SG_ 357 Veh_V_DsplyCcSet 1;
BA_ "CrossOver_InfoCAN" SG_ 357 Veh_V_DsplyCcSet 1;
BA_ "U_P702_MY2021_Tx" SG_ 357 AccEngStat_D_Actl 1;
BA_ "U_P702_MY2021_Tx" SG_ 357 CcMde_D_Actl 1;
BA_ "U_P702_MY2021_Rx" SG_ 357 CcMde_D_Actl 1;
BA_ "U_P702_MY2021_Tx" SG_ 357 CcStat_D_Actl 1;
BA_ "U_P702_MY2021_Rx" SG_ 357 CcStat_D_Actl 1;
BA_ "CrossOver_InfoCAN" SG_ 357 CcStat_D_Actl 1;
BA_ "U_P702_MY2021_Tx" SG_ 357 EngAout_N_MnAllw 1;
BA_ "U_P702_MY2021_Tx" SG_ 357 CcOvrrdActv_B_Actl 1;
BA_ "U_P702_MY2021_Rx" SG_ 357 CcOvrrdActv_B_Actl 1;
BA_ "CrossOver_InfoCAN" SG_ 357 CcOvrrdActv_B_Actl 1;
BA_ "U_P702_MY2021_Tx" SG_ 357 AccStopMde_D_Rq 1;
BA_ "U_P702_MY2021_Rx" SG_ 357 AccStopMde_D_Rq 1;
BA_ "U_P702_MY2021_Tx" SG_ 355 AutoRgenTxt_B_RqDsply 1;
BA_ "U_P702_MY2021_Tx" SG_ 355 AccFllwMdeActv_B_Actl 1;
BA_ "CrossOver_InfoCAN" SG_ 355 AccFllwMdeActv_B_Actl 1;
BA_ "U_P702_MY2021_Tx" SG_ 355 EngPtoMde_D_Actl 1;
BA_ "CrossOver_InfoCAN" SG_ 355 EngPtoMde_D_Actl 1;
BA_ "U_P702_MY2021_Tx" SG_ 355 ManRgenTxt_D_RqDsply 1;
BA_ "CrossOver_InfoCAN" SG_ 355 ManRgenTxt_D_RqDsply 1;
BA_ "U_P702_MY2021_Tx" SG_ 355 ManRgenSoot_Pc_RqDsply 1;
BA_ "CrossOver_InfoCAN" SG_ 355 ManRgenSoot_Pc_RqDsply 1;
BA_ "U_P702_MY2021_Tx" SG_ 355 DieslMsgTxt_D_Rq 1;
BA_ "U_P702_MY2021_Tx" SG_ 342 EngOvrhtMitgActv_D_Ind 1;
BA_ "ContentDependant" SG_ 342 EngOvrhtMitgActv_D_Ind 1;
BA_ "CrossOver_InfoCAN" SG_ 342 EngOvrhtMitgActv_D_Ind 1;
BA_ "U_P702_MY2021_Tx" SG_ 342 EngClntTe_D_Qf 1;
BA_ "U_P702_MY2021_Rx" SG_ 342 EngClntTe_D_Qf 1;
BA_ "MetaData" SG_ 342 EngClntTe_D_Qf 1;
BA_ "CrossOver_InfoCAN" SG_ 342 EngClntTe_D_Qf 1;
BA_ "U_P702_MY2021_Tx" SG_ 342 EngGoutLss_Tq_Est 1;
BA_ "ContentDependant" SG_ 342 EngGoutLss_Tq_Est 1;
BA_ "CrossOver_InfoCAN" SG_ 342 EngGoutLss_Tq_Est 1;
BA_ "U_P702_MY2021_Tx" SG_ 342 EngOil_Te_Actl 1;
BA_ "CrossOver_InfoCAN" SG_ 342 EngOil_Te_Actl 1;
BA_ "U_P702_MY2021_Tx" SG_ 342 EngClnt_Te_Actl 1;
BA_ "U_P702_MY2021_Rx" SG_ 342 EngClnt_Te_Actl 1;
BA_ "CrossOver_InfoCAN" SG_ 342 EngClnt_Te_Actl 1;
BA_ "U_P702_MY2021_Tx" SG_ 71 immoTarget1Status 1;
BA_ "U_P702_MY2021_Rx" SG_ 71 immoTarget1Status 1;
BA_ "U_P702_MY2021_Tx" SG_ 71 immoTarget1Data 1;
BA_ "U_P702_MY2021_Rx" SG_ 71 immoTarget1Data 1;
BA_ "U_P702_MY2021_Tx" SG_ 71 immoTarget1Cmd 1;
BA_ "U_P702_MY2021_Rx" SG_ 71 immoTarget1Cmd 1;
BA_ "U_P702_MY2021_Rx" SG_ 137 SteWhlOffstRq_D_Stat 1;
BA_ "GenSigStartValue" SG_ 137 SteWhlOffstRq_D_Stat 2;
BA_ "U_P702_MY2021_Rx" SG_ 137 SteWhlOffst_An_TotActl 1;
BA_ "GenSigStartValue" SG_ 137 SteWhlOffst_An_TotActl 32766;
BA_ "U_P702_MY2021_Rx" SG_ 137 SteWhlBrkOffst_An_Actl 1;
BA_ "GenSigStartValue" SG_ 137 SteWhlBrkOffst_An_Actl 32766;
BA_ "U_P702_MY2021_Rx" SG_ 137 SteWhlBrkAnActl_No_Cs 1;
BA_ "MetaData" SG_ 137 SteWhlBrkAnActl_No_Cs 1;
BA_ "CrossOver_InfoCAN" SG_ 137 SteWhlBrkAnActl_No_Cs 1;
BA_ "U_P702_MY2021_Rx" SG_ 137 SteWhlBrkAnActl_No_Cnt 1;
BA_ "MetaData" SG_ 137 SteWhlBrkAnActl_No_Cnt 1;
BA_ "CrossOver_InfoCAN" SG_ 137 SteWhlBrkAnActl_No_Cnt 1;
BA_ "U_P702_MY2021_Rx" SG_ 129 SelDrvMdeSwtch_D_Stat4 1;
BA_ "WakeupSignal" SG_ 129 SteWhlSwtchView_B_Stat 1;
BA_ "WakeupSignal" SG_ 129 SteWhlSwtchSet_B_Stat 1;
BA_ "WakeupSignal" SG_ 129 SteWhlSwtchPhon_B_Stat 1;
BA_ "WakeupSignal" SG_ 129 SteWhlSwtchNav_B_Stat 1;
BA_ "WakeupSignal" SG_ 129 SteWhlSwtchMed_B_Stat 1;
BA_ "WakeupSignal" SG_ 129 SteWhlSwtchIod_B_Stat 1;
BA_ "WakeupSignal" SG_ 129 SteWhlSwtchHud_B_Stat 1;
BA_ "WakeupSignal" SG_ 129 SteWhlSwtchBack_B_Stat 1;
BA_ "WakeupSignal" SG_ 129 SteWhlSwtchMenu_B_Stat 1;
BA_ "WakeupSignal" SG_ 129 SteWhlSwtchUp_B_Stat 1;
BA_ "WakeupSignal" SG_ 129 SteWhlSwtchRght_B_Stat 1;
BA_ "WakeupSignal" SG_ 129 SteWhlSwtchOk_B_Stat 1;
BA_ "WakeupSignal" SG_ 129 SteWhlSwtchLeft_B_Stat 1;
BA_ "WakeupSignal" SG_ 129 SteWhlSwtchDown_B_Stat 1;
BA_ "GenSigSendType" SG_ 935 LcwaDetctRight2_B_Stat 3;
BA_ "CrossOver_InfoCAN" SG_ 935 RbaCtaRight_D_Stat 1;
BA_ "GenSigSendType" SG_ 935 RbaCtaRight_D_Stat 3;
BA_ "GenSigSendType" SG_ 935 CtaAlrtRight2_D_Stat 3;
BA_ "GenSigSendType" SG_ 935 BttRight_D_Stat 3;
BA_ "GenSigSendType" SG_ 935 BttRight_D_RqDrv 3;
BA_ "GenSigSendType" SG_ 935 CtaBrkRightMsgTxt_B_Rq 3;
BA_ "U_P702_MY2021_Rx" SG_ 935 CtaRightBrkEnbl_B_Rq 1;
BA_ "GenSigSendType" SG_ 935 CtaRightBrkEnbl_B_Rq 3;
BA_ "U_P702_MY2021_Rx" SG_ 935 CtaRightBrkDecel_B_Rq 1;
BA_ "GenSigSendType" SG_ 935 CtaRightBrkDecel_B_Rq 3;
BA_ "GenSigStartValue" SG_ 935 Side_Detect_R_Illum 100;
BA_ "CrossOver_InfoCAN" SG_ 935 Side_Detect_R_Illum 1;
BA_ "CrossOver_InfoCAN" SG_ 935 CtaSnsRight_D_Stat 1;
BA_ "GenSigSendType" SG_ 935 CtaSnsRight_D_Stat 3;
BA_ "CrossOver_InfoCAN" SG_ 935 CtaAlrtRight_D_Stat 1;
BA_ "GenSigSendType" SG_ 935 CtaAlrtRight_D_Stat 3;
BA_ "CrossOver_InfoCAN" SG_ 935 CtaRight_D_Stat 1;
BA_ "GenSigSendType" SG_ 935 CtaRight_D_Stat 3;
BA_ "GenSigStartValue" SG_ 935 SodRight_D_Stat 2;
BA_ "CrossOver_InfoCAN" SG_ 935 SodRight_D_Stat 1;
BA_ "GenSigSendType" SG_ 935 SodRight_D_Stat 3;
BA_ "CrossOver_InfoCAN" SG_ 935 SodSnsRight_D_Stat 1;
BA_ "GenSigSendType" SG_ 935 SodSnsRight_D_Stat 3;
BA_ "CrossOver_InfoCAN" SG_ 935 SodAlrtRight_D_Stat 1;
BA_ "GenSigSendType" SG_ 935 SodAlrtRight_D_Stat 3;
BA_ "CrossOver_InfoCAN" SG_ 935 SodDetctRight_D_Stat 1;
BA_ "GenSigSendType" SG_ 935 SodDetctRight_D_Stat 3;
BA_ "GenSigStartValue" SG_ 935 SodWarnRight_Prd_Rq 14;
BA_ "CrossOver_InfoCAN" SG_ 935 SodWarnRight_Prd_Rq 1;
BA_ "CrossOver_InfoCAN" SG_ 935 SodInnrRight_D_Stat 1;
BA_ "GenSigSendType" SG_ 935 SodInnrRight_D_Stat 3;
BA_ "CrossOver_InfoCAN" SG_ 935 CtaInnrRight_D_Stat 1;
BA_ "GenSigSendType" SG_ 935 CtaInnrRight_D_Stat 3;
BA_ "GenSigSendType" SG_ 935 LcwaDetctRight1_B_Stat 3;
BA_ "U_P702_MY2021_Rx" SG_ 1108 RCMSerialNoByte8 1;
BA_ "U_P702_MY2021_Rx" SG_ 1108 RCMSerialNoByte7 1;
BA_ "U_P702_MY2021_Rx" SG_ 1108 RCMSerialNoByte6 1;
BA_ "U_P702_MY2021_Rx" SG_ 1108 RCMSerialNoByte5 1;
BA_ "U_P702_MY2021_Rx" SG_ 1108 RCMSerialNoByte4 1;
BA_ "U_P702_MY2021_Rx" SG_ 1108 RCMSerialNoByte3 1;
BA_ "U_P702_MY2021_Rx" SG_ 1108 RCMSerialNoByte2 1;
BA_ "U_P702_MY2021_Rx" SG_ 1108 RCMSerialNoByte1 1;
BA_ "U_P702_MY2021_Rx" SG_ 1146 TrlrAidSwtch_D_RqDrv 1;
BA_ "U_P702_MY2021_Rx" SG_ 1146 TrlrAidCtl_U_RqDrv 1;
BA_ "GenSigStartValue" SG_ 1146 TrlrAidCtl_U_RqDrv 4094;
BA_ "GenSigStartValue" SG_ 1146 TrlrAidAn_URate_Actl 4094;
BA_ "GenSigStartValue" SG_ 1146 TrlrAidAn_U_Actl 4094;
BA_ "U_P702_MY2021_Rx" SG_ 533 TrlrAidMde_D_Rq 1;
BA_ "GenSigStartValue" SG_ 533 OnbChrgGoTOn_D_Rq 2;
BA_ "CrossOver_InfoCAN" SG_ 533 OnbChrgGoTOn_D_Rq 1;
BA_ "MetaData" SG_ 533 OnbChrgGoTMnte_D_Rq 1;
BA_ "CrossOver_InfoCAN" SG_ 533 OnbChrgGoTMnte_D_Rq 1;
BA_ "GenSigStartValue" SG_ 533 OnbChrgGoTHr_T_Rq 30;
BA_ "MetaData" SG_ 533 OnbChrgGoTElement_D_Rq 1;
BA_ "CrossOver_InfoCAN" SG_ 533 OnbChrgGoTElement_D_Rq 1;
BA_ "CrossOver_InfoCAN" SG_ 533 OnbChrgGoTDelete_B_Rq 1;
BA_ "CrossOver_InfoCAN" SG_ 533 OnbChrgClearAll_B_Rq 1;
BA_ "CrossOver_InfoCAN" SG_ 533 OnbChrgGoTUpdate_B_Rq 1;
BA_ "U_P702_MY2021_Rx" SG_ 1041 ElCmpr_Pw_Actl 1;
BA_ "U_P702_MY2021_Rx" SG_ 1067 BattULoAuxSoc_Pc_Actl 1;
BA_ "GenSigStartValue" SG_ 1067 BattULoAuxSoc_Pc_Actl 95;
BA_ "U_P702_MY2021_Rx" SG_ 1067 BattULoAux_I_Actl 1;
BA_ "GenSigStartValue" SG_ 1067 BattULoAux_I_Actl 2048;
BA_ "U_P702_MY2021_Rx" SG_ 1067 BattULoAux_D_Qlty 1;
BA_ "U_P702_MY2021_Rx" SG_ 1067 BattULoCrnkStrt_U_Pred 1;
BA_ "U_P702_MY2021_Rx" SG_ 1067 BattULoCrnkBelt_U_Pred 1;
BA_ "U_P702_MY2021_Rx" SG_ 1067 BattULoAux_U_Actl 1;
BA_ "GenSigStartValue" SG_ 1067 BattULoAux_U_Actl 203;
BA_ "U_P702_MY2021_Rx" SG_ 1067 BattULoAux_B_Falt 1;
BA_ "U_P702_MY2021_Rx" SG_ 1040 ElCmprEnbl_B_Rq 1;
BA_ "WakeupSignal" SG_ 1144 CabnEvapSovFront_B_Rq 1;
BA_ "WakeupSignal" SG_ 1144 HeatCoreSovRear_B_Rq 1;
BA_ "WakeupSignal" SG_ 1144 BattChlrSov_B_Rq 1;
BA_ "WakeupSignal" SG_ 1144 CabnEvapSovRear_B_Rq 1;
BA_ "U_P702_MY2021_Rx" SG_ 1144 PtcHtr_D_Stat 1;
BA_ "GenSigStartValue" SG_ 1144 WakeAlarm0_T_Rq 32767;
BA_ "U_P702_MY2021_Rx" SG_ 1144 PreCondBatt_B_Actl 1;
BA_ "U_P702_MY2021_Rx" SG_ 1112 BattTracCnnct_D_Cmd 1;
BA_ "U_P702_MY2021_Rx" SG_ 1112 BattTracHvilOpen_B_Stat 1;
BA_ "U_P702_MY2021_Rx" SG_ 1112 CoolFanBatt_D_Rq 1;
BA_ "U_P702_MY2021_Rx" SG_ 1112 BattTracDcdcDis_B_Rq 1;
BA_ "U_P702_MY2021_Rx" SG_ 139 ActvFrontSteLck_D_Stat 1;
BA_ "U_P702_MY2021_Rx" SG_ 139 SelDrvMdeAdptSte_D_Stat 1;
BA_ "U_P702_MY2021_Rx" SG_ 1121 AutoHoldSwtch_D_Stat2 1;
BA_ "U_P702_MY2021_Rx" SG_ 1121 SelDrvMdeSwtch_No_Actl 1;
BA_ "U_P702_MY2021_Rx" SG_ 1121 SelDrvMdeSwtch_D_Stat 1;
BA_ "U_P702_MY2021_Rx" SG_ 1121 SelDrvMdeCnt_D_Stat 1;
BA_ "U_P702_MY2021_Rx" SG_ 1120 DrvSlipCtlMde_B_Rq3 1;
BA_ "CrossOver_InfoCAN" SG_ 1120 DrvSlipCtlMde_B_Rq3 1;
BA_ "GenSigStartValue" SG_ 1120 AwdLck_D_RqDrv 2;
BA_ "U_P702_MY2021_Rx" SG_ 1120 RearDiffLck_D_RqDrv 1;
BA_ "GenSigStartValue" SG_ 1120 RearDiffLck_D_RqDrv 2;
BA_ "U_P702_MY2021_Rx" SG_ 1120 AwdMde_D_RqDrv 1;
BA_ "GenSigStartValue" SG_ 1120 AwdMde_D_RqDrv 5;
BA_ "U_P702_MY2021_Rx" SG_ 1120 HdcSwtchPos_B_Actl 1;
BA_ "WakeupSignal" SG_ 1050 GlvBoxRleas_No_Actl 1;
BA_ "CrossOver_InfoCAN" SG_ 1050 EcoInhbt_B_RqHvac 1;
BA_ "CrossOver_InfoCAN" SG_ 1050 DrvSlipCtlMde_B_Rq 1;
BA_ "U_P702_MY2021_Rx" SG_ 1050 Outside_Air_Temp_Stat 1;
BA_ "GenSigStartValue" SG_ 1050 Outside_Air_Temp_Stat 254;
BA_ "CrossOver_InfoCAN" SG_ 1050 Outside_Air_Temp_Stat 1;
BA_ "GenSigSendType" SG_ 942 PrkAidDrvDir_D_Stat 3;
BA_ "U_P702_MY2021_Rx" SG_ 1113 TrlrTrgtAcquire_D_Stat 1;
BA_ "U_P702_MY2021_Rx" SG_ 1113 TrlrRvrse_D_Stat 1;
BA_ "U_P702_MY2021_Rx" SG_ 1113 TrlrAid_D2_Stat 1;
BA_ "U_P702_MY2021_Rx" SG_ 1113 TrlrAidTrgtId_No_Actl 1;
BA_ "U_P702_MY2021_Rx" SG_ 1113 TrlrAid_An3_Actl 1;
BA_ "GenSigStartValue" SG_ 1113 TrlrAid_An3_Actl 720;
BA_ "U_P702_MY2021_Rx" SG_ 1113 TrlrAid_AnRate2_Actl 1;
BA_ "GenSigStartValue" SG_ 1113 TrlrAid_AnRate2_Actl 400;
BA_ "U_P702_MY2021_Rx" SG_ 1113 HitchToVehAxle_L_Calc 1;
BA_ "GenSigStartValue" SG_ 1113 HitchToVehAxle_L_Calc 255;
BA_ "U_P702_MY2021_Rx" SG_ 1105 TrlrRvrseMsgTxt_D2_Rq 1;
BA_ "GenSigSendType" SG_ 1105 TrlrRvrseMsgTxt_D2_Rq 3;
BA_ "U_P702_MY2021_Rx" SG_ 1105 TrlrRvrseEnbl_D2_Stat 1;
BA_ "GenSigSendType" SG_ 1105 TrlrRvrseEnbl_D2_Stat 3;
BA_ "GenSigSendType" SG_ 1105 RbaMsg_D_Rq 3;
BA_ "U_P702_MY2021_Rx" SG_ 1105 BrkDecel_B_RqRba 1;
BA_ "CrossOver_InfoCAN" SG_ 1105 BrkDecel_B_RqRba 1;
BA_ "WakeupSignal" SG_ 1105 BrkDecel_B_RqRba 1;
BA_ "GenSigSendType" SG_ 1105 BrkDecel_B_RqRba 3;
BA_ "U_P702_MY2021_Rx" SG_ 1105 BrkEnbl_B_RqRba 1;
BA_ "CrossOver_InfoCAN" SG_ 1105 BrkEnbl_B_RqRba 1;
BA_ "WakeupSignal" SG_ 1105 BrkEnbl_B_RqRba 1;
BA_ "GenSigSendType" SG_ 1105 BrkEnbl_B_RqRba 3;
BA_ "GenSigStartValue" SG_ 1105 Rba_D_Stat 1;
BA_ "GenSigSendType" SG_ 1105 Rba_D_Stat 3;
BA_ "GenSigSendType" SG_ 1105 RbaAlrt_D_Dsply 3;
BA_ "GenSigSendType" SG_ 1105 RbaMnu_D_Rq 3;
BA_ "U_P702_MY2021_Rx" SG_ 1105 RbaSys_D_Stat 1;
BA_ "GenSigStartValue" SG_ 1105 RbaSys_D_Stat 2;
BA_ "GenSigSendType" SG_ 1105 RbaSys_D_Stat 3;
BA_ "GenSigSendType" SG_ 1105 CamraRemoteStat_B_Actl 3;
BA_ "GenSigSendType" SG_ 1105 CamraFrntStat_D_Stat 3;
BA_ "GenSigSendType" SG_ 1105 TrlrHitchLamp_D_Rq2 3;
BA_ "GenSigStartValue" SG_ 1105 TrlrRvrseMsgTxt_D_Rq 1;
BA_ "GenSigSendType" SG_ 1105 TrlrRvrseMsgTxt_D_Rq 3;
BA_ "GenSigSendType" SG_ 938 SidePrkSnsR2_D_Stat 3;
BA_ "GenSigSendType" SG_ 938 SidePrkSnsR1_D_Stat 3;
BA_ "GenSigSendType" SG_ 938 SidePrkSnsL2_D_Stat 3;
BA_ "CrossOver_InfoCAN" SG_ 938 ApaMde_D_Stat 1;
BA_ "GenSigSendType" SG_ 938 ApaMde_D_Stat 3;
BA_ "GenSigStartValue" SG_ 938 ApaActvSd_D_Actl 1;
BA_ "CrossOver_InfoCAN" SG_ 938 ApaActvSd_D_Actl 1;
BA_ "GenSigSendType" SG_ 938 ApaActvSd_D_Actl 3;
BA_ "CrossOver_InfoCAN" SG_ 938 PrkAidSwtch_B_Stat 1;
BA_ "GenSigSendType" SG_ 938 PrkAidSwtch_B_Stat 3;
BA_ "CrossOver_InfoCAN" SG_ 938 ApaMde_D_Avail 1;
BA_ "GenSigSendType" SG_ 938 ApaMde_D_Avail 3;
BA_ "CrossOver_InfoCAN" SG_ 938 PrkAidSnsFrSide_D_Stat 1;
BA_ "GenSigSendType" SG_ 938 PrkAidSnsFrSide_D_Stat 3;
BA_ "CrossOver_InfoCAN" SG_ 938 PrkAidSnsFrCrnr_D_Stat 1;
BA_ "GenSigSendType" SG_ 938 PrkAidSnsFrCrnr_D_Stat 3;
BA_ "CrossOver_InfoCAN" SG_ 938 PrkAidSnsFrCntr_D_Stat 1;
BA_ "GenSigSendType" SG_ 938 PrkAidSnsFrCntr_D_Stat 3;
BA_ "CrossOver_InfoCAN" SG_ 938 PrkAidSnsFlSide_D_Stat 1;
BA_ "GenSigSendType" SG_ 938 PrkAidSnsFlSide_D_Stat 3;
BA_ "CrossOver_InfoCAN" SG_ 938 PrkAidSnsFlCrnr_D_Stat 1;
BA_ "GenSigSendType" SG_ 938 PrkAidSnsFlCrnr_D_Stat 3;
BA_ "CrossOver_InfoCAN" SG_ 938 PrkAidSnsFlCntr_D_Stat 1;
BA_ "GenSigSendType" SG_ 938 PrkAidSnsFlCntr_D_Stat 3;
BA_ "U_P702_MY2021_Rx" SG_ 938 PrkBrkEl_B_RqFap 1;
BA_ "GenSigSendType" SG_ 938 PrkBrkEl_B_RqFap 3;
BA_ "CrossOver_InfoCAN" SG_ 938 RpaChime_D_Rq 1;
BA_ "GenSigSendType" SG_ 938 RpaChime_D_Rq 3;
BA_ "CrossOver_InfoCAN" SG_ 938 FpaChime_D_Rq 1;
BA_ "GenSigSendType" SG_ 938 FpaChime_D_Rq 3;
BA_ "CrossOver_InfoCAN" SG_ 938 PrkAidMsgTxt_D_Rq 1;
BA_ "GenSigSendType" SG_ 938 PrkAidMsgTxt_D_Rq 3;
BA_ "GenSigSendType" SG_ 938 SidePrkSnsL1_D_Stat 3;
BA_ "CrossOver_InfoCAN" SG_ 938 PrkAidAudioMute_B_Rq 1;
BA_ "GenSigSendType" SG_ 938 PrkAidAudioMute_B_Rq 3;
BA_ "GenSigSendType" SG_ 939 SidePrkSnsR4_D_Stat 3;
BA_ "GenSigSendType" SG_ 939 SidePrkSnsR3_D_Stat 3;
BA_ "GenSigSendType" SG_ 939 SidePrkSnsL4_D_Stat 3;
BA_ "GenSigSendType" SG_ 939 SidePrkSnsL3_D_Stat 3;
BA_ "CrossOver_InfoCAN" SG_ 939 PrkAidChime_D_Stat 1;
BA_ "GenSigSendType" SG_ 939 PrkAidChime_D_Stat 3;
BA_ "CrossOver_InfoCAN" SG_ 939 PrkAidSnsRlCntr_D_Stat 1;
BA_ "GenSigSendType" SG_ 939 PrkAidSnsRlCntr_D_Stat 3;
BA_ "CrossOver_InfoCAN" SG_ 939 PrkAidSnsRrSide_D_Stat 1;
BA_ "GenSigSendType" SG_ 939 PrkAidSnsRrSide_D_Stat 3;
BA_ "CrossOver_InfoCAN" SG_ 939 PrkAidSnsRrCrnr_D_Stat 1;
BA_ "GenSigSendType" SG_ 939 PrkAidSnsRrCrnr_D_Stat 3;
BA_ "CrossOver_InfoCAN" SG_ 939 PrkAidSnsRrCntr_D_Stat 1;
BA_ "GenSigSendType" SG_ 939 PrkAidSnsRrCntr_D_Stat 3;
BA_ "CrossOver_InfoCAN" SG_ 939 PrkAidSnsRlSide_D_Stat 1;
BA_ "GenSigSendType" SG_ 939 PrkAidSnsRlSide_D_Stat 3;
BA_ "CrossOver_InfoCAN" SG_ 939 PrkAidSnsRlCrnr_D_Stat 1;
BA_ "GenSigSendType" SG_ 939 PrkAidSnsRlCrnr_D_Stat 3;
BA_ "CrossOver_InfoCAN" SG_ 939 PrkAidRear_D_Stat 1;
BA_ "GenSigSendType" SG_ 939 PrkAidRear_D_Stat 3;
BA_ "CrossOver_InfoCAN" SG_ 939 PrkAidFront_D_Stat 1;
BA_ "GenSigSendType" SG_ 939 PrkAidFront_D_Stat 3;
BA_ "CrossOver_InfoCAN" SG_ 939 PrkAid_D_Falt 1;
BA_ "GenSigSendType" SG_ 939 PrkAid_D_Falt 3;
BA_ "U_P702_MY2021_Rx" SG_ 939 ApaLongCtrlEnbl_D_Rq 1;
BA_ "GenSigSendType" SG_ 939 ApaLongCtrlEnbl_D_Rq 3;
BA_ "U_P702_MY2021_Rx" SG_ 939 ApaBrk_A_Rq 1;
BA_ "GenSigStartValue" SG_ 939 ApaBrk_A_Rq 255;
BA_ "GenSigSendType" SG_ 939 PrkAidLamp_D_Rq 3;
BA_ "U_P702_MY2021_Rx" SG_ 937 Veh_V_RqFap 1;
BA_ "U_P702_MY2021_Rx" SG_ 937 TrnRngDRqFap_No_Cs 1;
BA_ "MetaData" SG_ 937 TrnRngDRqFap_No_Cs 1;
BA_ "U_P702_MY2021_Rx" SG_ 937 TrnRngDRqFap_No_Cnt 1;
BA_ "MetaData" SG_ 937 TrnRngDRqFap_No_Cnt 1;
BA_ "U_P702_MY2021_Rx" SG_ 937 TrnRng_D_RqFap 1;
BA_ "U_P702_MY2021_Rx" SG_ 937 FapLcDistToObj_L_Actl 1;
BA_ "GenSigStartValue" SG_ 937 FapLcDistToObj_L_Actl 254;
VAL_ 1070 BattULo24State_D_Qlty 3 "OK" 2 "Not_Within_Spec" 1 "Eval_In_Progress" 0 "Faulty" ;
VAL_ 1070 BattULo24_I_Actl 16383 "Faulty" ;
VAL_ 1070 BattULo24_B_Falt 1 "Yes" 0 "No" ;
VAL_ 868 BattRgenLoStat_D_Qlty 3 "OK" 2 "Not_Within_Spec" 1 "Eval_In_Progress" 0 "Faulty" ;
VAL_ 868 BattRgenLoPrtct_B_Stat 1 "Yes" 0 "No" ;
VAL_ 868 BattRgenLoDChrg_D_Stat 3 "StuckClosed" 2 "StuckOpen" 1 "Closed" 0 "Open" ;
VAL_ 868 BattRgenLoDchrg_B_Rq 1 "Yes" 0 "No" ;
VAL_ 868 BattRgenLoChrg_D_Stat 3 "StuckClosed" 2 "StuckOpen" 1 "Closed" 0 "Open" ;
VAL_ 868 BattRgenLoChrg_B_Rq 1 "Yes" 0 "No" ;
VAL_ 868 BattRgenLo_B_Falt 1 "Yes" 0 "No" ;
VAL_ 867 BattRgenLoBalnc_B_Rq 1 "Yes" 0 "No" ;
VAL_ 867 BattRgenLo_Te_Actl 255 "Fault" ;
VAL_ 865 BattRgenLo_U_Actl 2047 "Faulty" ;
VAL_ 865 BattRgenLo_I_Actl 65535 "Faulty" ;
VAL_ 878 DcacOn_B_Rq 1 "Enable" 0 "Disable" ;
VAL_ 878 DcacSys_B_Falt 1 "Yes" 0 "No" ;
VAL_ 878 DcacLedCtl_D_Rq 3 "Fast_Flash" 2 "Slow_Flash" 1 "On" 0 "Off" ;
VAL_ 924 DcacOut_Pw_Mx 2047 "Faulty" 2046 "NoDataExists" ;
VAL_ 924 DcacOut2_Pw_Actl 8191 "Faulty" 8190 "NoDataExists" ;
VAL_ 924 DcacOut1_Pw_Actl 8191 "Faulty" 8190 "NoDataExists" ;
VAL_ 924 DcacIn_Pw_Mx 2047 "Faulty" 2046 "NoDataExists" ;
VAL_ 923 DcacIn_U_Actl 4095 "Fault" 4094 "NoDataExists" ;
VAL_ 923 DcacIn_I_Actl 2047 "Faulty" 2046 "NoDataExists" ;
VAL_ 923 Dcac_Te_Actl 255 "Faulty" 254 "NoDataExists" ;
VAL_ 922 DcacRdy_D_Stat 7 "NotUsed_2" 6 "NotUsed_1" 5 "Faulted" 4 "ProtectionTempearture" 3 "ProtectionOverload" 2 "ProtectionGfci" 1 "Active" 0 "Idle" ;
VAL_ 922 DcacPlugPrsnt_B_Stat 1 "Yes" 0 "No" ;
VAL_ 922 DcacClntFlw_D_Rq 3 "High" 2 "Medium" 1 "Low" 0 "Off" ;
VAL_ 922 CoolFanDcac_D_Rq 3 "High" 2 "Medium" 1 "Low" 0 "Off" ;
VAL_ 1137 RngPerChrgAvg_L_Dsply 4095 "Faulty" 4094 "NoDataExists" ;
VAL_ 1090 VehElRnge_L_Dsply 4094 "NoDataExists" 4095 "Fault" ;
VAL_ 872 PlgActvArb_B_Dsply 1 "On" 0 "Off" ;
VAL_ 872 HybMdeStat_D_Dsply 7 "NotUsed2" 6 "EV_Charge" 5 "EV_Override" 4 "Forced_EV_Mode" 3 "Forced_Charge_Sustain_Mode" 2 "Auto_Charge_Sustain_Mode" 1 "Auto_Charge_Deplete_Mode" 0 "Null_State" ;
VAL_ 870 RngPerChrgInst_L_Dsply 4095 "Faulty" 4094 "NoDataExists" ;
VAL_ 1010 UrbanAreaDetct_D_Stat 3 "NotUsed_1" 2 "City" 1 "Subdivision" 0 "None" ;
VAL_ 589 DcdcUHi2_I_Actl 2047 "Faulty" ;
VAL_ 588 HvacAirFlw_B_RqBatt 1 "Request" 0 "NoRequest" ;
VAL_ 588 BattChrgRdyStat_D_Actl 7 "NotUsed2" 6 "NotUsed1" 5 "Faulted" 4 "ChargeComplete" 3 "Charging" 2 "BatteryChargeReady" 1 "ChargeWait" 0 "NotReady" ;
VAL_ 588 BattTracSoc2_Pc_Actl 16383 "Faulty" 16382 "NoDataExists" ;
VAL_ 588 BattTracSoc_Pc_Dsply 255 "Faulty" 254 "NoDataExists" ;
VAL_ 588 BattTracCool_D_Falt 3 "NotUsed" 2 "CoolSysPartialyOperational" 1 "Cooling_System_Faulted" 0 "Cooling_System_Operational" ;
VAL_ 588 BattTracClntIn_Te_Actl 255 "Fault" ;
VAL_ 588 BattTrac_Te_Actl 1023 "Fault" 1022 "Unknown" ;
VAL_ 588 HvacRec_D_RqMxBatt 15 "NotUsed5" 14 "NotUsed4" 13 "NotUsed3" 12 "NotUsed2" 11 "NotUsed1" 10 "No_Override" 9 "90Percent_RecircMax" 8 "80Percent_RecircMax" 7 "70Percent_RecircMax" 6 "60Percent_RecircMax" 5 "50Percent_RecircMax" 4 "40Percent_RecircMax" 3 "30Percent_RecircMax" 2 "20Percent_RecircMax" 1 "10Percent_RecircMax" 0 "0Percent_RecircFullOpen" ;
VAL_ 588 HvacAir_Flw_EstBatt 255 "Invalid" ;
VAL_ 587 PwSrcULoMde_D_Actl 3 "NotUsed_1" 2 "ReverseBoost" 1 "ForwardBuck" 0 "Standby" ;
VAL_ 587 BattTracWarnLamp_B_Rq 1 "On" 0 "Off" ;
VAL_ 587 BattTracSrvcRqd_B_Rq 1 "On" 0 "Off" ;
VAL_ 1116 TrlrAidSetup_D2_Rq 15 "NotUsed_9" 14 "NotUsed_8" 13 "NotUsed_7" 12 "NotUsed_6" 11 "NotUsed_5" 10 "NotUsed_4" 9 "NotUsed_3" 8 "NotUsed_2" 7 "NotUsed_1" 6 "CompleteSetup" 5 "ReturnToSetup" 4 "StickerNotCircled" 3 "ConfirmSetup" 2 "EndSetup" 1 "BeginSetup" 0 "Inactive" ;
VAL_ 1116 TrlrAidEnbl_D2_Rq 7 "NotUsed_4" 6 "NotUsed_3" 5 "NotUsed_2" 4 "NotUsed_1" 3 "Deactivate" 2 "ActivateTrg" 1 "ActivateTba" 0 "Inactive" ;
VAL_ 1006 PersIndexIpmb_D_Actl 7 "Unused_3" 6 "Unused_2" 5 "Unused_1" 4 "Vehicle" 3 "PERS_4" 2 "PERS_3" 1 "PERS_2" 0 "PERS_1" ;
VAL_ 992 MsgCntrPersIndex_D_Rq 7 "Unused_3" 6 "Unused_2" 5 "Unused_1" 4 "Vehicle" 3 "PERS_4" 2 "PERS_3" 1 "PERS_2" 0 "PERS_1" ;
VAL_ 992 MsgCntrDsplyOp_D_Rq 7 "Unused_2" 6 "Unused_1" 5 "Copy" 4 "Restore" 3 "Upload" 2 "Set" 1 "Query" 0 "Null" ;
VAL_ 820 AhbStatGfhbFdbk_D_Actl 3 "GfhbHighBeamFullyOn" 2 "GfhbHighBeamPartlyOn" 1 "GfhbHighBeamOff" 0 "GfhbUnavailable" ;
VAL_ 820 HeadLghtDrvSide_B_Stat 1 "Left_Hand_Traffic" 0 "Right_Hand_Traffic" ;
VAL_ 820 HeadLghtHiOn_B_StatHcm 1 "On" 0 "Off" ;
VAL_ 820 Adaptive_Hdlmp_Fault 1 "Yes" 0 "No" ;
VAL_ 1100 WakeAlarm1_B_Typ 1 "CanAndEcuDriveCircuit" 0 "CanOnly" ;
VAL_ 1100 Veh_V_DsplyTrailCtlSet 63 "Faulty" ;
VAL_ 1100 TrailCtlPt_B_Falt 1 "Fault" 0 "No_Fault" ;
VAL_ 1100 AutoTowAllw_D_StatMnu 3 "TowHaulCommandedOn" 2 "AutoTowHaulEnabled" 1 "AutoTowHaulDisabled" 0 "NoSelection" ;
VAL_ 1100 AutoTowActv_B_Stat 1 "Yes" 0 "No" ;
VAL_ 1100 GrossTrainWeight_M_Est 255 "Faulty" 254 "NoDataExists" ;
VAL_ 1098 EdmSailMdeOn_B_Stat 1 "On" 0 "Off" ;
VAL_ 1098 EdmMsgTxt_D_Rq 15 "NotUsed_4" 14 "NotUsed_3" 13 "NotUsed_2" 12 "NotUsed_1" 11 "OverallGoodScore" 10 "WorkOnCompliance" 9 "GoodCompliance" 8 "WorkOnGearShifting" 7 "GoodGearShifting" 6 "WorkOnEfficientSpeed" 5 "GoodEfficientSpeed" 4 "WorkOnDeceleration" 3 "GoodDeceleration" 2 "WorkOnAcceleration" 1 "GoodAcceleration" 0 "NoMessage" ;
VAL_ 1098 EdmLamp_D_Dsply 15 "NotUsed_7" 14 "NotUsed_6" 13 "NotUsed_5" 12 "NotUsed_4" 11 "NotUsed_3" 10 "NotUsed_2" 9 "NotUsed_1" 8 "CoastingEngineBrake" 7 "CoastingShiftToNeutral" 6 "FreewayJunction" 5 "Curve2" 4 "Curve1" 3 "SpeedLimit" 2 "Crossing" 1 "FreewayExit" 0 "NoRecommendation" ;
VAL_ 1098 EdmCmplnc_B_Dsply 1 "Yes" 0 "No" ;
VAL_ 1086 FuelPumpPwr_B_Rq 1 "On" 0 "Off" ;
VAL_ 1086 ElLoadCtl_D_Rq 7 "Unused3" 6 "Unused2" 5 "Unused1" 4 "HoldAllDrvrInvisibleLoads" 3 "StdDriverInvisibleLoadsOn" 2 "AllDriverInvisibleLoadsOn" 1 "All_Possible_Loads_Off" 0 "No_Request" ;
VAL_ 1085 ULoRgenTestMde_B_Stat 1 "Active" 0 "Inactive" ;
VAL_ 1085 PwSrcULoOvrTe_B_Actl 1 "Yes" 0 "No" ;
VAL_ 1085 PwSrcULoFalt_D_Stat 3 "Fault_No_Output" 2 "Fault_Reduced_Output" 1 "Fault_NonSpecific" 0 "No_Fault" ;
VAL_ 1085 PwSrcULoDcnnt_B_Stat 1 "Loose_or_Disconnected" 0 "Connected" ;
VAL_ 1085 PwSrcULo_Pc_Mx 255 "Fault" ;
VAL_ 1085 PwSrcULoComm_B_Falt 1 "Fault" 0 "No_Fault" ;
VAL_ 1085 PwSrcULo_I_Mx 255 "Fault" ;
VAL_ 1085 PwSrcULo_I_Actl 255 "Fault" ;
VAL_ 1071 CluPdlPosPcMeas_D_Qf 3 "OK" 2 "Not_Within_Specifications" 1 "No_Data_Exists" 0 "Faulty" ;
VAL_ 1069 SlMde_D_Stat 3 "IsaNotConfigured" 2 "Manual_Mode" 1 "Auto_Mode" 0 "Null" ;
VAL_ 1069 SlMde_D_RqDsply 3 "NotUsed" 2 "ManualSpeed_LimiterSymbol" 1 "AutoSpeed_LimiterSymbol" 0 "NoSpeed_LimiterSymbol" ;
VAL_ 1069 IsaOffst_D_Stat 15 "Faulty" 14 "Null" 13 "Thirteen" 12 "Twelve" 11 "Eleven" 10 "Ten" 9 "Nine" 8 "Eight" 7 "Seven" 6 "Six" 5 "Five" 4 "Four" 3 "Three" 2 "Two" 1 "One" 0 "Zero" ;
VAL_ 1069 GrllShtrPos_D_Cmd 15 "Fully_Open" 14 "Position14" 13 "Position13" 12 "Position12" 11 "Position11" 10 "Position10" 9 "Position9" 8 "Position8" 7 "Position7" 6 "Position6" 5 "Position5" 4 "Position4" 3 "Position3" 2 "Position2" 1 "Position1" 0 "Fully_Closed" ;
VAL_ 1069 GrllShtrPos_B_Falt 1 "Fault" 0 "No_Fault" ;
VAL_ 1069 ObdWarmUp_B_Complt 1 "Yes" 0 "No" ;
VAL_ 1069 EngMsgTxt_D_Rq 3 "Undefined_2" 2 "Undefined_1" 1 "Power_Reduced_to_LowerTemp" 0 "No_Message" ;
VAL_ 1069 EngAirIn_Te_Actl 1023 "Fault" 1022 "Unknown" ;
VAL_ 1060 RearDiffOilTeWarn_B_Rq 1 "On" 0 "Off" ;
VAL_ 1060 RearDiffOil_Te_Actl 511 "Faulty" ;
VAL_ 1060 BpedDrvMsgTxt_B_Dsply 1 "On" 0 "Off" ;
VAL_ 1060 FuelLvlWarn_D_ActlEng 7 "DteLevel5Lowest" 6 "DteLevel4" 5 "DteLevel3" 4 "DteLevel2NonMyKey" 3 "DteLevel1MyKey" 2 "VeryLow" 1 "Low" 0 "OK" ;
VAL_ 1060 SelDrvMdePt_D_Stat 0 "NotAvailable" 1 "Available" 2 "TemporarilyNotAvailable" 3 "Faulty" ;
VAL_ 1057 FohEng_D_Rq 3 "AutoEnable_ParkEnable" 2 "AutoDisable_ParkEnable" 1 "AutoEnable_ParkDisable" 0 "Disable_Stop" ;
VAL_ 1057 EngIdlShutDwnTxt_D_Rq 3 "NotUsed" 2 "EngineShutdownOnPrevDrive" 1 "FeatureDisabledDueToFault" 0 "NoMessage" ;
VAL_ 1057 EngIdlShutDown_D_Stat 3 "Not_used" 2 "Engine_Shutdown" 1 "Initiated_Countdown" 0 "Normal_Operation" ;
VAL_ 1057 FUEL_ALCOHOL_PERCNT 255 "Invalid" ;
VAL_ 1057 TrnTotTq_Rt_Est 65535 "Fault" 65534 "Unknown" ;
VAL_ 1057 TrnTotLss_Tq_Est 255 "Fault" 254 "Unknown" ;
VAL_ 1057 ECMMILRequest 3 "Not_Used" 2 "Flash" 1 "On" 0 "Off" ;
VAL_ 1057 AirCondFluidHi_P_Actl 255 "Fault" 254 "Unknown" ;
VAL_ 1057 OilPressureWarning 1 "Low_Pressure_Lamp_On" 0 "Normal_Pressure_Lamp_Off" ;
VAL_ 1057 VehVLimStat_D_Actl 7 "Undefined_3" 6 "Undefined_2" 5 "Undefined_1" 4 "ASL_Fault_Condition" 3 "Active_and_Limiting" 2 "Active_but_Not_Limiting" 1 "Standby" 0 "Off" ;
VAL_ 1057 VehVLimActv_B_Actl 1 "Active" 0 "Inactive" ;
VAL_ 1057 CoolantFanStepAct 31 "Unused7" 30 "Unused6" 29 "Unused5" 28 "Unused4" 27 "Unused3" 26 "Unused2" 25 "Unused1" 23 "Step23" 22 "Step22" 21 "Step21" 20 "Step20" 19 "Step19" 18 "Step18" 17 "Step17" 16 "Step16" 15 "Step15" 14 "Step14" 13 "Step13" 12 "Step12" 11 "Step11" 10 "Step10" 9 "Step9" 8 "Step8" 7 "Step7" 6 "Step6" 5 "Step5" 4 "Step4" 3 "Step3" 2 "Step2" 1 "Step1" 24 "Max_Fan_Speed_Req" 0 "Fan_Cmd_Off" ;
VAL_ 1055 EcoCochInstNeg_B_Dsply 1 "True" 0 "False" ;
VAL_ 562 GearNtrl_D_Stat 3 "Faulty" 2 "NoDataExists" 1 "Yes" 0 "No" ;
VAL_ 523 UreaMxAdd_L2_Actl 511 "Faulty" ;
VAL_ 523 WaterInFuel_B_Falt 1 "Fault" 0 "No_Fault" ;
VAL_ 523 UreaMnAdd_L2_Actl 255 "Faulty" ;
VAL_ 517 FapLc_B_Err 1 "Yes" 0 "No" ;
VAL_ 516 EngAoutNActl_D_QF 3 "OK" 2 "Not_Within_Specifications" 1 "No_Data_Exists" 0 "Faulty" ;
VAL_ 516 EngAout3_N_Actl 65535 "Invalid" ;
VAL_ 516 ApedPos_PcRate_ActlArb 255 "Fault" 254 "Unknown" ;
VAL_ 516 ApedPosPcActl_D_Qf 3 "OK" 2 "Not_Within_Specifications" 1 "No_Data_Exists" 0 "Faulty" ;
VAL_ 514 StrtrMtrCtlMsgTxt_D2_Rq 3 "NotUsed" 2 "ShiftToNeutralToStart" 1 "ShiftToParkToStart" 0 "NoRequest" ;
VAL_ 514 StrtrMtrDlyStrt_B_Stat 1 "Yes" 0 "No" ;
VAL_ 514 VehVTrlrAid_B_Avail 1 "Yes" 0 "No" ;
VAL_ 514 StrtrMtrCtlMsgTxt_D_Rq 7 "Start_In_Gear_Allowed" 6 "Pending_Start_Cancelled" 5 "Start_Pending_Please_Wait" 4 "Cranking_Limit_Exceeded" 3 "Press_Brk_and_Shift_to_P_N" 2 "Press_Clutch_and_Brake" 1 "Press_Clutch_To_Start" 0 "No_Display" ;
VAL_ 514 VehVActlEng_D_Qf 3 "OK" 2 "Not_Within_Specifications" 1 "No_Data_Exists" 0 "Faulty" ;
VAL_ 514 GearRvrse_D_Actl 7 "Fault" 6 "NotUsed_3" 5 "NotUsed_2" 4 "NotUsed_1" 3 "Active_confirmed" 2 "Active_not_confirmed" 1 "Inactive_confirmed" 0 "Inactive_not_confirmed" ;
VAL_ 512 PtDrvMde_D_Stat 15 "Faulty" 14 "NotUsed11" 13 "NotUsed10" 12 "NotUsed9" 11 "NotUsed8" 10 "NotUsed7" 9 "NotUsed6" 8 "NotUsed5" 7 "Drag" 6 "Rock" 5 "Baja" 4 "Sand" 3 "TowHaulGradeAssist" 2 "SnowWet" 1 "Sport" 0 "Normal" ;
VAL_ 381 EngOilSrvcMsgTxt_D_Rq 7 "NotUsed3" 6 "NotUsed2" 5 "NotUsed1" 4 "ResetComplete" 3 "ResetInProgress" 2 "ChangeOilNow" 1 "ChangeOilSoon" 0 "NoText" ;
VAL_ 381 RunDryPrevent_B_Stat 1 "True" 0 "False" ;
VAL_ 381 WaterInFuel 1 "On" 0 "Off" ;
VAL_ 381 GlowIndication 1 "On" 0 "Off" ;
VAL_ 380 EngOilLvlWarn_D_Rq1 7 "Undefined_3" 6 "Undefined_2" 5 "Engine_Oil_Monitor_Fault" 3 "Engine_Oil_High" 2 "Engine_Oil_Critical_Low" 1 "Engine_Oil_Low" 0 "No_Message" 4 "Engine_Oil_Critical_High" ;
VAL_ 380 EngExhBrkOnLamp_B_Rq 1 "On" 0 "Off" ;
VAL_ 380 EngExhBrkAutoLamp_B_Rq 1 "On" 0 "Off" ;
VAL_ 380 EngExhBrkMde_D_Actl 6 "ExhBrkDisable_NoError" 5 "ExhBrkActive_AUTO" 4 "ExhBrkActive_ON" 3 "ExhBrkRequest_AUTO" 2 "ExhBrkRequest_ON" 1 "ExhBrkNoRequest_OFF" 0 "ExhBrkUnavailable_Error" ;
VAL_ 377 HvacAirFullOut_B_Rq 1 "Yes" 0 "No" ;
VAL_ 377 TrnManShif_D_IndDrv 7 "Undefined_3" 6 "Undefined_2" 5 "Shift_to_Neutral" 4 "Downshift_Recommendation" 3 "Upshift_Warning" 2 "Upshift_Performance" 1 "Upshift_Fuel_Economy" 0 "No_Indication" ;
VAL_ 377 TrnManShifGear_D_IndDrv 7 "Indicate_Reverse_Gear" 6 "Indicate_Gear6" 5 "Indicate_Gear5" 4 "Indicate_Gear4" 3 "Indicate_Gear3" 2 "Indicate_Gear2" 1 "Indicate_Gear1" 0 "No_Indication" ;
VAL_ 377 FuelFillInlet_B_Dsply 1 "Yes" 0 "No" ;
VAL_ 377 EngSrvcRqd_B_Rq 1 "Engine_Service_Required" 0 "No_engine_service_required" ;
VAL_ 377 OdoCount 255 "Invalid" ;
VAL_ 377 TrnKickDown_B_RqDrv 1 "Yes" 0 "No" ;
VAL_ 377 FuelFilterLamp_B_Dsply 1 "On" 0 "Off" ;
VAL_ 377 AirCondRec_B_Rq 1 "Yes" 0 "No" ;
VAL_ 377 AirCondClutch_B_Stats 1 "Yes" 0 "No" ;
VAL_ 376 AslChime_B_Rq 1 "Yes" 0 "No" ;
VAL_ 376 AslIconDsply_D_Rq 3 "Not_Used" 2 "On_Active" 1 "On_Passive" 0 "Off" ;
VAL_ 376 GasPrtc_D_RqDsply 7 "NotUsed_5" 6 "NotUsed_4" 5 "NotUsed_3" 4 "NotUsed_2" 3 "NotUsed_1" 2 "GpfOverLimit" 1 "GpfAtLimit" 0 "NormalOperation" ;
VAL_ 376 DynoMde_B_Cmd 1 "Two_Wheel_Dyno" 0 "Normal_Operation" ;
VAL_ 376 HvacHtrCore2_Te_Actl 1023 "Faulty" ;
VAL_ 376 EcssLamp_D_RqDsply 3 "Not_Used" 2 "Flash" 1 "On" 0 "Off" ;
VAL_ 376 AirAmbTe_D_Qf 3 "OK" 2 "Not_Within_Specifications" 1 "No_Data_Exists" 0 "Faulty" ;
VAL_ 376 AirAmb_P_Actl 63 "Fault" 62 "NoDataExists" ;
VAL_ 373 DieslPrtc2_D_RqDsply 15 "NotUsed4" 14 "NotUsed3" 13 "NotUsed2" 12 "NotUsed1" 11 "OCR_ExhFilterClean_Stopped" 10 "OCR_ExhFilterCleaned" 9 "RgnOff_AtLimit" 8 "RgnOff_Overloaded" 7 "RgnOff_Loaded" 6 "Exhaust_Filter_Full" 5 "DPF_Overlimit" 4 "DPF_AtLimit" 3 "ExhFilter_Drive_Completed" 2 "Cleaning_Exhaust_Filter" 1 "DPF_Overloaded" 0 "DPF_Normal_Operation" ;
VAL_ 373 DieslPrtcRgen_D_Actl 3 "Undefined" 2 "Regen_Level_2" 1 "Regen_Level_1" 0 "No_regen" ;
VAL_ 373 EngTeColdPrtct_D_Stats 3 "Engine_Warm_RdcPwr" 2 "OK_to_Drive" 1 "Engine_Warm_PlsWait" 0 "Normal_Operation" ;
VAL_ 373 EngExhOvrTe_B_RqDsply 1 "Active" 0 "Inactive" ;
VAL_ 359 PrplWhlRgenMn_Tq_Actl 8191 "Faulty" ;
VAL_ 359 ElPw_D_StatStrtStop 15 "NotUsed6" 14 "NotUsed5" 13 "NotUsed4" 12 "NotUsed3" 11 "NotUsed2" 10 "NotUsed1" 9 "Supported_Level_4" 8 "Supported_Level_3" 7 "Supported_Level_2" 6 "Supported_Level_1" 5 "Limited_Support" 4 "Fault_Limited" 3 "LV_Event_in_Progress" 2 "Not_Supported_Imminent" 1 "Supported_All" 0 "Not_Supported" ;
VAL_ 359 PrplWhlTot2_Tq_Actl 65535 "Fault" 65534 "NoDataExists" ;
VAL_ 359 PwPckTq_D_Stat 3 "PwPckOn_TqAvailable" 2 "StartInPrgrss_TqNotAvail" 1 "PwPckOn_TqNotAvailable" 0 "PwPckOff_TqNotAvailable" ;
VAL_ 359 Eng_D_Stat 3 "NotUsed" 2 "EngAutoStopped" 1 "EngOn" 0 "EngOff" ;
VAL_ 359 ElPw_D_Stat 7 "NotUsed_3" 6 "NotUsed_2" 5 "NotUsed_1" 4 "Fault_Limited" 3 "LV_Event_In_Progress" 2 "Not_Supported_Imminent" 1 "Supported" 0 "Not_Supported" ;
VAL_ 359 TrnAinTq_D_Qf 3 "OK" 2 "Not_Within_Specifications" 1 "No_Data_Exists" 0 "Faulty" ;
VAL_ 358 AutoStopPtDelta_I_Est 255 "Fault" ;
VAL_ 358 StopStrtStdby_D_Indic 6 "NotUsed2" 5 "Telltale_Struck_Out" 4 "Telltale_Flashing_Amber" 3 "Telltale_On_Amber" 2 "Telltale_Flashing_Green" 1 "Telltale_On_Green" 0 "Telltale_Off" 7 "NotUsed3" ;
VAL_ 358 StopStrtIODTxt_D_Rq 31 "Message31" 30 "Message30" 29 "Message29" 28 "Message28" 27 "Message27" 26 "Message26" 25 "Message25" 24 "Message24" 23 "Message23" 22 "Message22" 21 "Message21" 20 "Message20" 19 "Message19" 18 "Message18" 17 "Message17" 16 "Message16" 15 "Message15" 14 "Message14" 13 "Message13" 12 "Message12" 11 "Message11" 10 "Message10" 9 "Message9" 8 "Message8" 7 "Message7" 6 "Message6" 5 "Message5" 4 "Message4" 3 "Message3" 2 "Message2" 1 "Message1" 0 "NoMessage" ;
VAL_ 358 StopStrtDrvMde_D_Indic 3 "NotUsed" 2 "StartStop_IndirectDeselect" 1 "StopStart_Deselected" 0 "StopStart_Selected" ;
VAL_ 358 StopStrtMsgTxt_D_Rq 15 "Message_15" 14 "Message_14" 13 "Message_13" 12 "Message_12" 11 "Message_11" 10 "Message_10" 9 "Message_9" 8 "Message_8" 7 "Message_7" 6 "Message_6" 5 "Message_5" 4 "Message_4" 3 "Message_3" 2 "Message_2" 1 "Message_1" 0 "NoMessage" ;
VAL_ 358 OdoTripVerify_L_Actl 16777215 "Fault" ;
VAL_ 358 HiElPwInhbt_B_Stat 1 "Inhibit" 0 "No_Inibit" ;
VAL_ 357 BPedDrvAppl_D_QF 3 "OK" 2 "Not_Within_Specifications" 1 "No_Data_Exists" 0 "Faulty" ;
VAL_ 357 CmbbDeny_B_ActlPrpl 1 "Yes" 0 "No" ;
VAL_ 357 PrplTqMnSat_B_Actl 1 "Yes" 0 "No" ;
VAL_ 357 BpedDrvAppl_D_Actl 3 "_Not_Allowed" 2 "Driver_Braking" 1 "Driver_Not_Braking" 0 "Not_Allowed" ;
VAL_ 357 CmbbEngTqMn_B_Actl 1 "Yes" 0 "No" ;
VAL_ 357 Veh_V_DsplyCcSet 255 "Fault" 254 "Unknown" ;
VAL_ 357 AccEngStat_D_Actl 7 "Undefined_2" 6 "Undefined_1" 5 "ACCSoonCancel_due_Low_Spd" 4 "Shift_Down_Recommendation" 3 "Shift_Up_Recommendation" 2 "ACCNotAllowedToBeActivated" 1 "ACCStandby_due_Auto_Cancel" 0 "Normal_Operation" ;
VAL_ 357 CcMde_D_Actl 7 "TapDownWaiting" 6 "TapUpWaiting" 5 "Resuming_Low" 4 "Resuming_High" 3 "Decelerating" 2 "Accelerating" 1 "Keeping_Speed" 0 "Not_Active" ;
VAL_ 357 CcStat_D_Actl 7 "Undefined_2" 6 "Undefined_1" 5 "Active" 4 "Active_Que_Assist" 3 "Standby" 2 "Standby_Denied" 1 "Denied" 0 "Off" ;
VAL_ 357 CcOvrrdActv_B_Actl 1 "Cruise_Overridden" 0 "Cruise_Req_Not_Overridden" ;
VAL_ 357 AccStopMde_D_Rq 3 "Stop_Mode_Active" 2 "EPBApplyOrBrakeReleaseWarn" 1 "Limit_Rolling_Speed" 0 "Stop_Mode_Not_Active" ;
VAL_ 355 AutoRgenTxt_B_RqDsply 1 "AutExhFilterCleanOFF" 0 "AutExhFilterCleanON" ;
VAL_ 355 AccFllwMdeActv_B_Actl 1 "Active" 0 "Inactive" ;
VAL_ 355 EngPtoMde_D_Actl 7 "Undefined" 6 "Split_Shaft_Stationary" 5 "Not_Used_2" 4 "PTO_Mobile" 3 "Not_Used_1" 2 "PTO_Stationary" 1 "BCP" 0 "Off" ;
VAL_ 355 ManRgenTxt_D_RqDsply 7 "NotUsed3" 6 "NotUsed2" 5 "NotUsed1" 4 "Cleaning_Aborted_Stopped" 3 "Cleaning_Completed" 2 "Cleaning_In_Progress" 1 "Cleaning_Allowed" 0 "Cleaning_Not_Allowed" ;
VAL_ 355 ManRgenSoot_Pc_RqDsply 127 "Fault" ;
VAL_ 355 DieslMsgTxt_D_Rq 3 "NotUsed2" 2 "NotUsed1" 1 "ReducedEnginePower" 0 "NoMessage" ;
VAL_ 342 EngOvrhtMitgActv_D_Ind 3 "Undefined" 2 "Mode2" 1 "Mode1" 0 "Normal_Mode" ;
VAL_ 342 EngClntTe_D_Qf 3 "OK" 2 "Not_Within_Specifications" 1 "No_Data_Exists" 0 "Faulty" ;
VAL_ 342 EngOil_Te_Actl 255 "Fault" 254 "Unknown" ;
VAL_ 71 immoTarget1Status 7 "Unused4" 6 "Unused3" 5 "Unused2" 4 "Unused1" 3 "DISABLED_RESET   " 2 "ENABLED_NONMOTIVE_START" 1 "ENABLED_MOTIVE_START" 0 "DISABLED" ;
VAL_ 71 immoTarget1Cmd 7 "Unused4" 6 "Unused3" 5 "Unused2" 4 "Unused1" 3 "TARGET1_IDBLOCK2" 2 "TARGET1_IDBLOCK1" 1 "CHALLENGE" 0 "IDLE" ;
VAL_ 137 SteWhlOffstRq_D_Stat 3 "Faulty" 2 "NoDataExists" 1 "Allow_External_Angle_Req" 0 "Deny_External_Angle_Req" ;
VAL_ 137 SteWhlOffst_An_TotActl 32767 "Faulty" 32766 "NoDataExists" ;
VAL_ 137 SteWhlBrkOffst_An_Actl 32767 "Faulty" 32766 "NoDataExists" ;
VAL_ 129 SelDrvMdeSwtch_D_Stat4 3 "Faulty" 2 "SwitchState2" 1 "SwitchState1" 0 "NotPressed" ;
VAL_ 129 SteWhlSwtchView_B_Stat 1 "Pressed" 0 "Not_Pressed" ;
VAL_ 129 SteWhlSwtchSet_B_Stat 1 "Pressed" 0 "Not_Pressed" ;
VAL_ 129 SteWhlSwtchPhon_B_Stat 1 "Pressed" 0 "Not_Pressed" ;
VAL_ 129 SteWhlSwtchNav_B_Stat 1 "Pressed" 0 "Not_Pressed" ;
VAL_ 129 SteWhlSwtchMed_B_Stat 1 "Pressed" 0 "Not_Pressed" ;
VAL_ 129 SteWhlSwtchIod_B_Stat 1 "Pressed" 0 "Not_Pressed" ;
VAL_ 129 SteWhlSwtchHud_B_Stat 1 "Pressed" 0 "Not_Pressed" ;
VAL_ 129 SteWhlSwtchBack_B_Stat 1 "Pressed" 0 "Not_Pressed" ;
VAL_ 129 SteWhlSwtchMenu_B_Stat 1 "Pressed" 0 "Not_Pressed" ;
VAL_ 129 SteEffortInc_B_RqDrv 1 "Pressed" 0 "Not_Pressed" ;
VAL_ 129 SelDrvMdeInc_B_RqDrv 1 "Pressed" 0 "Not_Pressed" ;
VAL_ 129 SelDrvMdeDec_B_RqDrv 1 "Pressed" 0 "Not_Pressed" ;
VAL_ 129 SuspDampInc_B_RqDrv 1 "Pressed" 0 "Not_Pressed" ;
VAL_ 129 SteWhlSwtchUp_B_Stat 1 "Pressed" 0 "Not_Pressed" ;
VAL_ 129 SteWhlSwtchRght_B_Stat 1 "Pressed" 0 "Not_Pressed" ;
VAL_ 129 SteWhlSwtchOk_B_Stat 1 "Pressed" 0 "Not_Pressed" ;
VAL_ 129 SteWhlSwtchLeft_B_Stat 1 "Pressed" 0 "Not_Pressed" ;
VAL_ 129 SteWhlSwtchDown_B_Stat 1 "Pressed" 0 "Not_Pressed" ;
VAL_ 129 SteWhlSwtchHome_B_Stat 1 "Pressed" 0 "Not_Pressed" ;
VAL_ 129 SteWhlSwtchInfo_B_Stat 1 "Pressed" 0 "Not_Pressed" ;
VAL_ 935 LcwaDetctRight2_B_Stat 1 "Yes" 0 "No" ;
VAL_ 935 RbaCtaRight_D_Stat 7 "Faulty" 6 "NotUsed_2" 5 "NotUsed_1" 4 "Invalid" 3 "Disabled" 2 "On" 1 "Trailer_Tow_Off" 0 "Off" ;
VAL_ 935 CtaAlrtRight2_D_Stat 7 "NotUsed3" 6 "NotUsed2" 5 "NotUsed1" 4 "AlertZone4" 3 "AlertZone3" 2 "AlertZone2" 1 "AlertZone1" 0 "Off" ;
VAL_ 935 BttRight_D_Stat 7 "NotUsed" 6 "Disabled" 5 "Off" 4 "OffTemp" 3 "NotConnected" 2 "Pending" 1 "Connected" 0 "NotDetermined" ;
VAL_ 935 BttRight_D_RqDrv 3 "NotUsed" 2 "Request" 1 "NoRequest" 0 "Null" ;
VAL_ 935 CtaBrkRightMsgTxt_B_Rq 1 "Enable" 0 "Disable" ;
VAL_ 935 CtaRightBrkEnbl_B_Rq 1 "Enable" 0 "Disable" ;
VAL_ 935 CtaRightBrkDecel_B_Rq 1 "Enable" 0 "Disable" ;
VAL_ 935 CtaSnsRight_D_Stat 3 "Invalid" 2 "System_Failure" 1 "Blocked" 0 "Clear" ;
VAL_ 935 CtaAlrtRight_D_Stat 1 "On" 0 "Off" ;
VAL_ 935 CtaRight_D_Stat 7 "NotUsed_3" 6 "NotUsed_2" 5 "NotUsed_1" 4 "Invalid" 3 "Disabled" 2 "On" 1 "Trailer_Tow_Off" 0 "Off" ;
VAL_ 935 SodRight_D_Stat 7 "NotUsed_3" 6 "NotUsed_2" 5 "NotUsed_1" 4 "Invalid" 3 "Disabled" 2 "On" 1 "Trailer_Tow_Off" 0 "Off" ;
VAL_ 935 SodSnsRight_D_Stat 3 "Second_Warning_Audio" 2 "System_Failure" 1 "Blocked" 0 "Clear" ;
VAL_ 935 SodAlrtRight_D_Stat 3 "Bulb_Proveout" 2 "Flash" 1 "On" 0 "Off" ;
VAL_ 935 SodDetctRight_D_Stat 4 "Sensor_Blocked" 3 "Sensor_Fault" 2 "Flash_On" 1 "Alert_On" 0 "AlertOff_FlashOff_SensrClr" ;
VAL_ 935 SodInnrRight_D_Stat 3 "Reporting" 2 "Not_Reporting" 1 "System_Standby" 0 "Initialization" ;
VAL_ 935 CtaInnrRight_D_Stat 3 "Reporting" 2 "Not_Reporting" 1 "System_Standby" 0 "Initialization" ;
VAL_ 935 LcwaDetctRight1_B_Stat 1 "Yes" 0 "No" ;
VAL_ 935 LcwaRight_D_Stat 7 "Faulty" 6 "NotUsed_3" 5 "NotUsed_2" 4 "NotUsed_1" 3 "Disabled" 2 "TemporaryUnavailable" 1 "SensorBlocked" 0 "Available" ;
VAL_ 1108 RCMSerialNoByte8 255 "Invalid" 254 "Unknown" ;
VAL_ 1108 RCMSerialNoByte7 255 "Invalid" 254 "Unknown" ;
VAL_ 1108 RCMSerialNoByte6 255 "Invalid" 254 "Unknown" ;
VAL_ 1108 RCMSerialNoByte5 255 "Invalid" 254 "Unknown" ;
VAL_ 1108 RCMSerialNoByte4 255 "Invalid" 254 "Unknown" ;
VAL_ 1108 RCMSerialNoByte3 255 "Invalid" 254 "Unknown" ;
VAL_ 1108 RCMSerialNoByte2 255 "Invalid" 254 "Unknown" ;
VAL_ 1108 RCMSerialNoByte1 255 "Invalid" 254 "Unknown" ;
VAL_ 1146 TrlrAidSwtch_D_RqDrv 3 "Faulty" 2 "NotUsed" 1 "Pressed" 0 "Not_Pressed" ;
VAL_ 1146 TrlrAidCtl_U_RqDrv 4095 "Faulty" 4094 "NoDataExists" ;
VAL_ 1146 TrlrAidAn_URate_Actl 4095 "Faulty" 4094 "NoDataExists" ;
VAL_ 1146 TrlrAidAn_U_Actl 4095 "Faulty" 4094 "NoDataExists" ;
VAL_ 533 TrlrAidMde_D_Rq 3 "Mode_3" 2 "Mode_2" 1 "Mode_1" 0 "NoRequest" ;
VAL_ 533 TCU_Init_Actvtn_St 3 "NotUsed" 2 "InitialActivateDeny" 1 "InitialActivateAccept" 0 "Invalid" ;
VAL_ 533 TCU_Final_Actvtn_St 3 "NotUsed" 2 "FinalActivateDeny" 1 "FinalActivateAccept" 0 "Invalid" ;
VAL_ 533 OtaTrg_D_Stat 3 "NotUsed_1" 2 "Accepted" 1 "NotAccepted" 0 "Null" ;
VAL_ 533 OnbChrgGoTTouch_D_Rq 3 "NotUsed" 2 "On" 1 "Off" 0 "Null" ;
VAL_ 533 OnbChrgGoTPrcond_D_Rq 3 "High" 2 "Medium" 1 "Low" 0 "Off" ;
VAL_ 533 OnbChrgGoTOn_D_Rq 3 "NotUsed" 2 "On" 1 "Off" 0 "Null" ;
VAL_ 533 OnbChrgGoTMnte_D_Rq 15 "NotUsed_4" 14 "NotUsed_3" 13 "NotUsed_2" 12 "NotUsed_1" 11 "Minute_55" 10 "Minute_50" 9 "Minute_45" 8 "Minute_40" 7 "Minute_35" 6 "Minute_30" 5 "Minute_25" 4 "Minute_20" 3 "Minute_15" 2 "Minute_10" 1 "Minute_5" 0 "Minute_0" ;
VAL_ 533 OnbChrgGoTHr_T_Rq 31 "Faulty" 30 "NoDataExists" ;
VAL_ 533 OnbChrgGoTExtHtr_D_Rq 3 "NotUsed" 2 "On" 1 "Off" 0 "Null" ;
VAL_ 533 OnbChrgGoTDelete_B_Rq 1 "Request" 0 "NoRequest" ;
VAL_ 533 OnbChrgClearAll_B_Rq 1 "Request" 0 "NoRequest" ;
VAL_ 533 PaakMyKey_D_Rq 3 "NotUsed" 2 "ConfirmNewPaakMyKey" 1 "RequestNewPaakMyKey" 0 "None" ;
VAL_ 533 OnbChrgGoTUpdate_B_Rq 1 "Request" 0 "NoRequest" ;
VAL_ 1041 ElCmprUHi_D_Stat 3 "Overvoltage" 2 "Undervoltage" 1 "InRange" 0 "Undetermined" ;
VAL_ 1041 ElCmprOverTe_D_Stat 3 "OverTempStop" 2 "OverTempWarning" 1 "Normal" 0 "Undefined" ;
VAL_ 1041 ElCmpr_N_Actl 255 "Invalid" ;
VAL_ 1041 ElCmpr_Pw_Actl 255 "Invalid" ;
VAL_ 1041 ElCmpr_D_Stat 7 "Signal_Invalid" 6 "Comp_Off_ActlSpd_Abnormal" 5 "Comp_Off_TrgtSpd_OutRange" 4 "Comp_Shutdown" 3 "Comp_Stopped_Self_Protect" 2 "Comp_Degraded" 1 "Comp_On" 0 "Comp_Off" ;
VAL_ 1041 ElCmprPerfErr_D_Falt 3 "NotUsed" 2 "Pass" 1 "Fail" 0 "Not_Diagnose_Yet" ;
VAL_ 1041 ElCmprInnrErr_D_Falt 3 "NotUsed" 2 "Pass" 1 "Fail" 0 "Not_Diagnose_Yet" ;
VAL_ 1041 ElCmprLostComm_D_Falt 3 "NotUsed" 2 "Pass" 1 "Fail" 0 "Not_Diagnose_Yet" ;
VAL_ 1041 ElCmprOverLoad_D_Falt 3 "NotUsed" 2 "Pass" 1 "Fail" 0 "Not_Diagnose_Yet" ;
VAL_ 1041 ElCmprOverTe_D_Falt 3 "NotUsed" 2 "Pass" 1 "Fail" 0 "Not_Diagnose_Yet" ;
VAL_ 1041 ElCmprBattURng_D_Falt 3 "NotUsed" 2 "Pass" 1 "Fail" 0 "Not_Diagnose_Yet" ;
VAL_ 1041 ElCmprBattSysU_D_Falt 3 "NotUsed" 2 "Pass" 1 "Fail" 0 "Not_Diagnose_Yet" ;
VAL_ 1041 ElCmprSysU_D_Falt 3 "NotUsed" 2 "Pass" 1 "Fail" 0 "Not_Diagnose_Yet" ;
VAL_ 1067 BattULoAux_I_Actl 4095 "Faulty" ;
VAL_ 1067 BattULoAux_D_Qlty 3 "OK" 2 "Not_Within_Specifications" 1 "Eval_In_Progress" 0 "Faulty" ;
VAL_ 1067 BattULoAux_U_Actl 255 "Faulty" ;
VAL_ 1067 BattULoAux_B_Falt 1 "Fault" 0 "No_Fault" ;
VAL_ 1040 ElCmprEnbl_B_Rq 1 "Enable" 0 "Disable" ;
VAL_ 1144 BattChrgTrgtSoC_D_Rq 7 "Percent_50" 6 "Percent_60" 5 "Percent_70" 4 "Percent_80" 3 "Percent_85" 2 "Percent_90" 1 "Percent_95" 0 "Percent_100" ;
VAL_ 1144 CabnEvapSovFront_B_Rq 1 "On" 0 "Off" ;
VAL_ 1144 HeatCoreSovRear_B_Rq 1 "On" 0 "Off" ;
VAL_ 1144 BattChlrSov_B_Rq 1 "On" 0 "Off" ;
VAL_ 1144 CabnEvapSovRear_B_Rq 1 "On" 0 "Off" ;
VAL_ 1144 BrkAppl_D_RqPt 3 "BrakesSlowRelease" 2 "BrakesFastRelease" 1 "BrakesEngage" 0 "NotActive" ;
VAL_ 1144 BattClntVlvOvrrd_D_Rq 3 "NotUsed" 2 "OverrideTbcvToChiller" 1 "OverrideTbcvToRadiator" 0 "NoOverrideToTbcvCLogic" ;
VAL_ 1144 BattTracChillerOn_B_Rq 1 "On" 0 "Off" ;
VAL_ 1144 BattTracChiller_D_Stat 3 "NotUsed" 2 "ChillerNotAvailable" 1 "ChillerBrieflyAvailable" 0 "ChillerAvailable" ;
VAL_ 1144 HtrnDcdcDis_B_Rq 1 "Yes" 0 "No" ;
VAL_ 1144 HtrnCnnctPwr_B_Stat 1 "Asserted" 0 "NotAsserted" ;
VAL_ 1144 PtcHtr_D_Stat 3 "Faulty" 2 "NotUsed" 1 "On" 0 "Off" ;
VAL_ 1144 WakeAlarm0_B_Typ 1 "CanAndEcuDriveCircuit" 0 "CanOnly" ;
VAL_ 1144 HtrnClntFlw_D_Rq 3 "High" 2 "Medium" 1 "Low" 0 "Off" ;
VAL_ 1144 BattTracDrvSustn_B_Rq 1 "Active" 0 "Inactive" ;
VAL_ 1144 CabinDrvSustn_B_Rq 1 "Active" 0 "Inactive" ;
VAL_ 1144 ChrgNowEvnt_B_Stat 1 "Active" 0 "Inactive" ;
VAL_ 1144 PreCondBatt_B_Actl 1 "On" 0 "Off" ;
VAL_ 1112 BattTracCnnct_D_Cmd 7 "NotUsed_3" 6 "NotUsed_2" 5 "NotUsed_1" 4 "WeldCheck" 3 "OkToDischarge" 2 "Closed" 1 "Precharge" 0 "Open" ;
VAL_ 1112 BattTracHvilOpen_B_Stat 1 "Open" 0 "Closed" ;
VAL_ 1112 BattTracCoolLvl_D_Rq 7 "Faulty" 6 "NotUsed" 5 "ChillerCoolingBattFirst" 4 "ChillerCoolingCabinFirst" 3 "ForcedCoolingRadiator" 2 "OpportunisticCoolingRad" 1 "CoolantFlowBypassLine" 0 "Off" ;
VAL_ 1112 BattTracDcdcDis_B_Rq 1 "Yes" 0 "No" ;
VAL_ 1112 HtrnClntPump_D_Stat 3 "Faulty" 2 "No_Data_Exists" 1 "On" 0 "Off" ;
VAL_ 139 AccButtnGpTogglePress2 1 "Pressed" 0 "Not_Pressed" ;
VAL_ 139 TjaButtnOnOffPress2 1 "Pressed" 0 "Not_Pressed" ;
VAL_ 139 ActvFrontSteMsgTxt_D_Rq 7 "Message7" 6 "Message6" 5 "Message5" 4 "Message4" 3 "Message3" 2 "Message2" 1 "Message1" 0 "NoMessage" ;
VAL_ 139 ActvFrontSteLck_D_Stat 3 "Test_passed" 2 "Test_failed" 1 "Test_cannot_run" 0 "Test_incomplete" ;
VAL_ 139 SelDrvMdeAdptSte_D_Stat 3 "Faulty" 2 "TemporarilyNotAvailable" 1 "Available" 0 "NotAvailable" ;
VAL_ 139 AslButtnOnOffPress2 1 "Button_Pressed" 0 "Button_Not_Pressed" ;
VAL_ 139 AslButtnOnOffCnclPres2 1 "Button_Pressed" 0 "Button_Not_Pressed" ;
VAL_ 139 CcButtnOnPress2 1 "Button_Pressed" 0 "Button_Not_Pressed" ;
VAL_ 139 CcButtnOnOffPress2 1 "Button_Pressed" 0 "Button_Not_Pressed" ;
VAL_ 139 CcButtnOnOffCnclPress2 1 "Button_Pressed" 0 "Button_Not_Pressed" ;
VAL_ 139 CcButtnOffPress2 1 "Button_Pressed" 0 "Button_Not_Pressed" ;
VAL_ 139 CcAsllButtnResPress2 1 "Button_Pressed" 0 "Button_Not_Pressed" ;
VAL_ 139 CcAslButtnSetPress2 1 "Button_Pressed" 0 "Button_Not_Pressed" ;
VAL_ 139 CcAslButtnSetIncPress2 1 "Button_Pressed" 0 "Button_Not_Pressed" ;
VAL_ 139 CcAslButtnSetDecPress2 1 "Button_Pressed" 0 "Button_Not_Pressed" ;
VAL_ 139 CcAslButtnResIncPress2 1 "Button_Pressed" 0 "Button_Not_Pressed" ;
VAL_ 139 CcAslButtnResDecPress2 1 "Button_Pressed" 0 "Button_Not_Pressed" ;
VAL_ 139 CcAslButtnOnPress2 1 "Button_Pressed" 0 "Button_Not_Pressed" ;
VAL_ 139 CcAslButtnOnOffCncl2 1 "Button_Pressed" 0 "Button_Not_Pressed" ;
VAL_ 139 CcAslButtnOffCnclPres2 1 "Button_Pressed" 0 "Button_Not_Pressed" ;
VAL_ 139 CcAslButtnIndxIncPres2 1 "Button_Pressed" 0 "Button_Not_Pressed" ;
VAL_ 139 CcAslButtnIndxDecPres2 1 "Button_Pressed" 0 "Button_Not_Pressed" ;
VAL_ 139 CcAslButtnDeny_B_Actl2 1 "Yes" 0 "No" ;
VAL_ 139 CcAslButtnCnclResPres2 1 "Button_Pressed" 0 "Button_Not_Pressed" ;
VAL_ 139 CcAslButtnCnclPress2 1 "Button_Pressed" 0 "Button_Not_Pressed" ;
VAL_ 139 AccButtnGapIncPress2 1 "Button_Pressed" 0 "Button_Not_Pressed" ;
VAL_ 139 AccButtnGapDecPress2 1 "Button_Pressed" 0 "Button_Not_Pressed" ;
VAL_ 1121 SelDrvMdeSwtchOk_D_Stat 3 "Faulty" 2 "Pressed" 1 "NotPressed" 0 "Null" ;
VAL_ 1121 AutoHoldSwtch_D_Stat2 3 "Faulty" 2 "NotUsed" 1 "Pressed" 0 "Not_Pressed" ;
VAL_ 1121 PrkAidSwtch_D_RqDrv3 1 "Pressed" 0 "Not_Pressed" ;
VAL_ 1121 ApaSwtch_D_RqDrv3 3 "NotUsed2" 2 "NotUsed1" 1 "Pressed" 0 "Not_Pressed" ;
VAL_ 1121 StopStrtDrvMde_B_RqBtn2 1 "Pressed" 0 "Not_Pressed" ;
VAL_ 1121 SelDrvMdeSwtch_D_Stat 3 "Faulty" 2 "SwitchState2" 1 "SwitchState1" 0 "NotPressed" ;
VAL_ 1121 SelDrvMdeCnt_D_Stat 4 "FourCounts" 3 "ThreeCounts" 2 "TwoCounts" 1 "OneCount" 0 "ZeroCounts" 7 "SevenOrMoreCounts" 6 "SixCounts" 5 "FiveCounts" ;
VAL_ 1120 DrvSlipCtlMde_B_Rq3 1 "Pressed" 0 "Not_Pressed" ;
VAL_ 1120 HybMdeSwtch_B_Rq 1 "Pressed" 0 "Not_Pressed" ;
VAL_ 1120 AwdLck_D_RqDrv 3 "Faulty" 2 "NoRequest" 1 "On" 0 "Off" ;
VAL_ 1120 TrailCtlSwtch_B_Stat3 1 "Pressed" 0 "Not_Pressed" ;
VAL_ 1120 RearDiffLck_D_RqDrv 3 "Faulty" 2 "NoRequest" 1 "On" 0 "Off" ;
VAL_ 1120 AwdMde_D_RqDrv 7 "Faulty" 6 "NotUsed2" 5 "NoRequest" 4 "Neutral" 3 "FourByFourLow" 2 "FourByFourHigh" 1 "FourByFourAuto" 0 "FourByTwo" ;
VAL_ 1120 HdcSwtchPos_B_Actl 1 "Pressed" 0 "Not_Pressed" ;
VAL_ 1050 CamraRearBttn_D_Stat 1 "Pressed" 0 "Not_Pressed" ;
VAL_ 1050 TrailCtlSwtch_B_Stat 1 "Pressed" 0 "Not_Pressed" ;
VAL_ 1050 CamraFrntBttn_D_Stat 1 "Pressed" 0 "Not_Pressed" ;
VAL_ 1050 AutoHoldSwtch_D_Stat 3 "Faulty" 2 "NotUsed" 1 "Pressed" 0 "Not_Pressed" ;
VAL_ 1050 EcoInhbt_B_RqHvac 1 "Yes" 0 "No" ;
VAL_ 1050 LpdbPtc3_B_Rq 1 "On" 0 "Off" ;
VAL_ 1050 LpdbPtc2_B_Rq 1 "On" 0 "Off" ;
VAL_ 1050 LpdbPtc1_B_Rq 1 "On" 0 "Off" ;
VAL_ 1050 LpdbHeatWiprPrk_B_Rq 1 "On" 0 "Off" ;
VAL_ 1050 LpdbDfrstRearOn_B_Rq 1 "On" 0 "Off" ;
VAL_ 1050 LpdbDfrstFrOn_B_Rq 1 "On" 0 "Off" ;
VAL_ 1050 LpdbDfrstFlOn_B_Rq 1 "On" 0 "Off" ;
VAL_ 1050 LpdbAuxBlwr_B_Rq 1 "On" 0 "Off" ;
VAL_ 1050 PrkAidSwtch_D_RqDrv 1 "Pressed" 0 "Not_Pressed" ;
VAL_ 1050 SteWhlHeat_D_Rq 15 "NotUsed6" 14 "NotUsed5" 13 "NotUsed4" 12 "NotUsed3" 11 "NotUsed2" 10 "NotUsed1" 9 "Reserved_3" 8 "Reserved_2" 7 "Reserved_1" 6 "Level_3_Heating" 5 "Level_3_Heating_LS" 4 "Level_2_Heating" 3 "Level_2_Heating_LS" 2 "Level_1_Heating" 1 "Level_1_Heating_LS" 0 "Off" ;
VAL_ 1050 MirrorHeatOn_B_Rq 1 "True" 0 "False" ;
VAL_ 1050 Remote_Start_QuietMode 1 "Quiet" 0 "Not_Quiet" ;
VAL_ 1050 DrvSlipCtlMde_B_Rq 1 "Pressed" 0 "Not_Pressed" ;
VAL_ 1050 Outside_Air_Temp_Stat 255 "Invalid" 254 "Unknown" ;
VAL_ 942 PrkAidDrvDir_D_Stat 7 "NotUsed_2" 6 "NotUsed_1" 5 "BackwardNegative" 4 "ForwardNegative" 3 "BackwardPositive" 2 "ForwardPositive" 1 "NoMotion" 0 "DirectionNotKnown" ;
VAL_ 1113 TrlrTrgtAcquire_D_Stat 7 "Faulty" 6 "NotUsed_2" 5 "NotUsed_1" 4 "RVCforTBA_Activated" 3 "Processing" 2 "TargetNotAcquired" 1 "TargetAcquired" 0 "Null" ;
VAL_ 1113 TrlrAnOffstDir_D_Calc 3 "NotUSed" 2 "Right" 1 "Left_or_Center" 0 "Null" ;
VAL_ 1113 TrlrAnCalib_B_Complt 1 "Yes" 0 "No" ;
VAL_ 1113 TrlrRvrse_D_Stat 3 "Faulty" 2 "TrailerReverseGuidanceLite" 1 "On" 0 "Off" ;
VAL_ 1113 TrlrAid_D2_Stat 15 "Faulty" 14 "NotUsed_4" 13 "NotUsed_3" 12 "NotUsed_2" 11 "NotUsed_1" 10 "DirtyCamera" 9 "IncorrectLighting" 8 "TrackingLost" 7 "TrackingUnknownConfidence" 6 "TrackingHighConfidence" 5 "TrackingMediumConfidence" 4 "TrackingLowConfidence" 3 "TurnRequested" 2 "DriveStraighRequested" 1 "Initializing" 0 "NotTracking" ;
VAL_ 1113 TrlrAid_An3_Actl 2047 "Faulty" ;
VAL_ 1113 TrlrAid_AnRate2_Actl 1023 "Faulty" ;
VAL_ 1113 HitchToVehAxle_L_Calc 255 "Faulty" ;
VAL_ 1105 TrlrRvrseMsgTxt_D2_Rq 31 "Message31" 30 "Message30" 29 "Message29" 28 "Message28" 27 "Message27" 26 "Message26" 25 "Message25" 24 "Message24" 23 "Message23" 22 "Message22" 21 "Message21" 20 "Message20" 19 "Message19" 18 "Message18" 17 "Message17" 16 "Message16" 15 "Message15" 14 "Message14" 13 "Message13" 12 "Message12" 11 "Message11" 10 "Message10" 9 "Message9" 8 "Message8" 7 "Message7" 6 "Message6" 5 "Message5" 4 "Message4" 3 "Message3" 2 "Message2" 1 "Message1" 0 "NoMessage" ;
VAL_ 1105 TrlrRvrseEnbl_D2_Stat 7 "NotUsed" 6 "TbaActiveExpertActive" 5 "TbaActiveExpertAvail" 4 "TbaOffTrgActive" 3 "TbaOffTrgSetup" 2 "TbaSetup" 1 "TbaActive" 0 "Inactive" ;
VAL_ 1105 RbaMsg_D_Rq 3 "Faulty" 2 "Unavailable" 1 "Off" 0 "Null" ;
VAL_ 1105 BrkDecel_B_RqRba 1 "Enable" 0 "Disable" ;
VAL_ 1105 BrkEnbl_B_RqRba 1 "Enable" 0 "Disable" ;
VAL_ 1105 Rba_D_Stat 3 "NotUsed" 2 "Disabled" 1 "On" 0 "Off" ;
VAL_ 1105 RbaAlrt_D_Dsply 3 "Both" 2 "Text" 1 "Graphic" 0 "Off" ;
VAL_ 1105 RbaMnu_D_Rq 3 "NotUsed" 2 "Active" 1 "Inactive" 0 "None" ;
VAL_ 1105 RbaSys_D_Stat 3 "Faulty" 2 "Available" 1 "Suspended" 0 "Disabled" ;
VAL_ 1105 CamraRemoteStat_B_Actl 1 "Supported" 0 "NotSupported" ;
VAL_ 1105 CamraFrntStat_D_Stat 3 "No_Data_Present" 2 "NotUsed" 1 "On" 0 "Off" ;
VAL_ 1105 TrlrHitchLamp_D_Rq2 1 "On" 0 "Off" ;
VAL_ 1105 TrlrRvrseMsgTxt_D_Rq 31 "Message31" 30 "Message30" 29 "Message29" 28 "Message28" 27 "Message27" 26 "Message26" 25 "Message25" 24 "Message24" 23 "Message23" 22 "Message22" 21 "Message21" 20 "Message20" 19 "Message19" 18 "Message18" 17 "Message17" 16 "Message16" 15 "Message15" 14 "Message14" 13 "Message13" 12 "Message12" 11 "Message11" 10 "Message10" 9 "Message9" 8 "Message8" 7 "Message7" 6 "Message6" 5 "Message5" 4 "Message4" 3 "Message3" 2 "Message2" 1 "Message1" 0 "NoMessage" ;
VAL_ 938 SidePrkSnsR2_D_Stat 15 "NotUsed" 14 "NotFullyScannedYet" 13 "NoObjectInSector" 12 "Zone12" 11 "Zone11" 10 "Zone10" 9 "Zone9" 8 "Zone8" 7 "Zone7" 6 "Zone6" 5 "Zone5" 4 "Zone4" 3 "Zone3" 2 "Zone2" 1 "Zone1" 0 "Off" ;
VAL_ 938 SidePrkSnsR1_D_Stat 15 "NotUsed" 14 "NotFullyScannedYet" 13 "NoObjectInSector" 12 "Zone12" 11 "Zone11" 10 "Zone10" 9 "Zone9" 8 "Zone8" 7 "Zone7" 6 "Zone6" 5 "Zone5" 4 "Zone4" 3 "Zone3" 2 "Zone2" 1 "Zone1" 0 "Off" ;
VAL_ 938 SidePrkSnsL2_D_Stat 15 "NotUsed" 14 "NotFullyScannedYet" 13 "NoObjectInSector" 12 "Zone12" 11 "Zone11" 10 "Zone10" 9 "Zone9" 8 "Zone8" 7 "Zone7" 6 "Zone6" 5 "Zone5" 4 "Zone4" 3 "Zone3" 2 "Zone2" 1 "Zone1" 0 "Off" ;
VAL_ 938 ApaMde_D_Stat 7 "NotUsed3" 6 "NotUsed2" 5 "NotUsed1" 4 "POA" 3 "PPA" 2 "SAPP" 1 "Off" 0 "Null" ;
VAL_ 938 ApaActvSd_D_Actl 3 "Dirver_Side" 2 "Passenger_Side" 1 "No_Side" 0 "Null" ;
VAL_ 938 PrkAidSwtch_B_Stat 1 "Pressed" 0 "Not_Pressed" ;
VAL_ 938 ApaMde_D_Avail 15 "NotUsed7" 14 "NotUsed6" 13 "NotUsed5" 12 "NotUsed4" 11 "NotUsed3" 10 "NotUsed2" 9 "NotUsed1" 8 "PPA_POA" 7 "SAPP_POA" 6 "POA" 5 "PPA" 4 "SAPP" 3 "SAPP_PPA_POA" 2 "SAPP_PPA" 1 "None" 0 "Null" ;
VAL_ 938 PrkAidSnsFrSide_D_Stat 15 "Zone_15" 14 "Zone_14" 13 "Zone_13" 12 "Zone_12" 11 "Zone_11" 10 "Zone_10" 9 "Zone_9" 8 "Zone_8" 7 "Zone_7" 6 "Zone_6" 5 "Zone_5" 4 "Zone_4" 3 "Zone_3" 2 "Zone_2" 1 "Zone_1" 0 "Off" ;
VAL_ 938 PrkAidSnsFrCrnr_D_Stat 15 "Zone_15" 14 "Zone_14" 13 "Zone_13" 12 "Zone_12" 11 "Zone_11" 10 "Zone_10" 9 "Zone_9" 8 "Zone_8" 7 "Zone_7" 6 "Zone_6" 5 "Zone_5" 4 "Zone_4" 3 "Zone_3" 2 "Zone_2" 1 "Zone_1" 0 "Off" ;
VAL_ 938 PrkAidSnsFrCntr_D_Stat 15 "Zone_15" 14 "Zone_14" 13 "Zone_13" 12 "Zone_12" 11 "Zone_11" 10 "Zone_10" 9 "Zone_9" 8 "Zone_8" 7 "Zone_7" 6 "Zone_6" 5 "Zone_5" 4 "Zone_4" 3 "Zone_3" 2 "Zone_2" 1 "Zone_1" 0 "Off" ;
VAL_ 938 PrkAidSnsFlSide_D_Stat 15 "Zone_15" 14 "Zone_14" 13 "Zone_13" 12 "Zone_12" 11 "Zone_11" 10 "Zone_10" 9 "Zone_9" 8 "Zone_8" 7 "Zone_7" 6 "Zone_6" 5 "Zone_5" 4 "Zone_4" 3 "Zone_3" 2 "Zone_2" 1 "Zone_1" 0 "Off" ;
VAL_ 938 PrkAidSnsFlCrnr_D_Stat 15 "Zone_15" 14 "Zone_14" 13 "Zone_13" 12 "Zone_12" 11 "Zone_11" 10 "Zone_10" 9 "Zone_9" 8 "Zone_8" 7 "Zone_7" 6 "Zone_6" 5 "Zone_5" 4 "Zone_4" 3 "Zone_3" 2 "Zone_2" 1 "Zone_1" 0 "Off" ;
VAL_ 938 PrkAidSnsFlCntr_D_Stat 15 "Zone_15" 14 "Zone_14" 13 "Zone_13" 12 "Zone_12" 11 "Zone_11" 10 "Zone_10" 9 "Zone_9" 8 "Zone_8" 7 "Zone_7" 6 "Zone_6" 5 "Zone_5" 4 "Zone_4" 3 "Zone_3" 2 "Zone_2" 1 "Zone_1" 0 "Off" ;
VAL_ 938 PrkBrkEl_B_RqFap 1 "Yes" 0 "No" ;
VAL_ 938 RpaChime_D_Rq 15 "Zone15_Chime" 14 "Zone14_Chime" 13 "Zone13_Chime" 12 "Zone12_Chime" 11 "Zone11_Chime" 10 "Zone10_Chime" 9 "Zone9_Chime" 8 "Zone8_Chime" 7 "Zone7_Chime" 6 "Zone6_Chime" 5 "Zone5_Chime" 4 "Zone4_Chime" 3 "Zone3_Chime" 2 "Zone2_Chime" 1 "Zone1_Chime" 0 "No_Chime" ;
VAL_ 938 FpaChime_D_Rq 15 "Zone15_Chime" 14 "Zone14_Chime" 13 "Zone13_Chime" 12 "Zone12_Chime" 11 "Zone11_Chime" 10 "Zone10_Chime" 9 "Zone9_Chime" 8 "Zone8_Chime" 7 "Zone7_Chime" 6 "Zone6_Chime" 5 "Zone5_Chime" 4 "Zone4_Chime" 3 "Zone3_Chime" 2 "Zone2_Chime" 1 "Zone1_Chime" 0 "No_Chime" ;
VAL_ 938 PrkAidMsgTxt_D_Rq 15 "All_Sns_Blk" 14 "R_Sns_ON_F_Sns_Blk" 13 "R_Sns_Blk_F_Sns_ON" 12 "R_Sns_Inactive_Trlr_atch" 11 "Not_Avail_Trlr_attchd" 10 "Fail_Mode_no_Chime" 9 "Fail_Mode_with_Chime" 8 "R_Sns_Trlr_F_Sns_Blk" 7 "NotUsed3" 6 "Park_Sys_Alternate_Mode" 5 "R_Snsrs_On_F_Snsrs_On" 4 "NotUsed2" 3 "Reset_Message_Warn" 2 "R_Snsrs_Off_F_Snsrs_On" 1 "R_Snsrs_On_F_Snsrs_Off" 0 "All_Park_Sensors_Off" ;
VAL_ 938 SidePrkSnsL1_D_Stat 15 "NotUsed" 14 "NotFullyScannedYet" 13 "NoObjectInSector" 12 "Zone12" 11 "Zone11" 10 "Zone10" 9 "Zone9" 8 "Zone8" 7 "Zone7" 6 "Zone6" 5 "Zone5" 4 "Zone4" 3 "Zone3" 2 "Zone2" 1 "Zone1" 0 "Off" ;
VAL_ 938 PrkAidAudioMute_B_Rq 1 "Enable" 0 "Disable" ;
VAL_ 939 SidePrkSnsR4_D_Stat 15 "NotUsed" 14 "NotFullyScannedYet" 13 "NoObjectInSector" 12 "Zone12" 11 "Zone11" 10 "Zone10" 9 "Zone9" 8 "Zone8" 7 "Zone7" 6 "Zone6" 5 "Zone5" 4 "Zone4" 3 "Zone3" 2 "Zone2" 1 "Zone1" 0 "Off" ;
VAL_ 939 SidePrkSnsR3_D_Stat 15 "NotUsed" 14 "NotFullyScannedYet" 13 "NoObjectInSector" 12 "Zone12" 11 "Zone11" 10 "Zone10" 9 "Zone9" 8 "Zone8" 7 "Zone7" 6 "Zone6" 5 "Zone5" 4 "Zone4" 3 "Zone3" 2 "Zone2" 1 "Zone1" 0 "Off" ;
VAL_ 939 SidePrkSnsL4_D_Stat 15 "NotUsed" 14 "NotFullyScannedYet" 13 "NoObjectInSector" 12 "Zone12" 11 "Zone11" 10 "Zone10" 9 "Zone9" 8 "Zone8" 7 "Zone7" 6 "Zone6" 5 "Zone5" 4 "Zone4" 3 "Zone3" 2 "Zone2" 1 "Zone1" 0 "Off" ;
VAL_ 939 SidePrkSnsL3_D_Stat 15 "NotUsed" 14 "NotFullyScannedYet" 13 "NoObjectInSector" 12 "Zone12" 11 "Zone11" 10 "Zone10" 9 "Zone9" 8 "Zone8" 7 "Zone7" 6 "Zone6" 5 "Zone5" 4 "Zone4" 3 "Zone3" 2 "Zone2" 1 "Zone1" 0 "Off" ;
VAL_ 939 PrkAidChime_D_Stat 3 "Fault" 2 "No_Data_Exists" 1 "On" 0 "Off" ;
VAL_ 939 PrkAidSnsRlCntr_D_Stat 15 "Zone_15" 14 "Zone_14" 13 "Zone_13" 12 "Zone_12" 11 "Zone_11" 10 "Zone_10" 9 "Zone_9" 8 "Zone_8" 7 "Zone_7" 6 "Zone_6" 5 "Zone_5" 4 "Zone_4" 3 "Zone_3" 2 "Zone_2" 1 "Zone_1" 0 "Off" ;
VAL_ 939 PrkAidSnsRrSide_D_Stat 15 "Zone_15" 14 "Zone_14" 13 "Zone_13" 12 "Zone_12" 11 "Zone_11" 10 "Zone_10" 9 "Zone_9" 8 "Zone_8" 7 "Zone_7" 6 "Zone_6" 5 "Zone_5" 4 "Zone_4" 3 "Zone_3" 2 "Zone_2" 1 "Zone_1" 0 "Off" ;
VAL_ 939 PrkAidSnsRrCrnr_D_Stat 15 "Zone_15" 14 "Zone_14" 13 "Zone_13" 12 "Zone_12" 11 "Zone_11" 10 "Zone_10" 9 "Zone_9" 8 "Zone_8" 7 "Zone_7" 6 "Zone_6" 5 "Zone_5" 4 "Zone_4" 3 "Zone_3" 2 "Zone_2" 1 "Zone_1" 0 "Off" ;
VAL_ 939 PrkAidSnsRrCntr_D_Stat 15 "Zone_15" 14 "Zone_14" 13 "Zone_13" 12 "Zone_12" 11 "Zone_11" 10 "Zone_10" 9 "Zone_9" 8 "Zone_8" 7 "Zone_7" 6 "Zone_6" 5 "Zone_5" 4 "Zone_4" 3 "Zone_3" 2 "Zone_2" 1 "Zone_1" 0 "Off" ;
VAL_ 939 PrkAidSnsRlSide_D_Stat 15 "Zone_15" 14 "Zone_14" 13 "Zone_13" 12 "Zone_12" 11 "Zone_11" 10 "Zone_10" 9 "Zone_9" 8 "Zone_8" 7 "Zone_7" 6 "Zone_6" 5 "Zone_5" 4 "Zone_4" 3 "Zone_3" 2 "Zone_2" 1 "Zone_1" 0 "Off" ;
VAL_ 939 PrkAidSnsRlCrnr_D_Stat 15 "Zone_15" 14 "Zone_14" 13 "Zone_13" 12 "Zone_12" 11 "Zone_11" 10 "Zone_10" 9 "Zone_9" 8 "Zone_8" 7 "Zone_7" 6 "Zone_6" 5 "Zone_5" 4 "Zone_4" 3 "Zone_3" 2 "Zone_2" 1 "Zone_1" 0 "Off" ;
VAL_ 939 PrkAidRear_D_Stat 3 "Faulted" 2 "Unused" 1 "Enabled" 0 "Disabled" ;
VAL_ 939 PrkAidFront_D_Stat 3 "Faulted" 2 "Unused" 1 "Enabled" 0 "Disabled" ;
VAL_ 939 PrkAid_D_Falt 7 "NotUsed2" 6 "NotUsed1" 5 "Failure_Front_PSM_Sensors" 4 "No_Data_Exists" 3 "Failure_Rear_Sensors" 2 "Speaker_Fault" 1 "ECU_Fault" 0 "No_Fault" ;
VAL_ 939 ApaLongCtrlEnbl_D_Rq 1 "Enable" 0 "Disable" ;
VAL_ 939 PrkAidLamp_D_Rq 3 "Not_Used" 2 "Flash" 1 "On" 0 "Off" ;
VAL_ 937 TrnRng_D_RqFap 7 "NotUsed3" 6 "NotUsed2" 5 "NotUsed1" 4 "Backwards" 3 "Forwards" 2 "NoMotion" 1 "Immobilize" 0 "NoRequest" ;
VAL_ 937 FapLcDistToObj_L_Actl 255 "Faulty" 254 "NoDataExists" ;
